VERSION ""

NS_ :

BS_:

BU_: PowertrainControlModule AtmosphericSensor SafetyRestraintSystem2 Aftertreatment_2_GasOutlet Aftertreatment_2_GasIntake DieselParticulateFilterControl Turbocharger SafetyRestraintSystem1 CabDisplay2 Aftertreatment_1_GasOutlet Aftertreatment_1_GasIntake OnBoardDataLogger OffBoardDiagnosticTool2 OffBoardDiagnosticTool1 FileServer ParkingBrakeController SeatController2 FanDriveController SteeringColumnUnit CommunicationUnitRadio CommunicationUnitSatellite CommunicationUnitCellular PropulsionBatteryCharger ChassisController2 ChassisController1 EngineValveControl AuxiliaryHeater2 AuxiliaryHeater1 ClutchUnit RampControl InformationSystem1 SuspensionSystemController2 OilSensor VehicleDynamicStability ExhaustEmissionController TransmissionDisplay2 TransmissionDisplay1 ClimateControl2 WaterPumpController RearAxleSteeringController LightingOperatorControl SeatController1 IgnitionController2 IgnitionController1 TirePressureController CabController2 CabController1 PneumaticSystemController SuspensionSystemController1 HydraulicPumpController EnduranceBrakingSystem RetarderExhaustEngine2 OnBoardDiagnosticUnit HeadwayController RetarderExhaustEngine1 CabDisplay1 ManagementComputer VirtualTerminal OffVehicleGateway PowerTakeOffFront HitchControl AuxiliaryValveControl BodyController TractorTrailerBridge1 StarterSystem ElectricalSystem VehicleSecurity VehicleNavigation AerodynamicControl ElectricalChargingSystem ClimateControl1 TripRecorder InstrumentCluster SuspensionDriveAxle2 SuspensionDriveAxle1 SuspensionSteerAxle SteeringController FuelSystem CruiseControl RetarderDriveline RetarderEngine BrakesDriveAxle2 BrakesDriveAxle1 BrakesSystemController BrakesSteerAxle AxleDrive2 AxleDrive1 AxleSteering PowerTakeOff ShiftConsoleSecondary ShiftConsolePrimary Transmission2 Transmission1 Engine2 Engine1

BO_ 2364677630 HVESP7MS1: 8 Vector__XXX
 SG_ Module32OperationalStatus : 62|2@1+ (1,0) [0|3] "" Vector__XXX
 SG_ Module31OperationalStatus : 60|2@1+ (1,0) [0|3] "" Vector__XXX
 SG_ Module30OperationalStatus : 58|2@1+ (1,0) [0|3] "" Vector__XXX
 SG_ Module29OperationalStatus : 56|2@1+ (1,0) [0|3] "" Vector__XXX
 SG_ Module28OperationalStatus : 54|2@1+ (1,0) [0|3] "" Vector__XXX
 SG_ Module27OperationalStatus : 52|2@1+ (1,0) [0|3] "" Vector__XXX
 SG_ Module26OperationalStatus : 50|2@1+ (1,0) [0|3] "" Vector__XXX
 SG_ Module25OperationalStatus : 48|2@1+ (1,0) [0|3] "" Vector__XXX
 SG_ Module24OperationalStatus : 46|2@1+ (1,0) [0|3] "" Vector__XXX
 SG_ Module23OperationalStatus : 44|2@1+ (1,0) [0|3] "" Vector__XXX
 SG_ Module22OperationalStatus : 42|2@1+ (1,0) [0|3] "" Vector__XXX
 SG_ Module21OperationalStatus : 40|2@1+ (1,0) [0|3] "" Vector__XXX
 SG_ Module20OperationalStatus : 38|2@1+ (1,0) [0|3] "" Vector__XXX
 SG_ Module19OperationalStatus : 36|2@1+ (1,0) [0|3] "" Vector__XXX
 SG_ Module18OperationalStatus : 34|2@1+ (1,0) [0|3] "" Vector__XXX
 SG_ Module17OperationalStatus : 32|2@1+ (1,0) [0|3] "" Vector__XXX
 SG_ Module16OperationalStatus : 30|2@1+ (1,0) [0|3] "" Vector__XXX
 SG_ Module15OperationalStatus : 28|2@1+ (1,0) [0|3] "" Vector__XXX
 SG_ Module14OperationalStatus : 26|2@1+ (1,0) [0|3] "" Vector__XXX
 SG_ Module13OperationalStatus : 24|2@1+ (1,0) [0|3] "" Vector__XXX
 SG_ Module12OperationalStatus : 22|2@1+ (1,0) [0|3] "" Vector__XXX
 SG_ Module11OperationalStatus : 20|2@1+ (1,0) [0|3] "" Vector__XXX
 SG_ Module10OperationalStatus : 18|2@1+ (1,0) [0|3] "" Vector__XXX
 SG_ Module9OperationalStatus : 16|2@1+ (1,0) [0|3] "" Vector__XXX
 SG_ Module8OperationalStatus : 14|2@1+ (1,0) [0|3] "" Vector__XXX
 SG_ Module7OperationalStatus : 12|2@1+ (1,0) [0|3] "" Vector__XXX
 SG_ Module6OperationalStatus : 10|2@1+ (1,0) [0|3] "" Vector__XXX
 SG_ Module5OperationalStatus : 8|2@1+ (1,0) [0|3] "" Vector__XXX
 SG_ Module4OperationalStatus : 6|2@1+ (1,0) [0|3] "" Vector__XXX
 SG_ Module3OperationalStatus : 4|2@1+ (1,0) [0|3] "" Vector__XXX
 SG_ Module2OperationalStatus : 2|2@1+ (1,0) [0|3] "" Vector__XXX
 SG_ Module1OperationalStatus : 0|2@1+ (1,0) [0|3] "" Vector__XXX

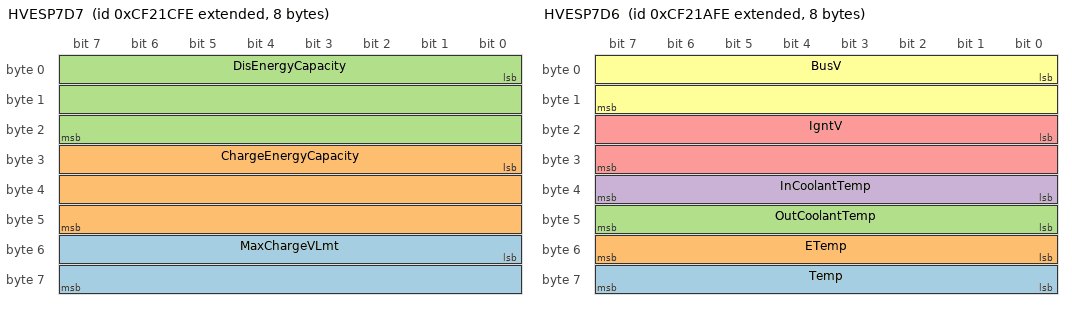
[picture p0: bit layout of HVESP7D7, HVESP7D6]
BO_ 2364677374 HVESP7D7: 8 Vector__XXX
 SG_ MaxChargeVLmt : 48|16@1+ (0.05,0) [0|3212.75] "V" Vector__XXX
 SG_ ChargeEnergyCapacity : 24|24@1+ (0.001,0) [0|16449.535] "kWh" Vector__XXX
 SG_ DisEnergyCapacity : 0|24@1+ (0.001,0) [0|16449.535] "kWh" Vector__XXX

BO_ 2364677118 HVESP7S1: 8 Vector__XXX
 SG_ Status1CRC : 56|8@1+ (1,0) [0|255] "" Vector__XXX
 SG_ Status1Counter : 52|4@1+ (1,0) [0|15] "" Vector__XXX
 SG_ OperationalStatus : 44|4@1+ (1,0) [0|15] "" Vector__XXX
 SG_ HVBusConnectionStatus : 40|4@1+ (1,0) [0|15] "" Vector__XXX
 SG_ InternalChargerStatus : 32|2@1+ (1,0) [0|3] "" Vector__XXX
 SG_ CellBalancingActive : 30|2@1+ (1,0) [0|3] "" Vector__XXX
 SG_ CellBalanceStatus : 28|2@1+ (1,0) [0|3] "" Vector__XXX
 SG_ StOfChargeStatus : 24|4@1+ (1,0) [0|15] "" Vector__XXX
 SG_ InertiaSwStatus : 22|2@1+ (1,0) [0|3] "" Vector__XXX
 SG_ HVILStatus : 20|2@1+ (1,0) [0|3] "" Vector__XXX
 SG_ HVBusPassiveIsolTestStatus : 16|4@1+ (1,0) [0|15] "" Vector__XXX
 SG_ HVBusActiveIsolTestStatus : 12|4@1+ (1,0) [0|15] "" Vector__XXX
 SG_ CenterOfPackContactorSt : 10|2@1+ (1,0) [0|3] "" Vector__XXX
 SG_ HVBusPreChargeRelaySt : 8|2@1+ (1,0) [0|3] "" Vector__XXX
 SG_ HVBusDisconnectForewarning : 4|4@1+ (1,0) [0|15] "" Vector__XXX
 SG_ HVBusContactorSt14086 : 2|2@1+ (1,0) [0|3] "" Vector__XXX
 SG_ HVBusContactorSt : 0|2@1+ (1,0) [0|3] "" Vector__XXX

BO_ 2364676862 HVESP7D6: 8 Vector__XXX
 SG_ Temp : 56|8@1+ (1,-40) [-40|210] "°C" Vector__XXX
 SG_ ETemp : 48|8@1+ (1,-40) [-40|210] "°C" Vector__XXX
 SG_ OutCoolantTemp : 40|8@1+ (1,-40) [-40|210] "°C" Vector__XXX
 SG_ InCoolantTemp : 32|8@1+ (1,-40) [-40|210] "°C" Vector__XXX
 SG_ IgntV : 16|16@1+ (0.01,0) [0|642.55] "V" Vector__XXX
 SG_ BusV : 0|16@1+ (0.05,0) [0|3212.75] "V" Vector__XXX

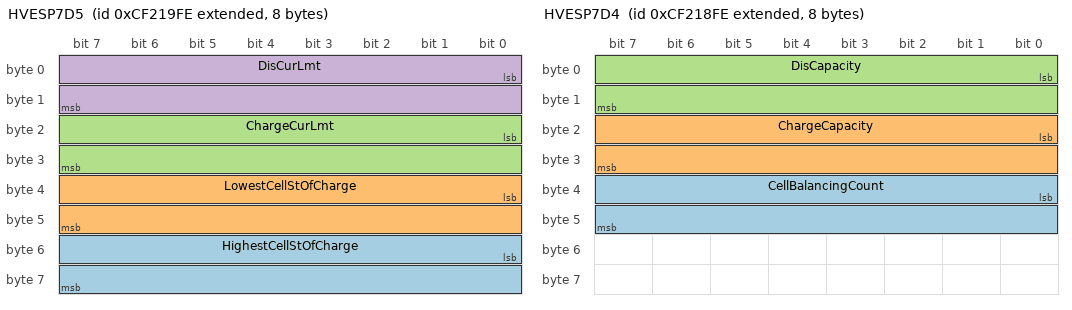
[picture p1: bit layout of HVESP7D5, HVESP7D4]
BO_ 2364676606 HVESP7D5: 8 Vector__XXX
 SG_ HighestCellStOfCharge : 48|16@1+ (0.0015625,0) [0|100.3984375] "%" Vector__XXX
 SG_ LowestCellStOfCharge : 32|16@1+ (0.0015625,0) [0|100.3984375] "%" Vector__XXX
 SG_ ChargeCurLmt : 16|16@1+ (0.05,-1600) [0|1612.75] "A" Vector__XXX
 SG_ DisCurLmt : 0|16@1+ (0.05,-1600) [-1600|0] "A" Vector__XXX

BO_ 2364676350 HVESP7D4: 8 Vector__XXX
 SG_ CellBalancingCount : 32|16@1+ (1,0) [0|64255] "" Vector__XXX
 SG_ ChargeCapacity : 16|16@1+ (0.01,0) [0|642.55] "Ah" Vector__XXX
 SG_ DisCapacity : 0|16@1+ (0.01,0) [0|642.55] "Ah" Vector__XXX

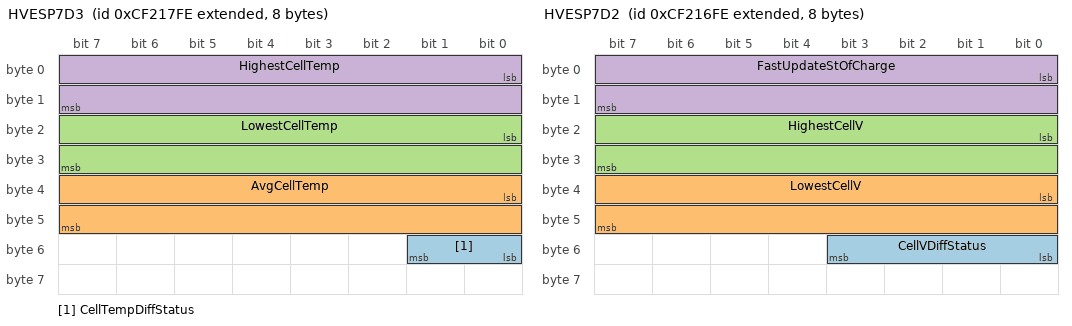
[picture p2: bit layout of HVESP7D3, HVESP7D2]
BO_ 2364676094 HVESP7D3: 8 Vector__XXX
 SG_ CellTempDiffStatus : 48|2@1+ (1,0) [0|3] "" Vector__XXX
 SG_ AvgCellTemp : 32|16@1+ (0.03125,-273) [-273|1734.96875] "°C" Vector__XXX
 SG_ LowestCellTemp : 16|16@1+ (0.03125,-273) [-273|1734.96875] "°C" Vector__XXX
 SG_ HighestCellTemp : 0|16@1+ (0.03125,-273) [-273|1734.96875] "°C" Vector__XXX

BO_ 2364675838 HVESP7D2: 8 Vector__XXX
 SG_ CellVDiffStatus : 48|4@1+ (1,0) [0|15] "" Vector__XXX
 SG_ LowestCellV : 32|16@1+ (0.001,0) [0|64.255] "V" Vector__XXX
 SG_ HighestCellV : 16|16@1+ (0.001,0) [0|64.255] "V" Vector__XXX
 SG_ FastUpdateStOfCharge : 0|16@1+ (0.0015625,0) [0|100.3984375] "%" Vector__XXX

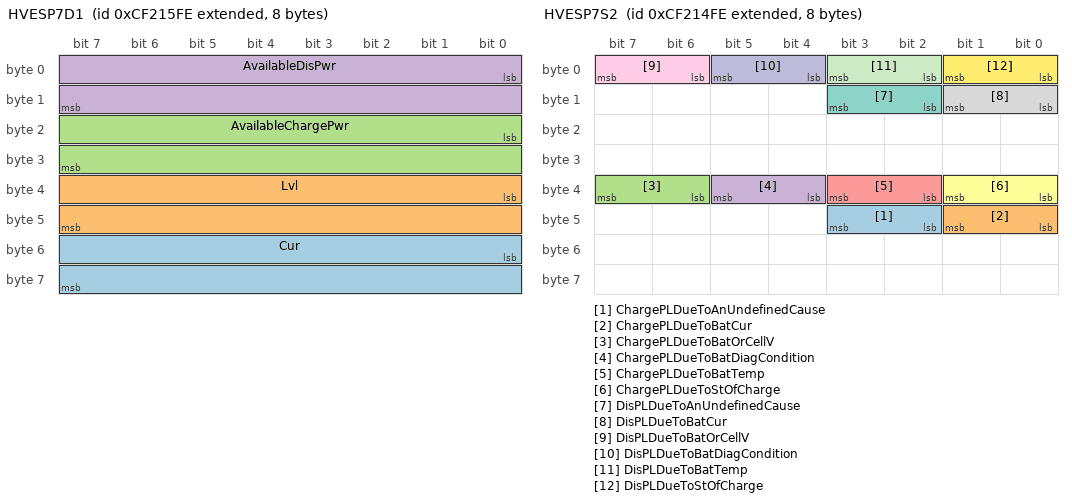
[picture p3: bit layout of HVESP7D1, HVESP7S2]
BO_ 2364675582 HVESP7D1: 8 Vector__XXX
 SG_ Cur : 48|16@1+ (0.05,-1600) [-1600|1612.75] "A" Vector__XXX
 SG_ Lvl : 32|16@1+ (0.05,0) [0|3212.75] "V" Vector__XXX
 SG_ AvailableChargePwr : 16|16@1+ (0.05,0) [0|3212.75] "kW" Vector__XXX
 SG_ AvailableDisPwr : 0|16@1+ (0.05,0) [0|3212.75] "kW" Vector__XXX

BO_ 2364675326 HVESP7S2: 8 Vector__XXX
 SG_ ChargePLDueToAnUndefinedCause : 42|2@1+ (1,0) [0|3] "" Vector__XXX
 SG_ ChargePLDueToBatCur : 40|2@1+ (1,0) [0|3] "" Vector__XXX
 SG_ ChargePLDueToBatOrCellV : 38|2@1+ (1,0) [0|3] "" Vector__XXX
 SG_ ChargePLDueToBatDiagCondition : 36|2@1+ (1,0) [0|3] "" Vector__XXX
 SG_ ChargePLDueToBatTemp : 34|2@1+ (1,0) [0|3] "" Vector__XXX
 SG_ ChargePLDueToStOfCharge : 32|2@1+ (1,0) [0|3] "" Vector__XXX
 SG_ DisPLDueToAnUndefinedCause : 10|2@1+ (1,0) [0|3] "" Vector__XXX
 SG_ DisPLDueToBatCur : 8|2@1+ (1,0) [0|3] "" Vector__XXX
 SG_ DisPLDueToBatOrCellV : 6|2@1+ (1,0) [0|3] "" Vector__XXX
 SG_ DisPLDueToBatDiagCondition : 4|2@1+ (1,0) [0|3] "" Vector__XXX
 SG_ DisPLDueToBatTemp : 2|2@1+ (1,0) [0|3] "" Vector__XXX
 SG_ DisPLDueToStOfCharge : 0|2@1+ (1,0) [0|3] "" Vector__XXX

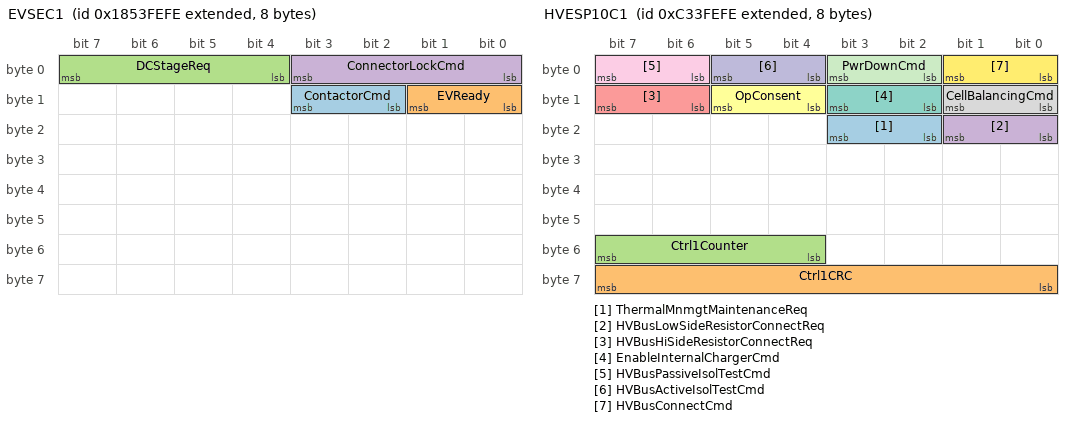
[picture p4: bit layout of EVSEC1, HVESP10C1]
BO_ 2555641598 EVSEC1: 8 Vector__XXX
 SG_ ContactorCmd : 10|2@1+ (1,0) [0|3] "" Vector__XXX
 SG_ EVReady : 8|2@1+ (1,0) [0|3] "" Vector__XXX
 SG_ DCStageReq : 4|4@1+ (1,0) [0|15] "" Vector__XXX
 SG_ ConnectorLockCmd : 0|4@1+ (1,0) [0|15] "" Vector__XXX

BO_ 2555576062 DDT: 1785 Vector__XXX
 SG_ DailyData : 64|1777@1+ (1,0) [0|255] "" Vector__XXX
 SG_ SetID : 48|16@1+ (1,0) [0|255] "" Vector__XXX
 SG_ ManufacturerID : 32|11@1+ (1,0) [0|2047] "" Vector__XXX
 SG_ MessageInstancesRemaining : 16|16@1+ (1,0) [0|65535] "" Vector__XXX
 SG_ MessageInstance : 0|16@1+ (1,0) [0|65535] "" Vector__XXX

BO_ 2555510526 WDT: 1785 Vector__XXX
 SG_ WeeklyData : 64|1777@1+ (1,0) [0|255] "" Vector__XXX
 SG_ SetID : 48|16@1+ (1,0) [0|255] "" Vector__XXX
 SG_ ManufacturerID : 32|11@1+ (1,0) [0|2047] "" Vector__XXX
 SG_ MessageInstancesRemaining : 16|16@1+ (1,0) [0|65535] "" Vector__XXX
 SG_ MessageInstance : 0|16@1+ (1,0) [0|65535] "" Vector__XXX

BO_ 2555444990 MDT: 1785 Vector__XXX
 SG_ MonthlyData : 64|1777@1+ (1,0) [0|255] "" Vector__XXX
 SG_ SetID : 48|16@1+ (1,0) [0|255] "" Vector__XXX
 SG_ ManufacturerID : 32|11@1+ (1,0) [0|2047] "" Vector__XXX
 SG_ MessageInstancesRemaining : 16|16@1+ (1,0) [0|65535] "" Vector__XXX
 SG_ MessageInstance : 0|16@1+ (1,0) [0|65535] "" Vector__XXX

BO_ 2555379454 DTS: 29 Vector__XXX
 SG_ TotalMonthlyMessageBytes : 200|32@1+ (1,0) [0|4294967295] "" Vector__XXX
 SG_ TotalDailyMessageBytes : 56|32@1+ (1,0) [0|4294967295] "" Vector__XXX
 SG_ LongestDailyMessageInstance : 32|24@1+ (1,0) [0|16777215] "" Vector__XXX
 SG_ TotalDailyMessageInstances : 16|16@1+ (1,0) [0|65535] "" Vector__XXX
 SG_ LongestMonthlyMessageInstance : 176|24@1+ (1,0) [0|16777215] "" Vector__XXX
 SG_ TotalMonthlyMessageInstances : 160|16@1+ (1,0) [0|65535] "" Vector__XXX
 SG_ TotalWeeklyMessageBytes : 128|32@1+ (1,0) [0|4294967295] "" Vector__XXX
 SG_ LongestWeeklyMessageInstance : 104|24@1+ (1,0) [0|16777215] "" Vector__XXX
 SG_ TotalWeeklyMessageInstances : 88|16@1+ (1,0) [0|65535] "" Vector__XXX
 SG_ ManufacturerID : 0|11@1+ (1,0) [0|2047] "" Vector__XXX

BO_ 2352217854 HVESP10C1: 8 Vector__XXX
 SG_ ThermalMnmgtMaintenanceReq : 18|2@1+ (1,0) [0|3] "" Vector__XXX
 SG_ Ctrl1CRC : 56|8@1+ (1,0) [0|255] "" Vector__XXX
 SG_ Ctrl1Counter : 52|4@1+ (1,0) [0|15] "" Vector__XXX
 SG_ HVBusLowSideResistorConnectReq : 16|2@1+ (1,0) [0|3] "" Vector__XXX
 SG_ HVBusHiSideResistorConnectReq : 14|2@1+ (1,0) [0|3] "" Vector__XXX
 SG_ OpConsent : 12|2@1+ (1,0) [0|3] "" Vector__XXX
 SG_ EnableInternalChargerCmd : 10|2@1+ (1,0) [0|3] "" Vector__XXX
 SG_ CellBalancingCmd : 8|2@1+ (1,0) [0|3] "" Vector__XXX
 SG_ HVBusPassiveIsolTestCmd : 6|2@1+ (1,0) [0|3] "" Vector__XXX
 SG_ HVBusActiveIsolTestCmd : 4|2@1+ (1,0) [0|3] "" Vector__XXX
 SG_ PwrDownCmd : 2|2@1+ (1,0) [0|3] "" Vector__XXX
 SG_ HVBusConnectCmd : 0|2@1+ (1,0) [0|3] "" Vector__XXX

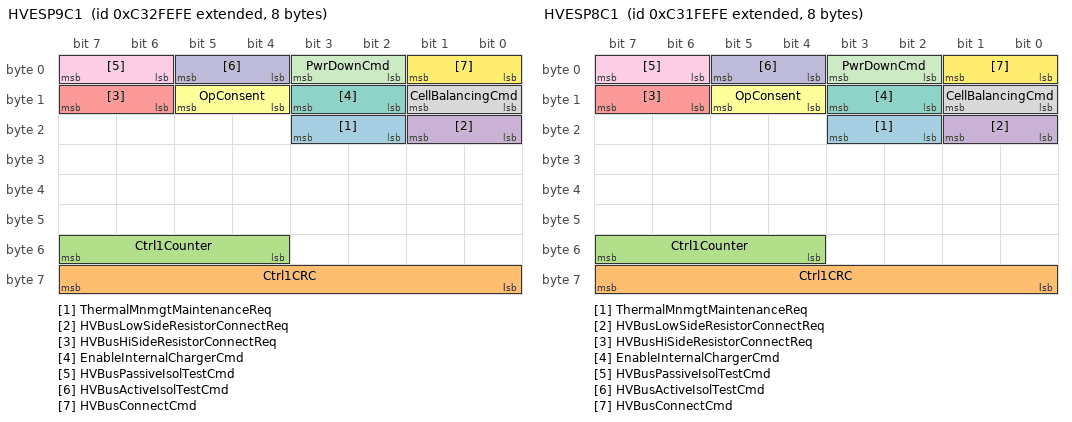
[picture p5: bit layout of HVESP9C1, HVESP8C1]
BO_ 2352152318 HVESP9C1: 8 Vector__XXX
 SG_ ThermalMnmgtMaintenanceReq : 18|2@1+ (1,0) [0|3] "" Vector__XXX
 SG_ Ctrl1CRC : 56|8@1+ (1,0) [0|255] "" Vector__XXX
 SG_ Ctrl1Counter : 52|4@1+ (1,0) [0|15] "" Vector__XXX
 SG_ HVBusLowSideResistorConnectReq : 16|2@1+ (1,0) [0|3] "" Vector__XXX
 SG_ HVBusHiSideResistorConnectReq : 14|2@1+ (1,0) [0|3] "" Vector__XXX
 SG_ OpConsent : 12|2@1+ (1,0) [0|3] "" Vector__XXX
 SG_ EnableInternalChargerCmd : 10|2@1+ (1,0) [0|3] "" Vector__XXX
 SG_ CellBalancingCmd : 8|2@1+ (1,0) [0|3] "" Vector__XXX
 SG_ HVBusPassiveIsolTestCmd : 6|2@1+ (1,0) [0|3] "" Vector__XXX
 SG_ HVBusActiveIsolTestCmd : 4|2@1+ (1,0) [0|3] "" Vector__XXX
 SG_ PwrDownCmd : 2|2@1+ (1,0) [0|3] "" Vector__XXX
 SG_ HVBusConnectCmd : 0|2@1+ (1,0) [0|3] "" Vector__XXX

BO_ 2352086782 HVESP8C1: 8 Vector__XXX
 SG_ ThermalMnmgtMaintenanceReq : 18|2@1+ (1,0) [0|3] "" Vector__XXX
 SG_ Ctrl1CRC : 56|8@1+ (1,0) [0|255] "" Vector__XXX
 SG_ Ctrl1Counter : 52|4@1+ (1,0) [0|15] "" Vector__XXX
 SG_ HVBusLowSideResistorConnectReq : 16|2@1+ (1,0) [0|3] "" Vector__XXX
 SG_ HVBusHiSideResistorConnectReq : 14|2@1+ (1,0) [0|3] "" Vector__XXX
 SG_ OpConsent : 12|2@1+ (1,0) [0|3] "" Vector__XXX
 SG_ EnableInternalChargerCmd : 10|2@1+ (1,0) [0|3] "" Vector__XXX
 SG_ CellBalancingCmd : 8|2@1+ (1,0) [0|3] "" Vector__XXX
 SG_ HVBusPassiveIsolTestCmd : 6|2@1+ (1,0) [0|3] "" Vector__XXX
 SG_ HVBusActiveIsolTestCmd : 4|2@1+ (1,0) [0|3] "" Vector__XXX
 SG_ PwrDownCmd : 2|2@1+ (1,0) [0|3] "" Vector__XXX
 SG_ HVBusConnectCmd : 0|2@1+ (1,0) [0|3] "" Vector__XXX

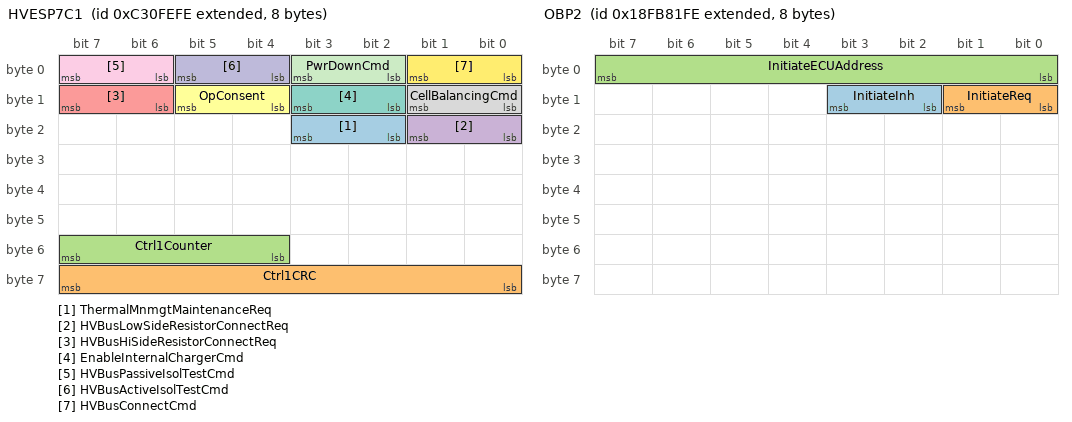
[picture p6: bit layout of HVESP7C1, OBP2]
BO_ 2352021246 HVESP7C1: 8 Vector__XXX
 SG_ ThermalMnmgtMaintenanceReq : 18|2@1+ (1,0) [0|3] "" Vector__XXX
 SG_ Ctrl1CRC : 56|8@1+ (1,0) [0|255] "" Vector__XXX
 SG_ Ctrl1Counter : 52|4@1+ (1,0) [0|15] "" Vector__XXX
 SG_ HVBusLowSideResistorConnectReq : 16|2@1+ (1,0) [0|3] "" Vector__XXX
 SG_ HVBusHiSideResistorConnectReq : 14|2@1+ (1,0) [0|3] "" Vector__XXX
 SG_ OpConsent : 12|2@1+ (1,0) [0|3] "" Vector__XXX
 SG_ EnableInternalChargerCmd : 10|2@1+ (1,0) [0|3] "" Vector__XXX
 SG_ CellBalancingCmd : 8|2@1+ (1,0) [0|3] "" Vector__XXX
 SG_ HVBusPassiveIsolTestCmd : 6|2@1+ (1,0) [0|3] "" Vector__XXX
 SG_ HVBusActiveIsolTestCmd : 4|2@1+ (1,0) [0|3] "" Vector__XXX
 SG_ PwrDownCmd : 2|2@1+ (1,0) [0|3] "" Vector__XXX
 SG_ HVBusConnectCmd : 0|2@1+ (1,0) [0|3] "" Vector__XXX

BO_ 2566619646 OBP2: 8 Vector__XXX
 SG_ InitiateInh : 10|2@1+ (1,0) [0|3] "" Vector__XXX
 SG_ InitiateReq : 8|2@1+ (1,0) [0|3] "" Vector__XXX
 SG_ InitiateECUAddress : 0|8@1+ (1,0) [0|255] "" Vector__XXX

BO_ 2566619390 PTOGC: 22 Vector__XXX
 SG_ AccelOvrdMaxSpd : 160|16@1+ (0.125,0) [0|8031.875] "rpm" Vector__XXX
 SG_ MaxPTOGovSetSpd : 144|16@1+ (0.125,0) [0|8031.875] "rpm" Vector__XXX
 SG_ MinPTOGovSetSpd : 128|16@1+ (0.125,0) [0|8031.875] "rpm" Vector__XXX
 SG_ PreprogrammedPTOGovSetSpd8 : 112|16@1+ (0.125,0) [0|8031.875] "rpm" Vector__XXX
 SG_ PreprogrammedPTOGovSetSpd7 : 96|16@1+ (0.125,0) [0|8031.875] "rpm" Vector__XXX
 SG_ PreprogrammedPTOGovSetSpd6 : 80|16@1+ (0.125,0) [0|8031.875] "rpm" Vector__XXX
 SG_ PreprogrammedPTOGovSetSpd5 : 64|16@1+ (0.125,0) [0|8031.875] "rpm" Vector__XXX
 SG_ PreprogrammedPTOGovSetSpd4 : 48|16@1+ (0.125,0) [0|8031.875] "rpm" Vector__XXX
 SG_ PreprogrammedPTOGovSetSpd3 : 32|16@1+ (0.125,0) [0|8031.875] "rpm" Vector__XXX
 SG_ PreprogrammedPTOGovSetSpd2 : 16|16@1+ (0.125,0) [0|8031.875] "rpm" Vector__XXX
 SG_ PreprogrammedPTOGovSetSpd1 : 0|16@1+ (0.125,0) [0|8031.875] "rpm" Vector__XXX

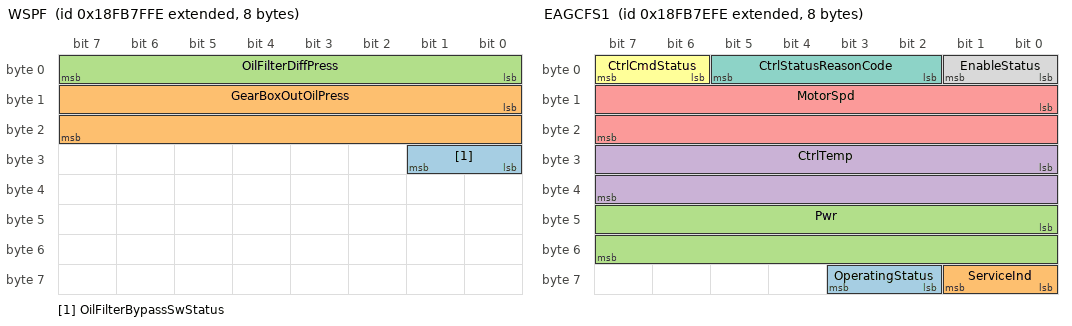
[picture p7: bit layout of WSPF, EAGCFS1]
BO_ 2566619134 WSPF: 8 Vector__XXX
 SG_ OilFilterBypassSwStatus : 24|2@1+ (1,0) [0|3] "" Vector__XXX
 SG_ GearBoxOutOilPress : 8|16@1+ (0.1,0) [0|6425.5] "kPa" Vector__XXX
 SG_ OilFilterDiffPress : 0|8@1+ (4,0) [0|1000] "kPa" Vector__XXX

BO_ 2566618878 EAGCFS1: 8 Vector__XXX
 SG_ OperatingStatus : 58|2@1+ (1,0) [0|3] "" Vector__XXX
 SG_ ServiceInd : 56|2@1+ (1,0) [0|3] "" Vector__XXX
 SG_ Pwr : 40|16@1+ (0.5,0) [0|32127.5] "W" Vector__XXX
 SG_ CtrlTemp : 24|16@1+ (0.03125,-273) [-273|1734.96875] "°C" Vector__XXX
 SG_ MotorSpd : 8|16@1+ (0.5,0) [0|32127.5] "rpm" Vector__XXX
 SG_ CtrlCmdStatus : 6|2@1+ (1,0) [0|3] "" Vector__XXX
 SG_ CtrlStatusReasonCode : 2|4@1+ (1,0) [0|15] "" Vector__XXX
 SG_ EnableStatus : 0|2@1+ (1,0) [0|3] "" Vector__XXX

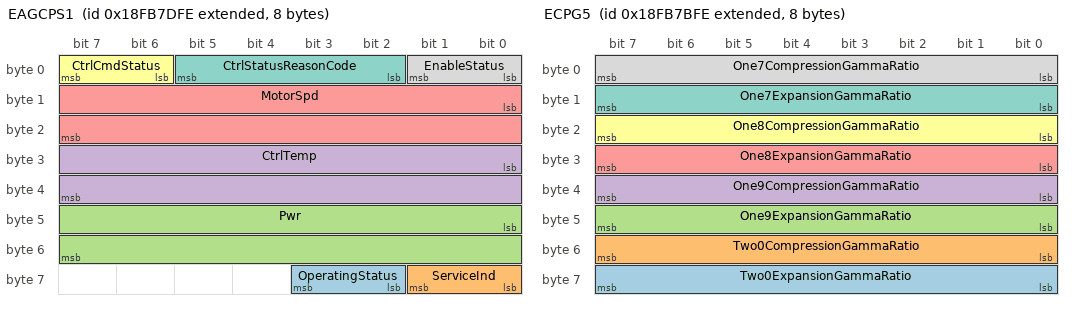
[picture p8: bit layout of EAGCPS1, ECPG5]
BO_ 2566618622 EAGCPS1: 8 Vector__XXX
 SG_ OperatingStatus : 58|2@1+ (1,0) [0|3] "" Vector__XXX
 SG_ ServiceInd : 56|2@1+ (1,0) [0|3] "" Vector__XXX
 SG_ Pwr : 40|16@1+ (0.5,0) [0|32127.5] "W" Vector__XXX
 SG_ CtrlTemp : 24|16@1+ (0.03125,-273) [-273|1734.96875] "°C" Vector__XXX
 SG_ MotorSpd : 8|16@1+ (0.5,0) [0|32127.5] "rpm" Vector__XXX
 SG_ CtrlCmdStatus : 6|2@1+ (1,0) [0|3] "" Vector__XXX
 SG_ CtrlStatusReasonCode : 2|4@1+ (1,0) [0|15] "" Vector__XXX
 SG_ EnableStatus : 0|2@1+ (1,0) [0|3] "" Vector__XXX

BO_ 2566618110 ECPG5: 8 Vector__XXX
 SG_ Two0ExpansionGammaRatio : 56|8@1+ (0.004,1) [1|2] "" Vector__XXX
 SG_ Two0CompressionGammaRatio : 48|8@1+ (0.004,1) [1|2] "" Vector__XXX
 SG_ One9ExpansionGammaRatio : 40|8@1+ (0.004,1) [1|2] "" Vector__XXX
 SG_ One9CompressionGammaRatio : 32|8@1+ (0.004,1) [1|2] "" Vector__XXX
 SG_ One8ExpansionGammaRatio : 24|8@1+ (0.004,1) [1|2] "" Vector__XXX
 SG_ One8CompressionGammaRatio : 16|8@1+ (0.004,1) [1|2] "" Vector__XXX
 SG_ One7ExpansionGammaRatio : 8|8@1+ (0.004,1) [1|2] "" Vector__XXX
 SG_ One7CompressionGammaRatio : 0|8@1+ (0.004,1) [1|2] "" Vector__XXX

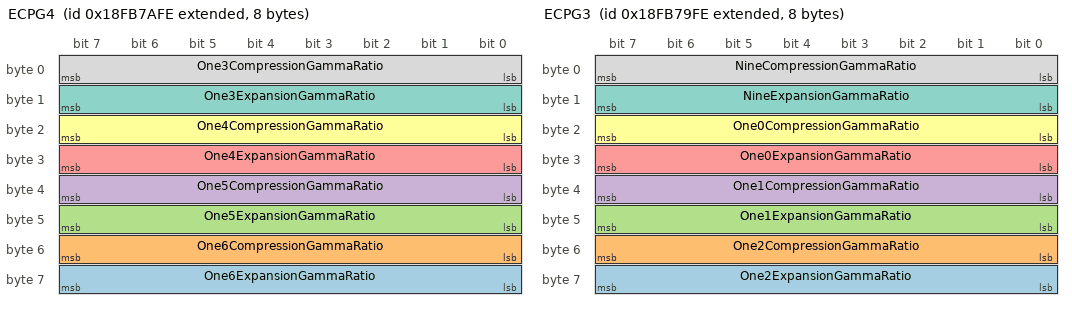
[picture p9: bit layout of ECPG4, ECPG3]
BO_ 2566617854 ECPG4: 8 Vector__XXX
 SG_ One6ExpansionGammaRatio : 56|8@1+ (0.004,1) [1|2] "" Vector__XXX
 SG_ One6CompressionGammaRatio : 48|8@1+ (0.004,1) [1|2] "" Vector__XXX
 SG_ One5ExpansionGammaRatio : 40|8@1+ (0.004,1) [1|2] "" Vector__XXX
 SG_ One5CompressionGammaRatio : 32|8@1+ (0.004,1) [1|2] "" Vector__XXX
 SG_ One4ExpansionGammaRatio : 24|8@1+ (0.004,1) [1|2] "" Vector__XXX
 SG_ One4CompressionGammaRatio : 16|8@1+ (0.004,1) [1|2] "" Vector__XXX
 SG_ One3ExpansionGammaRatio : 8|8@1+ (0.004,1) [1|2] "" Vector__XXX
 SG_ One3CompressionGammaRatio : 0|8@1+ (0.004,1) [1|2] "" Vector__XXX

BO_ 2566617598 ECPG3: 8 Vector__XXX
 SG_ One2ExpansionGammaRatio : 56|8@1+ (0.004,1) [1|2] "" Vector__XXX
 SG_ One2CompressionGammaRatio : 48|8@1+ (0.004,1) [1|2] "" Vector__XXX
 SG_ One1ExpansionGammaRatio : 40|8@1+ (0.004,1) [1|2] "" Vector__XXX
 SG_ One1CompressionGammaRatio : 32|8@1+ (0.004,1) [1|2] "" Vector__XXX
 SG_ One0ExpansionGammaRatio : 24|8@1+ (0.004,1) [1|2] "" Vector__XXX
 SG_ One0CompressionGammaRatio : 16|8@1+ (0.004,1) [1|2] "" Vector__XXX
 SG_ NineExpansionGammaRatio : 8|8@1+ (0.004,1) [1|2] "" Vector__XXX
 SG_ NineCompressionGammaRatio : 0|8@1+ (0.004,1) [1|2] "" Vector__XXX

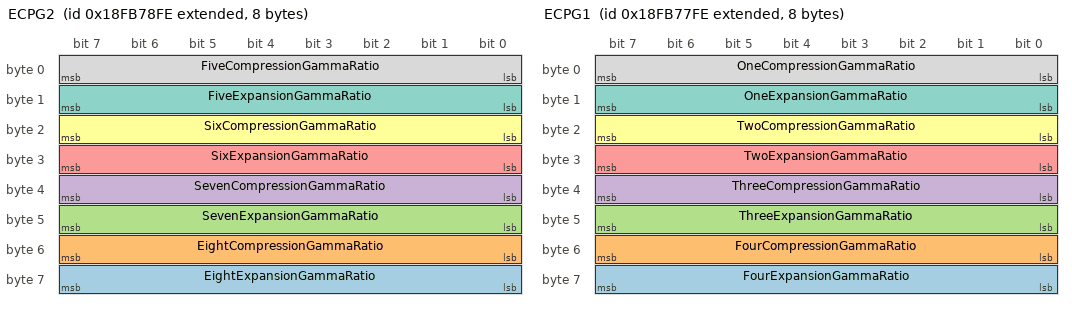
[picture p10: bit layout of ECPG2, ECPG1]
BO_ 2566617342 ECPG2: 8 Vector__XXX
 SG_ EightExpansionGammaRatio : 56|8@1+ (0.004,1) [1|2] "" Vector__XXX
 SG_ EightCompressionGammaRatio : 48|8@1+ (0.004,1) [1|2] "" Vector__XXX
 SG_ SevenExpansionGammaRatio : 40|8@1+ (0.004,1) [1|2] "" Vector__XXX
 SG_ SevenCompressionGammaRatio : 32|8@1+ (0.004,1) [1|2] "" Vector__XXX
 SG_ SixExpansionGammaRatio : 24|8@1+ (0.004,1) [1|2] "" Vector__XXX
 SG_ SixCompressionGammaRatio : 16|8@1+ (0.004,1) [1|2] "" Vector__XXX
 SG_ FiveExpansionGammaRatio : 8|8@1+ (0.004,1) [1|2] "" Vector__XXX
 SG_ FiveCompressionGammaRatio : 0|8@1+ (0.004,1) [1|2] "" Vector__XXX

BO_ 2566617086 ECPG1: 8 Vector__XXX
 SG_ FourExpansionGammaRatio : 56|8@1+ (0.004,1) [1|2] "" Vector__XXX
 SG_ FourCompressionGammaRatio : 48|8@1+ (0.004,1) [1|2] "" Vector__XXX
 SG_ ThreeExpansionGammaRatio : 40|8@1+ (0.004,1) [1|2] "" Vector__XXX
 SG_ ThreeCompressionGammaRatio : 32|8@1+ (0.004,1) [1|2] "" Vector__XXX
 SG_ TwoExpansionGammaRatio : 24|8@1+ (0.004,1) [1|2] "" Vector__XXX
 SG_ TwoCompressionGammaRatio : 16|8@1+ (0.004,1) [1|2] "" Vector__XXX
 SG_ OneExpansionGammaRatio : 8|8@1+ (0.004,1) [1|2] "" Vector__XXX
 SG_ OneCompressionGammaRatio : 0|8@1+ (0.004,1) [1|2] "" Vector__XXX

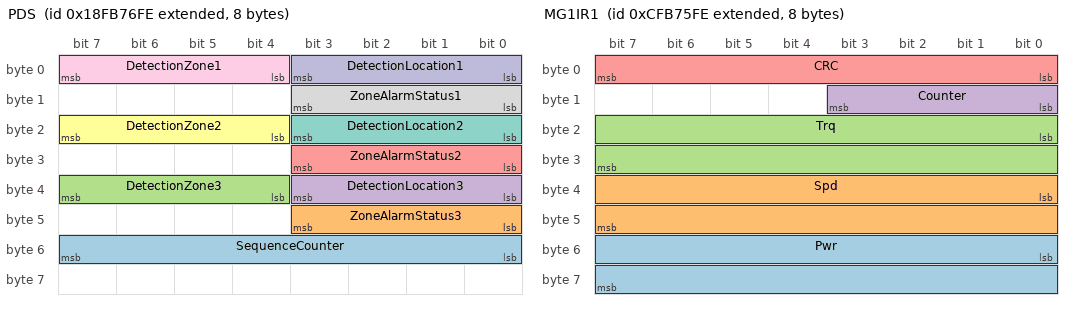
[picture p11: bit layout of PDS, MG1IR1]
BO_ 2566616830 PDS: 8 Vector__XXX
 SG_ SequenceCounter : 48|8@1+ (1,0) [0|255] "" Vector__XXX
 SG_ ZoneAlarmStatus3 : 40|4@1+ (1,0) [0|15] "" Vector__XXX
 SG_ DetectionZone3 : 36|4@1+ (1,0) [0|13] "" Vector__XXX
 SG_ DetectionLocation3 : 32|4@1+ (1,0) [0|13] "" Vector__XXX
 SG_ ZoneAlarmStatus2 : 24|4@1+ (1,0) [0|15] "" Vector__XXX
 SG_ DetectionZone2 : 20|4@1+ (1,0) [0|13] "" Vector__XXX
 SG_ DetectionLocation2 : 16|4@1+ (1,0) [0|13] "" Vector__XXX
 SG_ ZoneAlarmStatus1 : 8|4@1+ (1,0) [0|15] "" Vector__XXX
 SG_ DetectionZone1 : 4|4@1+ (1,0) [0|13] "" Vector__XXX
 SG_ DetectionLocation1 : 0|4@1+ (1,0) [0|13] "" Vector__XXX

BO_ 2365289982 MG1IR1: 8 Vector__XXX
 SG_ Pwr : 48|16@1+ (0.0625,0) [0|4015.9375] "kW" Vector__XXX
 SG_ Spd : 32|16@1+ (4,0) [0|257020] "rpm" Vector__XXX
 SG_ Trq : 16|16@1+ (0.5,0) [0|32127.5] "Nm" Vector__XXX
 SG_ Counter : 8|4@1+ (1,0) [0|15] "" Vector__XXX
 SG_ CRC : 0|8@1+ (1,0) [0|255] "" Vector__XXX

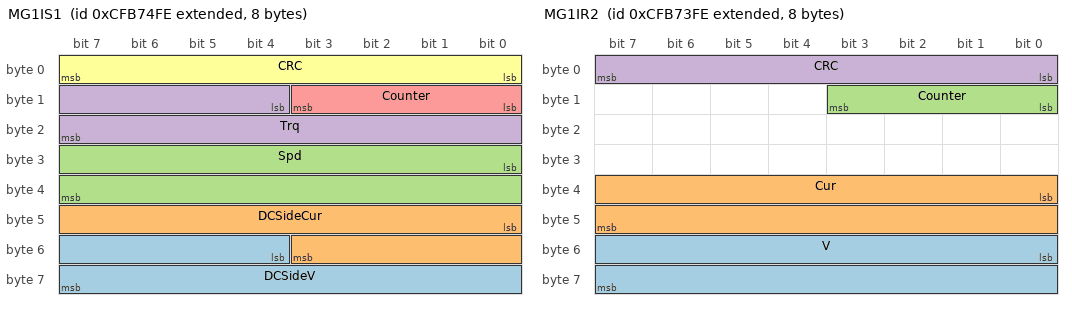
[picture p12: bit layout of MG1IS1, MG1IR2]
BO_ 2365289726 MG1IS1: 8 Vector__XXX
 SG_ DCSideV : 52|12@1+ (0.0625,-125) [-125|125.9375] "%" Vector__XXX
 SG_ DCSideCur : 40|12@1+ (0.0625,-125) [-125|125.9375] "%" Vector__XXX
 SG_ Spd : 24|16@1+ (0.00390625,-125) [-125|125.99609375] "%" Vector__XXX
 SG_ Trq : 12|12@1+ (0.0625,-125) [-125|125.9375] "%" Vector__XXX
 SG_ Counter : 8|4@1+ (1,0) [0|15] "" Vector__XXX
 SG_ CRC : 0|8@1+ (1,0) [0|255] "" Vector__XXX

BO_ 2365289470 MG1IR2: 8 Vector__XXX
 SG_ V : 48|16@1+ (0.125,0) [0|8031.875] "V" Vector__XXX
 SG_ Cur : 32|16@1+ (0.125,0) [0|8031.875] "A" Vector__XXX
 SG_ Counter : 8|4@1+ (1,0) [0|15] "" Vector__XXX
 SG_ CRC : 0|8@1+ (1,0) [0|255] "" Vector__XXX

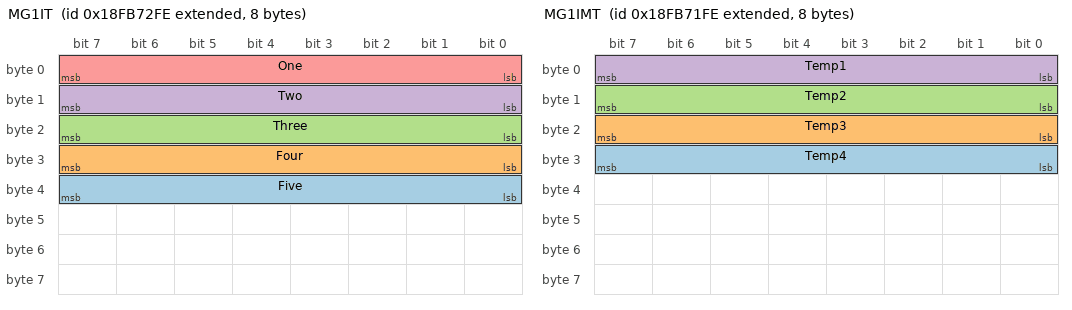
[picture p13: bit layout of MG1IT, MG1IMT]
BO_ 2566615806 MG1IT: 8 Vector__XXX
 SG_ Five : 32|8@1+ (1,-40) [-40|210] "°C" Vector__XXX
 SG_ Four : 24|8@1+ (1,-40) [-40|210] "°C" Vector__XXX
 SG_ Three : 16|8@1+ (1,-40) [-40|210] "°C" Vector__XXX
 SG_ Two : 8|8@1+ (1,-40) [-40|210] "°C" Vector__XXX
 SG_ One : 0|8@1+ (1,-40) [-40|210] "°C" Vector__XXX

BO_ 2566615550 MG1IMT: 8 Vector__XXX
 SG_ Temp4 : 24|8@1+ (1,-40) [-40|210] "°C" Vector__XXX
 SG_ Temp3 : 16|8@1+ (1,-40) [-40|210] "°C" Vector__XXX
 SG_ Temp2 : 8|8@1+ (1,-40) [-40|210] "°C" Vector__XXX
 SG_ Temp1 : 0|8@1+ (1,-40) [-40|210] "°C" Vector__XXX

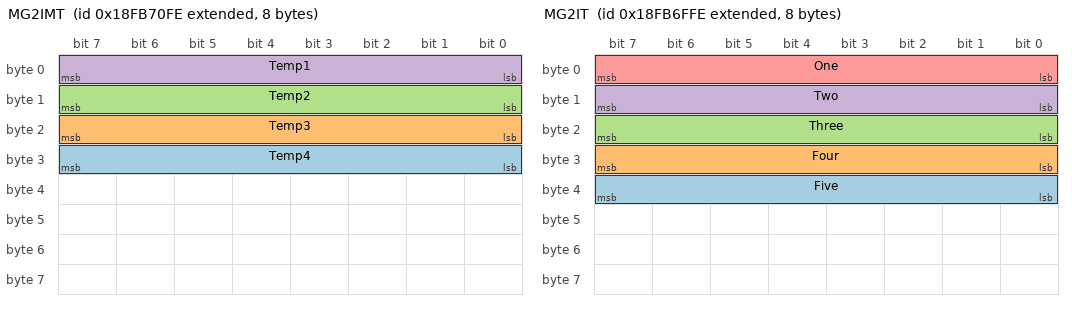
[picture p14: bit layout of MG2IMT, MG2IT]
BO_ 2566615294 MG2IMT: 8 Vector__XXX
 SG_ Temp4 : 24|8@1+ (1,-40) [-40|210] "°C" Vector__XXX
 SG_ Temp3 : 16|8@1+ (1,-40) [-40|210] "°C" Vector__XXX
 SG_ Temp2 : 8|8@1+ (1,-40) [-40|210] "°C" Vector__XXX
 SG_ Temp1 : 0|8@1+ (1,-40) [-40|210] "°C" Vector__XXX

BO_ 2566615038 MG2IT: 8 Vector__XXX
 SG_ Five : 32|8@1+ (1,-40) [-40|210] "°C" Vector__XXX
 SG_ Four : 24|8@1+ (1,-40) [-40|210] "°C" Vector__XXX
 SG_ Three : 16|8@1+ (1,-40) [-40|210] "°C" Vector__XXX
 SG_ Two : 8|8@1+ (1,-40) [-40|210] "°C" Vector__XXX
 SG_ One : 0|8@1+ (1,-40) [-40|210] "°C" Vector__XXX

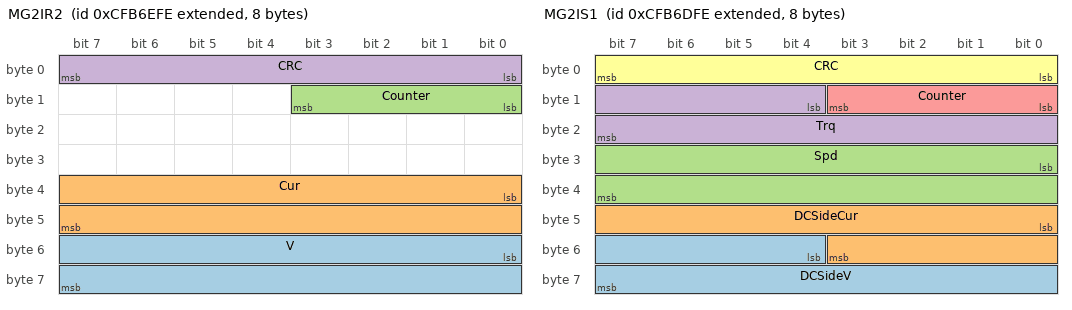
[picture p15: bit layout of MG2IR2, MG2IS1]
BO_ 2365288190 MG2IR2: 8 Vector__XXX
 SG_ V : 48|16@1+ (0.125,0) [0|8031.875] "V" Vector__XXX
 SG_ Cur : 32|16@1+ (0.125,0) [0|8031.875] "A" Vector__XXX
 SG_ Counter : 8|4@1+ (1,0) [0|15] "" Vector__XXX
 SG_ CRC : 0|8@1+ (1,0) [0|255] "" Vector__XXX

BO_ 2365287934 MG2IS1: 8 Vector__XXX
 SG_ DCSideV : 52|12@1+ (0.0625,-125) [-125|125.9375] "%" Vector__XXX
 SG_ DCSideCur : 40|12@1+ (0.0625,-125) [-125|125.9375] "%" Vector__XXX
 SG_ Spd : 24|16@1+ (0.00390625,-125) [-125|125.99609375] "%" Vector__XXX
 SG_ Trq : 12|12@1+ (0.0625,-125) [-125|125.9375] "%" Vector__XXX
 SG_ Counter : 8|4@1+ (1,0) [0|15] "" Vector__XXX
 SG_ CRC : 0|8@1+ (1,0) [0|255] "" Vector__XXX

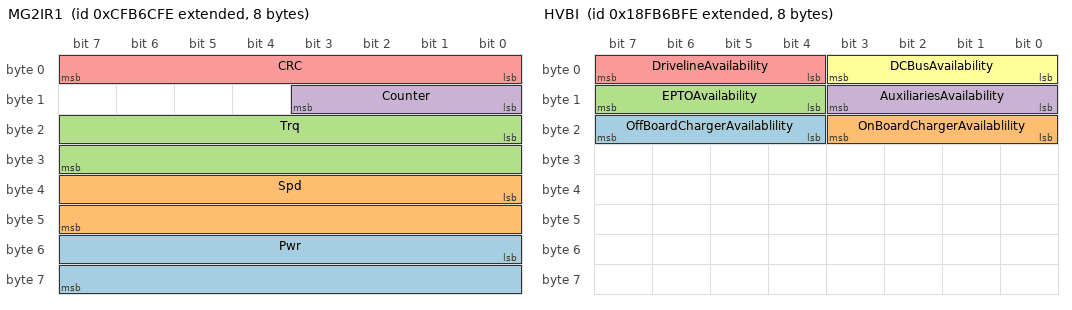
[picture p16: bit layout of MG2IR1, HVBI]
BO_ 2365287678 MG2IR1: 8 Vector__XXX
 SG_ Pwr : 48|16@1+ (0.0625,0) [0|4015.9375] "kW" Vector__XXX
 SG_ Spd : 32|16@1+ (4,0) [0|257020] "rpm" Vector__XXX
 SG_ Trq : 16|16@1+ (0.5,0) [0|32127.5] "Nm" Vector__XXX
 SG_ Counter : 8|4@1+ (1,0) [0|15] "" Vector__XXX
 SG_ CRC : 0|8@1+ (1,0) [0|255] "" Vector__XXX

BO_ 2566614014 HVBI: 8 Vector__XXX
 SG_ OffBoardChargerAvailablility : 20|4@1+ (1,0) [0|15] "" Vector__XXX
 SG_ OnBoardChargerAvailablility : 16|4@1+ (1,0) [0|15] "" Vector__XXX
 SG_ EPTOAvailability : 12|4@1+ (1,0) [0|15] "" Vector__XXX
 SG_ AuxiliariesAvailability : 8|4@1+ (1,0) [0|15] "" Vector__XXX
 SG_ DrivelineAvailability : 4|4@1+ (1,0) [0|15] "" Vector__XXX
 SG_ DCBusAvailability : 0|4@1+ (1,0) [0|15] "" Vector__XXX

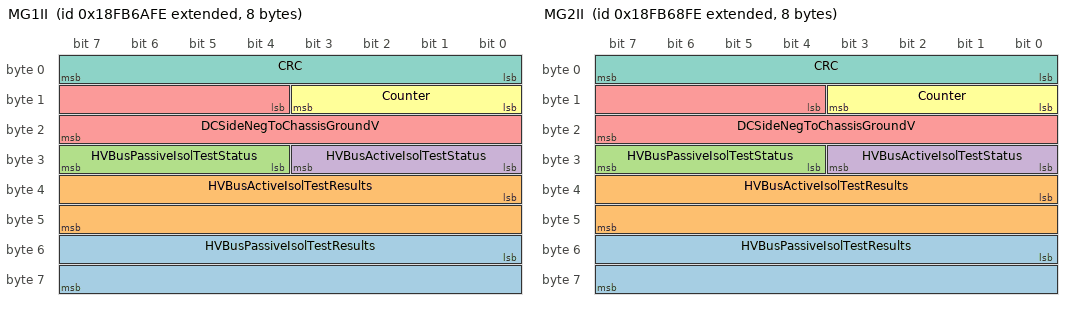
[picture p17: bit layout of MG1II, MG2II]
BO_ 2566613758 MG1II: 8 Vector__XXX
 SG_ HVBusPassiveIsolTestResults : 48|16@1+ (0.1,0) [0|6425.5] "Ohm/V" Vector__XXX
 SG_ HVBusActiveIsolTestResults : 32|16@1+ (0.1,0) [0|6425.5] "Ohm/V" Vector__XXX
 SG_ HVBusPassiveIsolTestStatus : 28|4@1+ (1,0) [0|15] "" Vector__XXX
 SG_ HVBusActiveIsolTestStatus : 24|4@1+ (1,0) [0|15] "" Vector__XXX
 SG_ DCSideNegToChassisGroundV : 12|12@1+ (0.0625,-125) [-125|125.9375] "%" Vector__XXX
 SG_ Counter : 8|4@1+ (1,0) [0|15] "" Vector__XXX
 SG_ CRC : 0|8@1+ (1,0) [0|255] "" Vector__XXX

BO_ 2566613502 MG1IAPL: 8 Vector__XXX
 SG_ TrqLimDueToMachineCharacteristic : 38|2@1+ (1,0) [0|3] "" Vector__XXX
 SG_ PLedDueToActiveSpdRateLmt : 36|2@1+ (1,0) [0|3] "" Vector__XXX
 SG_ PLedDueToActiveTrqRateLmt : 34|2@1+ (1,0) [0|3] "" Vector__XXX
 SG_ PLedDueToFaultCondition : 32|2@1+ (1,0) [0|3] "" Vector__XXX
 SG_ PLedDueToMotorTemp : 30|2@1+ (1,0) [0|3] "" Vector__XXX
 SG_ PLedDueToInvTemp : 28|2@1+ (1,0) [0|3] "" Vector__XXX
 SG_ PLedDueToSpdMin : 24|2@1+ (1,0) [0|3] "" Vector__XXX
 SG_ PLedDueToSpdMax : 22|2@1+ (1,0) [0|3] "" Vector__XXX
 SG_ PLedDueToTrqMin : 20|2@1+ (1,0) [0|3] "" Vector__XXX
 SG_ PLedDueToTrqMax : 18|2@1+ (1,0) [0|3] "" Vector__XXX
 SG_ PLedDueToDCSidePwrMin : 16|2@1+ (1,0) [0|3] "" Vector__XXX
 SG_ PLedDueToDCSidePwrMax : 14|2@1+ (1,0) [0|3] "" Vector__XXX
 SG_ PLedDueToMechPwrMin : 12|2@1+ (1,0) [0|3] "" Vector__XXX
 SG_ PLedDueToMechPwrMax : 10|2@1+ (1,0) [0|3] "" Vector__XXX
 SG_ PLedDueToDCSideVMin : 8|2@1+ (1,0) [0|3] "" Vector__XXX
 SG_ PLedDueToDCSideVMax : 6|2@1+ (1,0) [0|3] "" Vector__XXX
 SG_ PLedDueToDCSideCurMin : 4|2@1+ (1,0) [0|3] "" Vector__XXX
 SG_ PLedDueToDCSideCurMax : 2|2@1+ (1,0) [0|3] "" Vector__XXX
 SG_ PLedDueToUndefinedReason : 0|2@1+ (1,0) [0|3] "" Vector__XXX

BO_ 2566613246 MG2II: 8 Vector__XXX
 SG_ HVBusPassiveIsolTestResults : 48|16@1+ (0.1,0) [0|6425.5] "Ohm/V" Vector__XXX
 SG_ HVBusActiveIsolTestResults : 32|16@1+ (0.1,0) [0|6425.5] "Ohm/V" Vector__XXX
 SG_ HVBusPassiveIsolTestStatus : 28|4@1+ (1,0) [0|15] "" Vector__XXX
 SG_ HVBusActiveIsolTestStatus : 24|4@1+ (1,0) [0|15] "" Vector__XXX
 SG_ DCSideNegToChassisGroundV : 12|12@1+ (0.0625,-125) [-125|125.9375] "%" Vector__XXX
 SG_ Counter : 8|4@1+ (1,0) [0|15] "" Vector__XXX
 SG_ CRC : 0|8@1+ (1,0) [0|255] "" Vector__XXX

CM_ BO_ 2364677630 "High Voltage Energy Storage Pack 7 Module Status 1
Module Status message 1 for High Voltage Energy Storage Pack 7.";
CM_ SG_ 2364677630 Module32OperationalStatus "Operational Status of Module 32 in this High Voltage Energy Storage Pack Instance.  Not Operational is used when the module is initializing or not able to function (e.g. internal module level monitors have failed).  Operational indicates that the ...";
CM_ SG_ 2364677630 Module31OperationalStatus "Operational Status of Module 31 in this High Voltage Energy Storage Pack Instance.  Not Operational is used when the module is initializing or not able to function (e.g. internal module level monitors have failed).  Operational indicates that the ...";
CM_ SG_ 2364677630 Module30OperationalStatus "Operational Status of Module 30 in this High Voltage Energy Storage Pack Instance.  Not Operational is used when the module is initializing or not able to function (e.g. internal module level monitors have failed).  Operational indicates that the ...";
CM_ SG_ 2364677630 Module29OperationalStatus "Operational Status of Module 29 in this High Voltage Energy Storage Pack Instance.  Not Operational is used when the module is initializing or not able to function (e.g. internal module level monitors have failed).  Operational indicates that the ...";
CM_ SG_ 2364677630 Module28OperationalStatus "Operational Status of Module 28 in this High Voltage Energy Storage Pack Instance.  Not Operational is used when the module is initializing or not able to function (e.g. internal module level monitors have failed).  Operational indicates that the ...";
CM_ SG_ 2364677630 Module27OperationalStatus "Operational Status of Module 27 in this High Voltage Energy Storage Pack Instance.  Not Operational is used when the module is initializing or not able to function (e.g. internal module level monitors have failed).  Operational indicates that the ...";
CM_ SG_ 2364677630 Module26OperationalStatus "Operational Status of Module 26 in this High Voltage Energy Storage Pack Instance.  Not Operational is used when the module is initializing or not able to function (e.g. internal module level monitors have failed).  Operational indicates that the ...";
CM_ SG_ 2364677630 Module25OperationalStatus "Operational Status of Module 25 in this High Voltage Energy Storage Pack Instance.  Not Operational is used when the module is initializing or not able to function (e.g. internal module level monitors have failed).  Operational indicates that the ...";
CM_ SG_ 2364677630 Module24OperationalStatus "Operational Status of Module 24 in this High Voltage Energy Storage Pack Instance.  Not Operational is used when the module is initializing or not able to function (e.g. internal module level monitors have failed).  Operational indicates that the ...";
CM_ SG_ 2364677630 Module23OperationalStatus "Operational Status of Module 23 in this High Voltage Energy Storage Pack Instance.  Not Operational is used when the module is initializing or not able to function (e.g. internal module level monitors have failed).  Operational indicates that the ...";
CM_ SG_ 2364677630 Module22OperationalStatus "Operational Status of Module 22 in this High Voltage Energy Storage Pack Instance.  Not Operational is used when the module is initializing or not able to function (e.g. internal module level monitors have failed).  Operational indicates that the ...";
CM_ SG_ 2364677630 Module21OperationalStatus "Operational Status of Module 21 in this High Voltage Energy Storage Pack Instance.  Not Operational is used when the module is initializing or not able to function (e.g. internal module level monitors have failed).  Operational indicates that the ...";
CM_ SG_ 2364677630 Module20OperationalStatus "Operational Status of Module 20 in this High Voltage Energy Storage Pack Instance.  Not Operational is used when the module is initializing or not able to function (e.g. internal module level monitors have failed).  Operational indicates that the ...";
CM_ SG_ 2364677630 Module19OperationalStatus "Operational Status of Module 19 in this High Voltage Energy Storage Pack Instance.  Not Operational is used when the module is initializing or not able to function (e.g. internal module level monitors have failed).  Operational indicates that the ...";
CM_ SG_ 2364677630 Module18OperationalStatus "Operational Status of Module 18 in this High Voltage Energy Storage Pack Instance.  Not Operational is used when the module is initializing or not able to function (e.g. internal module level monitors have failed).  Operational indicates that the ...";
CM_ SG_ 2364677630 Module17OperationalStatus "Operational Status of Module 17 in this High Voltage Energy Storage Pack Instance.  Not Operational is used when the module is initializing or not able to function (e.g. internal module level monitors have failed).  Operational indicates that the ...";
CM_ SG_ 2364677630 Module16OperationalStatus "Operational Status of Module 16 in this High Voltage Energy Storage Pack Instance.  Not Operational is used when the module is initializing or not able to function (e.g. internal module level monitors have failed).  Operational indicates that the ...";
CM_ SG_ 2364677630 Module15OperationalStatus "Operational Status of Module 15 in this High Voltage Energy Storage Pack Instance.  Not Operational is used when the module is initializing or not able to function (e.g. internal module level monitors have failed).  Operational indicates that the ...";
CM_ SG_ 2364677630 Module14OperationalStatus "Operational Status of Module 14 in this High Voltage Energy Storage Pack Instance.  Not Operational is used when the module is initializing or not able to function (e.g. internal module level monitors have failed).  Operational indicates that the ...";
CM_ SG_ 2364677630 Module13OperationalStatus "Operational Status of Module 13 in this High Voltage Energy Storage Pack Instance.  Not Operational is used when the module is initializing or not able to function (e.g. internal module level monitors have failed).  Operational indicates that the ...";
CM_ SG_ 2364677630 Module12OperationalStatus "Operational Status of Module 12 in this High Voltage Energy Storage Pack Instance.  Not Operational is used when the module is initializing or not able to function (e.g. internal module level monitors have failed).  Operational indicates that the ...";
CM_ SG_ 2364677630 Module11OperationalStatus "Operational Status of Module 11 in this High Voltage Energy Storage Pack Instance.  Not Operational is used when the module is initializing or not able to function (e.g. internal module level monitors have failed).  Operational indicates that the ...";
CM_ SG_ 2364677630 Module10OperationalStatus "Operational Status of Module 10 in this High Voltage Energy Storage Pack Instance.  Not Operational is used when the module is initializing or not able to function (e.g. internal module level monitors have failed).  Operational indicates that the ...";
CM_ SG_ 2364677630 Module9OperationalStatus "Operational Status of Module 9 in this High Voltage Energy Storage Pack Instance.  Not Operational is used when the module is initializing or not able to function (e.g. internal module level monitors have failed).  Operational indicates that the ...";
CM_ SG_ 2364677630 Module8OperationalStatus "Operational Status of Module 8 in this High Voltage Energy Storage Pack Instance.  Not Operational is used when the module is initializing or not able to function (e.g. internal module level monitors have failed).  Operational indicates that the ...";
CM_ SG_ 2364677630 Module7OperationalStatus "Operational Status of Module 7 in this High Voltage Energy Storage Pack Instance.  Not Operational is used when the module is initializing or not able to function (e.g. internal module level monitors have failed).  Operational indicates that the ...";
CM_ SG_ 2364677630 Module6OperationalStatus "Operational Status of Module 6 in this High Voltage Energy Storage Pack Instance.  Not Operational is used when the module is initializing or not able to function (e.g. internal module level monitors have failed).  Operational indicates that the ...";
CM_ SG_ 2364677630 Module5OperationalStatus "Operational Status of Module 5 in this High Voltage Energy Storage Pack Instance.  Not Operational is used when the module is initializing or not able to function (e.g. internal module level monitors have failed).  Operational indicates that the ...";
CM_ SG_ 2364677630 Module4OperationalStatus "Operational Status of Module 4 in this High Voltage Energy Storage Pack Instance.  Not Operational is used when the module is initializing or not able to function (e.g. internal module level monitors have failed).  Operational indicates that the ...";
CM_ SG_ 2364677630 Module3OperationalStatus "Operational Status of Module 3 in this High Voltage Energy Storage Pack Instance.  Not Operational is used when the module is initializing or not able to function (e.g. internal module level monitors have failed).  Operational indicates that the ...";
CM_ SG_ 2364677630 Module2OperationalStatus "Operational Status of Module 2 in this High Voltage Energy Storage Pack Instance.  Not Operational is used when the module is initializing or not able to function (e.g. internal module level monitors have failed).  Operational indicates that the ...";
CM_ SG_ 2364677630 Module1OperationalStatus "Operational Status of Module 1 in this High Voltage Energy Storage Pack Instance.  Not Operational is used when the module is initializing or not able to function (e.g. internal module level monitors have failed).  Operational indicates that the ...";
CM_ BO_ 2364677374 "High Voltage Energy Storage Pack 7 Data 7
Data set 7 (electrical) for High Voltage Energy Storage Pack 7.";
CM_ SG_ 2364677374 MaxChargeVLmt "The maximum voltage level not to be exceeded while charging this High Voltage Energy Storage Pack instance. If this parameter is not supported, the maximum charge voltage should be limited to SPN 14173 (HVESP7 Recommended Maximum Operating Voltage).
 ...";
CM_ SG_ 2364677374 ChargeEnergyCapacity "The amount of unused electrical energy storage available to be filled by charging this High Voltage Energy Storage Pack instance, i.e. “how much empty space is remaining in the tank”. See SPN 14073 (HVESP7 Charge Capacity) for Ampere-hours (Ah).
 ...";
CM_ SG_ 2364677374 DisEnergyCapacity "The amount of stored electrical energy in this High Voltage Energy Storage Pack instance that is available for use by the hybrid system, i.e. “how full is the tank”. See SPN 14072 (HVESP7 Discharge Capacity) for Ampere-hours (Ah).
This parameter is ...";
CM_ BO_ 2364677118 "High Voltage Energy Storage Pack 7 Status 1
Status data set 1 for High Voltage Energy Storage Pack 7.";
CM_ SG_ 2364677118 Status1CRC "The CRC is defined as follows:
• Length: 8 bits
• Polynomial: x^8+x^5+x^3+x^2+x+1
• Initial Value: FFh
• Input Data Reflection: Not reflected
• Result Data Reflection: Not reflected
• XOR value: FFh
SAE makes no claim of the functional safety ...";
CM_ SG_ 2364677118 Status1Counter "The message counter is used to detect situations where the transmitting ECU malfunction repeats the same frame all the time. The receiver of the information may use the counter parameter to detect this situation. The transmitting device will ...";
CM_ SG_ 2364677118 OperationalStatus "Provides feedback on where this High Voltage Energy Storage Pack instance is in its operating spectrum, and includes feedback in response to the Operation Consent [i.e. SPN 14043 (HVESP7 Operation Consent)] and Power Down Command [i.e. SPN 14038 ...";
CM_ SG_ 2364677118 HVBusConnectionStatus "This parameter provides high level feedback on this High Voltage Energy Storage Pack instance high voltage bus connection. For specific contactor information, see SPN 14085 (HVESP7 High-Voltage Bus (Positive) Contactor State), SPN 14086 (HVESP7 ...";
CM_ SG_ 2364677118 InternalChargerStatus "Indicates that the charger in this HVES instance is on.  External chargers may use the External Energy Source Connection Status (SPN 7898) and related SPs.
This parameter is for one of multiple packs in an HVESS. If there is only one pack in the ...";
CM_ SG_ 2364677118 CellBalancingActive "Indicates whether or not the cells in this High Voltage Energy Storage Pack instance are currently being balanced.
This parameter is for one of multiple packs in an HVESS.  If there is only one pack in the system, the HVESS parameters should be ...";
CM_ SG_ 2364677118 CellBalanceStatus "Indicates whether or not the cells in this High Voltage Energy Storage Pack instance are balanced.
This parameter is for one of multiple packs in an HVESS.  If there is only one pack in the system, the HVESS parameters should be used. If there are ...";
CM_ SG_ 2364677118 StOfChargeStatus "Status of this High Voltage Energy Storage Pack instance State of Charge (SOC).  Note:  A given HVES controller may not support all of the states.
This parameter is for one of multiple packs in an HVESS.  If there is only one pack in the system, ...";
CM_ SG_ 2364677118 InertiaSwStatus "Switch indicating that an impact has been sensed by this High Voltage Energy Storage Pack instance. The impact indication may require action by another controller, or by this HVES instance itself.  For example, a controller may elect to take this ...";
CM_ SG_ 2364677118 HVILStatus "Status of the High Voltage Interlock Loop from the viewpoint of this High Voltage Energy Storage Pack instance.
This parameter is for one of multiple packs in an HVESS. If there is only one pack in the system, the HVESS parameters should be used ...";
CM_ SG_ 2364677118 HVBusPassiveIsolTestStatus "Status of the high-voltage bus electrical passive isolation test as performed by this High Voltage Energy Storage Pack instance.
This parameter is for one of multiple packs in an HVESS. If there is only one pack in the system, the HVESS parameters ...";
CM_ SG_ 2364677118 HVBusActiveIsolTestStatus "Status of the high-voltage bus electrical active isolation test as performed by this High Voltage Energy Storage Pack instance.
This parameter is for one of multiple packs in an HVESS. If there is only one pack in the system, the HVESS parameters ...";
CM_ SG_ 2364677118 CenterOfPackContactorSt "Position of the center high-voltage contactor. When this contactor is closed, the positive half of this High Voltage Energy Storage Pack instance is connected to the negative half. If a system controls the positive, negative, and center contactors ...";
CM_ SG_ 2364677118 HVBusPreChargeRelaySt "Position of the high-voltage bus contactor pre-charge relay.  When this relay is closed, this High Voltage Energy Storage Pack instance is bringing the high-voltage bus up to its operating level.
This parameter is for one of multiple packs in an ...";
CM_ SG_ 2364677118 HVBusDisconnectForewarning "Indicates that this High Voltage Energy Storage Pack instance is about to disconnect from the high voltage bus due to unacceptable conditions.
This parameter is for one of multiple packs in an HVESS. If there is only one pack in the system, the ...";
CM_ SG_ 2364677118 HVBusContactorSt14086 "Position of this High Voltage Energy Storage Pack instance negative side bus contactor. When this contactor is closed, the negative side of this HVES instance is connected to the negative side of the high-voltage bus. If a system controls the ...";
CM_ SG_ 2364677118 HVBusContactorSt "Position of this High Voltage Energy Storage Pack instance positive side bus contactor.  When this contactor is closed, the positive side of this HVES instance is connected to the positive side of the high-voltage bus.  In systems where all ...";
CM_ BO_ 2364676862 "High Voltage Energy Storage Pack 7 Data 6
Data set 6 (external or interface data) for High Voltage Energy Storage Pack 7.";
CM_ SG_ 2364676862 Temp "The temperature of this High Voltage Energy Storage Pack instance. The value may be determined from a unique sensor specifically for this purpose, or by aggregating various temperature sensor readings within the pack.
This parameter is for one of ...";
CM_ SG_ 2364676862 ETemp "The temperature of the electronics or control modules in this High Voltage Energy Storage Pack instance.  If there are multiple temperature sensors then this parameter would be set to the maximum sensor reading.
This parameter is for one of ...";
CM_ SG_ 2364676862 OutCoolantTemp "The temperature of liquid coolant as it exits this High Voltage Energy Storage Pack instance.
This parameter is for one of multiple packs in an HVESS.  If there is only one pack in the system, the HVESS parameters should be used. If there are ...";
CM_ SG_ 2364676862 InCoolantTemp "The temperature of liquid coolant as it enters this High Voltage Energy Storage Pack instance.
This parameter is for one of multiple packs in an HVESS.  If there is only one pack in the system, the HVESS parameters should be used. If there are ...";
CM_ SG_ 2364676862 IgntV "The voltage level at the ignition input of this High Voltage Energy Storage Pack controller.
This parameter is for one of multiple packs in an HVESS.  If there is only one pack in the system, the HVESS parameters should be used.  If there are ...";
CM_ SG_ 2364676862 BusV "The voltage level of the high voltage bus, as measured by this High Voltage Energy Storage Pack instance on the bus side (not the battery side) of its contactors.
This parameter is for one of multiple packs in an HVESS.  If there is only one pack ...";
CM_ BO_ 2364676606 "High Voltage Energy Storage Pack 7 Data 5
Data set 5 (electrical data) for High Voltage Energy Storage Pack 7.";
CM_ SG_ 2364676606 HighestCellStOfCharge "Indicates the state of charge of the highest-charged cell in this High Voltage Energy Storage Pack instance. 0% means no charge remaining, 100% means the cell is fully charged. If a single state of charge value covers more than one cell, the value ...";
CM_ SG_ 2364676606 LowestCellStOfCharge "Indicates the state of charge of the lowest-charged cell in this High Voltage Energy Storage Pack instance. 0% means no charge remaining, 100% means the cell is fully charged. If a single state of charge value covers more than one cell, the value in ...";
CM_ SG_ 2364676606 ChargeCurLmt "The maximum instantaneous current flow limit into this High Voltage Energy Storage Pack instance. This parameter is defined from the high voltage energy storage pack's point of view and should reflect the instantaneous capability of the pack.  The ...";
CM_ SG_ 2364676606 DisCurLmt "The maximum instantaneous current flow limit out of this High Voltage Energy Storage Pack instance. This parameter is defined from the high voltage energy storage pack's point of view and should reflect the instantaneous capability of the pack.  The ...";
CM_ BO_ 2364676350 "High Voltage Energy Storage Pack 7 Data 4
Data set 4 (electrical data) for High Voltage Energy Storage Pack 7.";
CM_ SG_ 2364676350 CellBalancingCount "The number of cells that are currently being balanced in this High Voltage Energy Storage Pack instance.
This parameter is for one of multiple packs in an HVESS.  If there is only one pack in the system, the HVESS parameters should be used.  If ...";
CM_ SG_ 2364676350 ChargeCapacity "The amount of unused electrical charge storage in this High Voltage Energy Storage Pack instance that is available to be filled by charging, i.e. “how much empty space is remaining in the tank”. See SPN 14103 (HVESP7 Charge Energy Capacity) for ...";
CM_ SG_ 2364676350 DisCapacity "The amount of stored electrical charge in this High Voltage Energy Storage Pack instance that is available for use by the hybrid system, i.e. “how full is the tank”. See SPN 14102 (HVESP7 Discharge Energy Capacity) for kilowatt-hours (kWh).
This ...";
CM_ BO_ 2364676094 "High Voltage Energy Storage Pack 7 Data 3
Data set 3 (thermal data) for High Voltage Energy Storage Pack 7.";
CM_ SG_ 2364676094 CellTempDiffStatus "Indicates whether or not the differential between the highest and lowest cell temperatures are within acceptable limits per this High Voltage Energy Storage Pack instance. The actual temperature differential can be calculated by subtracting SPN ...";
CM_ SG_ 2364676094 AvgCellTemp "The average temperature level of all cells in this High Voltage Energy Storage Pack instance.
This parameter is for one of multiple packs in an HVESS.  If there is only one pack in the system, the HVESS parameters should be used.  If there are ...";
CM_ SG_ 2364676094 LowestCellTemp "The lowest temperature level reported by any cell in this High Voltage Energy Storage Pack instance. If a single temperature sensor covers more than one cell, the value in this parameter is for the smallest group of cells measured. See SPN 14152 ...";
CM_ SG_ 2364676094 HighestCellTemp "The highest temperature level reported by any cell in this High Voltage Energy Storage Pack instance. If a single temperature sensor covers more than one cell, the value in this parameter is for the smallest group of cells measured. See SPN 14150 ...";
CM_ BO_ 2364675838 "High Voltage Energy Storage Pack 7 Data 2
Data set 2 (electrical data) for High Voltage Energy Storage Pack 7.";
CM_ SG_ 2364675838 CellVDiffStatus "Indicates whether or not the differential between the highest and lowest cell voltages are within acceptable limits, according to this High Voltage Energy Storage Pack instance. The actual voltage differential can be calculated by subtracting SPN ...";
CM_ SG_ 2364675838 LowestCellV "The lowest voltage level reported by any cell in this High Voltage Energy Storage Pack instance. If a single voltage sensor covers more than one cell, the value in this parameter is for the smallest group of cells measured. See SPN 14147 (HVESP7 ...";
CM_ SG_ 2364675838 HighestCellV "The highest voltage level reported by any cell in this High Voltage Energy Storage Pack instance. If a single voltage sensor covers more than one cell, the value in this parameter is for the smallest group of cells measured. See SPN 14145 (HVESP7 ...";
CM_ SG_ 2364675838 FastUpdateStOfCharge "Indicates this High Voltage Energy Storage Pack instance state of charge. 0% means no charge remaining, 100% means the system is fully charged in terms of physical limits of this energy storage pack instance. Acceptable state of charge upper and ...";
CM_ BO_ 2364675582 "High Voltage Energy Storage Pack 7 Data 1
Data set 1 (electrical data) for High Voltage Energy Storage Pack 7.";
CM_ SG_ 2364675582 Cur "The current in or out of this High Voltage Energy Storage Pack instance. This parameter should be synchronized with SPN 14062 (HVESP7 Voltage Level) such that a realized power value can be calculated. This parameter is defined from the high voltage ...";
CM_ SG_ 2364675582 Lvl "The voltage level of this High Voltage Energy Storage Pack instance. This parameter should be synchronized with SPN 14063 (HVESP7 Current) such that a realized power value can be calculated. If the HVES component physically contains the contactors ...";
CM_ SG_ 2364675582 AvailableChargePwr "The rate at which this High Voltage Energy Storage Pack instance can currently receive energy from a regenerative or recharging system.
This parameter is for one of multiple packs in an HVESS.  If there is only one pack in the system, the HVESS ...";
CM_ SG_ 2364675582 AvailableDisPwr "The rate at which this High Voltage Energy Storage Pack instance can currently provide energy for propulsion or other uses.
This parameter is for one of multiple packs in an HVESS.  If there is only one pack in the system, the HVESS parameters ...";
CM_ BO_ 2364675326 "High Voltage Energy Storage Pack 7 Status 2
Status data set 2 for High Voltage Energy Storage Pack 7.";
CM_ SG_ 2364675326 ChargePLDueToAnUndefinedCause "Indicates whether or not charge power of this HVES instance is being limited due to an undefined cause.
This parameter is for one of multiple packs in an HVESS.  If there is only one pack in the system, the HVESS parameters should be used. If there ...";
CM_ SG_ 2364675326 ChargePLDueToBatCur "Indicates whether or not charge power of this HVES instance is being limited due to battery current.
This parameter is for one of multiple packs in an HVESS.  If there is only one pack in the system, the HVESS parameters should be used. If there ...";
CM_ SG_ 2364675326 ChargePLDueToBatOrCellV "Indicates whether or not charge power of this HVES instance is being limited due to a battery or cell voltage level.
This parameter is for one of multiple packs in an HVESS.  If there is only one pack in the system, the HVESS parameters should be ...";
CM_ SG_ 2364675326 ChargePLDueToBatDiagCondition "Indicates whether or not charge power of this HVES instance is being limited due to a battery diagnostic condition.
This parameter is for one of multiple packs in an HVESS.  If there is only one pack in the system, the HVESS parameters should be ...";
CM_ SG_ 2364675326 ChargePLDueToBatTemp "Indicates whether or not charge power of this HVES instance is being limited due to battery temperature.
This parameter is for one of multiple packs in an HVESS.  If there is only one pack in the system, the HVESS parameters should be used. If ...";
CM_ SG_ 2364675326 ChargePLDueToStOfCharge "Indicates whether or not charge power of this HVES instance is being limited due to state of charge.
This parameter is for one of multiple packs in an HVESS.  If there is only one pack in the system, the HVESS parameters should be used. If there ...";
CM_ SG_ 2364675326 DisPLDueToAnUndefinedCause "Indicates whether or not discharge power of this HVES instance is being limited due to an undefined cause.
This parameter is for one of multiple packs in an HVESS.  If there is only one pack in the system, the HVESS parameters should be used. If ...";
CM_ SG_ 2364675326 DisPLDueToBatCur "Indicates whether or not discharge power of this HVES instance is being limited due to battery current.
This parameter is for one of multiple packs in an HVESS.  If there is only one pack in the system, the HVESS parameters should be used. If there ...";
CM_ SG_ 2364675326 DisPLDueToBatOrCellV "Indicates whether or not discharge power of this HVES instance is being limited due to a battery or cell voltage level.
This parameter is for one of multiple packs in an HVESS.  If there is only one pack in the system, the HVESS parameters should ...";
CM_ SG_ 2364675326 DisPLDueToBatDiagCondition "Indicates whether or not discharge power of this HVES instance is being limited due to a battery diagnostic condition.
This parameter is for one of multiple packs in an HVESS.  If there is only one pack in the system, the HVESS parameters should be ...";
CM_ SG_ 2364675326 DisPLDueToBatTemp "Indicates whether or not discharge power of this HVES instance is being limited due to battery temperature.
This parameter is for one of multiple packs in an HVESS.  If there is only one pack in the system, the HVESS parameters should be used. If ...";
CM_ SG_ 2364675326 DisPLDueToStOfCharge "Indicates whether or not discharge power of this HVES instance is being limited due to state of charge.
This parameter is for one of multiple packs in an HVESS.  If there is only one pack in the system, the HVESS parameters should be used. If there ...";
CM_ BO_ 2555641598 "EVSE Control 1
This PG carries SPs associated with the control of the connection to the external power source.";
CM_ SG_ 2555641598 ContactorCmd "Contactor command to control any contactors between the vehicle inlet and the internal AC or DC bus.

00b = Open Contactor
01b = Close Contactor
10b = Reserved
11b = Don't Care / Take no action";
CM_ SG_ 2555641598 EVReady "Informs the EVSE that the EV is ready to charge.
Intended for use by systems that support multiple active power sources. If the connection to the EVSE has a control pilot signal, this parameter can be used to to switch the Control Pilot between ...";
CM_ SG_ 2555641598 DCStageReq "DC EVSE Charging stage request that may be used to cycle the connection to the EVSE through various phases of the charging cycle.
Some EVCC implementations will handle this sequencing internally, in which case this SP should be set to 1111b, Don't ...";
CM_ SG_ 2555641598 ConnectorLockCmd "Request to engage or disengage the locking mechanism fitted to this EVSE connector to the vehicle.
The actual Lock state will be reported via SPN 12863 (EVSE1 Connector Lock State).
This parameter shall be from only one source. However, it may be ...";
CM_ BO_ 2555576062 "Daily Data Transfer
This PG is for use by an intermediary (e.g. telematics device) to regularly retrieve one or more proprietary data sets from a control module for the stated reporting interval (e.g. Daily, Weekly or Monthly). These data sets can ...";
CM_ SG_ 2555576062 DailyData "Proprietary data bytes as defined by the transmitter manufacturer Daily Data Set ID.";
CM_ SG_ 2555576062 SetID "This proprietary number is defined by the transmitter manufacturer, and identifies the format of the associated data set to their data cloud or repository.";
CM_ SG_ 2555576062 ManufacturerID "This 11-bit Manufacturer ID (defined in the J1939DA) identifies the transmitter manufacturer whose cloud or data repository is the final destination for the associated data.";
CM_ SG_ 2555576062 MessageInstancesRemaining "This number indicates the message instances yet to be broadcast in a transmitter’s Daily Data Transfer broadcast series. When used together with SPN 12973 [Daily Message Instance], an intermediary device can determine if all of the message instances ...";
CM_ SG_ 2555576062 MessageInstance "A transmitter sets this number to indicate the Daily Data Transfer message instance currently being sent in a broadcast series. It allows an intermediary device to determine what message instance is being sent or was last received. When used ...";
CM_ BO_ 2555510526 "Weekly Data Transfer
This PG is for use by an intermediary (e.g. telematics device) to regularly retrieve one or more proprietary data sets from a control module for the stated reporting interval (e.g. Daily, Weekly or Monthly). These data sets can ...";
CM_ SG_ 2555510526 WeeklyData "Proprietary data bytes as defined by the transmitter manufacturer Weekly Data Set ID.";
CM_ SG_ 2555510526 SetID "This proprietary number is defined by the transmitter manufacturer, and identifies the format of the associated data set to their data cloud or repository.";
CM_ SG_ 2555510526 ManufacturerID "This 11-bit Manufacturer ID (defined in the J1939DA) identifies the transmitter manufacturer whose cloud or data repository is the final destination for the associated data.";
CM_ SG_ 2555510526 MessageInstancesRemaining "This number indicates the message instances yet to be broadcast in a transmitter’s Weekly Transfer broadcast series. When used together with SPN 12978 [Weekly Message Instance], an intermediary device can determine if all of the message instances ...";
CM_ SG_ 2555510526 MessageInstance "A transmitter sets this number to indicate the Weekly Data Transfer message instance currently being sent in a broadcast series. It allows an intermediary device to determine what message instance is being sent or was last received. When used ...";
CM_ BO_ 2555444990 "Monthly Data Transfer
This PG is for use by an intermediary (e.g. telematics device) to regularly retrieve one or more proprietary data sets from a control module for the stated reporting interval (e.g. Daily, Weekly or Monthly). These data sets ...";
CM_ SG_ 2555444990 MonthlyData "Proprietary data bytes as defined by the transmitter manufacturer Monthly Data Set ID.";
CM_ SG_ 2555444990 SetID "This proprietary number is defined by the transmitter manufacturer, and identifies the format of the associated data set to their data cloud or repository.";
CM_ SG_ 2555444990 ManufacturerID "This 11-bit Manufacturer ID (defined in the J1939DA) identifies the transmitter manufacturer whose cloud or data repository is the final destination for the associated data.";
CM_ SG_ 2555444990 MessageInstancesRemaining "This number indicates the message instances yet to be broadcast in a transmitter’s Monthly Data Transfer broadcast series. When used together with SPN 12983 [Monthly Message Instance], an intermediary device can determine if all of the message ...";
CM_ SG_ 2555444990 MessageInstance "A transmitter sets this number to indicate the Monthly Data Transfer message instance currently being sent in a broadcast series. It allows an intermediary device to determine what message instance is being sent or was last received. When used ...";
CM_ BO_ 2555379454 "Data Transfer Support
This information allows potential receivers of Data Transport PGNs DDT, WDT and MDT to understand the largest single message instance they will need to buffer, and the overall amount of storage memory needed to handle all ...";
CM_ SG_ 2555379454 TotalMonthlyMessageBytes "The total number of bytes in all Monthly Data Transfer message instances that will be broadcast by the transmitter. An intermediary (e.g. telematics device) can use this to estimate the amount of memory necessary to handle data acquired through PGN ...";
CM_ SG_ 2555379454 TotalDailyMessageBytes "The total number of bytes in all Daily Data Transfer message instances that will be broadcast by the transmitter.  An intermediary (e.g. telematics device) can use this to estimate the amount of memory necessary to handle data acquired through PGN ...";
CM_ SG_ 2555379454 LongestDailyMessageInstance "The number of bytes in the longest Daily Data Transfer message instance broadcast by the transmitter. An intermediary (e.g. telematics device) can use this to estimate the buffer sizes necessary to handle data acquired through PGN 20992. If PGN ...";
CM_ SG_ 2555379454 TotalDailyMessageInstances "The total count of daily message instances that will be broadcast by the transmitter. An intermediary (e.g. telematics device) can use this parameter to determine how many message instances it will receive after a Data Transfer PGN request is ...";
CM_ SG_ 2555379454 LongestMonthlyMessageInstance "The number of bytes in the longest Monthly Data Transfer message instance broadcast by the transmitter. An intermediary (e.g. telematics device) can use this to estimate the buffer sizes necessary to handle data acquired through PGN 20480. If PGN ...";
CM_ SG_ 2555379454 TotalMonthlyMessageInstances "The total count of monthly message instances that will be broadcast by the transmitter. An intermediary (e.g. telematics device) can use this parameter to determine how many message instances it will receive after a Data Transfer PGN request is ...";
CM_ SG_ 2555379454 TotalWeeklyMessageBytes "The total number of bytes in all Weekly Data Transfer message instances that will be broadcast by the transmitter. An intermediary (e.g. telematics device) can use this to estimate the amount of memory necessary to handle data acquired through PGN ...";
CM_ SG_ 2555379454 LongestWeeklyMessageInstance "The number of bytes in the longest Weekly Data Transfer message instance broadcast by the transmitter. An intermediary (e.g. telematics device) can use this to estimate the buffer sizes necessary to handle data acquired through PGN 20736.  If PGN ...";
CM_ SG_ 2555379454 TotalWeeklyMessageInstances "The total count of weekly message instances that will be broadcast by the transmitter. An intermediary (e.g. telematics device) can use this parameter to determine how many message instances it will receive after a Data Transfer PGN request is ...";
CM_ SG_ 2555379454 ManufacturerID "The 11-bit Manufacturer ID as defined in the J1939DA. An intermediary (e.g. telematics device) can use this to associate the Data Transfer Support requirements with the Data Transfer messages from the same manufacturer.";
CM_ BO_ 2352217854 "High Voltage Energy Storage Pack 10 Control 1
Control commands to be sent to High Voltage Energy Storage Pack 10.";
CM_ SG_ 2352217854 ThermalMnmgtMaintenanceReq "Request to engage Thermal Management Maintenance Mode for this High Voltage Energy Storage System Pack instance.
00b = HVESS Thermal Management Maintenance Mode is not requested
01b = HVESS Thermal Management Maintenance Mode is requested
10b = ...";
CM_ SG_ 2352217854 Ctrl1CRC "The CRC is defined as follows:
• Length: 8 bits
• Polynomial: x^8+x^5+x^3+x^2+x+1
• Initial Value: FFh
• Input Data Reflection: Not reflected
• Result Data Reflection: Not reflected
• XOR value: FFh
SAE makes no claim of the functional safety ...";
CM_ SG_ 2352217854 Ctrl1Counter "The message counter is used to detect situations where the transmitting ECU malfunction repeats the same frame all the time. The receiver of the information may use the counter parameter to detect this situation. The transmitting device will ...";
CM_ SG_ 2352217854 HVBusLowSideResistorConnectReq "This parameter is used to request connection of this HVES instance High-Voltage bus low side resistor in order to perform an isolation test. See also SPN 14473 (HVESP10 High-Voltage Bus High Side Resistor Connect Request).
This parameter is for one ...";
CM_ SG_ 2352217854 HVBusHiSideResistorConnectReq "This parameter is used to request connection of this HVES instance High-Voltage bus high side resistor in order to perform an isolation test. See also SPN 14474 (HVESP10 High-Voltage Bus Low Side Resistor Connect Request).
This parameter is for one ...";
CM_ SG_ 2352217854 OpConsent "This parameter provides an indication to this High Voltage Energy Storage Pack instance that an external device is ready for this HVES instance to proceed with normal operation.  In applications which support this parameter, the HVES instance may ...";
CM_ SG_ 2352217854 EnableInternalChargerCmd "When the HVES has an internal charger this parameter will enable it.   External chargers may use the External Energy Source Connection Demand (SPN 7890) and related SPs.
This parameter is for one of multiple packs in an HVESS.  If there is only one ...";
CM_ SG_ 2352217854 CellBalancingCmd "Command for this High Voltage Energy Storage Pack instance to perform cell balancing.
This parameter is for one of multiple packs in an HVESS.  If there is only one pack in the system, the HVESS parameters should be used. If there are multiple ...";
CM_ SG_ 2352217854 HVBusPassiveIsolTestCmd "Command for this High Voltage Energy Storage Pack instance to perform a passive electrical isolation test on the high voltage bus.
A passive isolation test uses additional circuitry (e.g. a high impedance network) to monitor the delta between the ...";
CM_ SG_ 2352217854 HVBusActiveIsolTestCmd "Command for this High Voltage Energy Storage Pack instance to perform an active electrical isolation test on the high voltage bus.
An active isolation test might use a generated signal (e.g. an injected AC signal) and then monitor changes in the ...";
CM_ SG_ 2352217854 PwrDownCmd "Command to shut down this High Voltage Energy Storage Pack instance.  A normal power-down may involve steps that take some period of time (tests, writing of data, etc.).  However, an emergency power-down should shut down the storage system as ...";
CM_ SG_ 2352217854 HVBusConnectCmd "Command to connect this High Voltage Energy Storage Pack instance to the high-voltage bus.  The emergency contactor closure request may be used in situations where one or more faults in the hybrid powertrain prevent normal operation, but the vehicle ...";
CM_ BO_ 2352152318 "High Voltage Energy Storage Pack 9 Control 1
Control commands to be sent to High Voltage Energy Storage Pack 9.";
CM_ SG_ 2352152318 ThermalMnmgtMaintenanceReq "Request to engage Thermal Management Maintenance Mode for this High Voltage Energy Storage System Pack instance.
00b = HVESS Thermal Management Maintenance Mode is not requested
01b = HVESS Thermal Management Maintenance Mode is requested
10b = ...";
CM_ SG_ 2352152318 Ctrl1CRC "The CRC is defined as follows:
• Length: 8 bits
• Polynomial: x^8+x^5+x^3+x^2+x+1
• Initial Value: FFh
• Input Data Reflection: Not reflected
• Result Data Reflection: Not reflected
• XOR value: FFh
SAE makes no claim of the functional safety ...";
CM_ SG_ 2352152318 Ctrl1Counter "The message counter is used to detect situations where the transmitting ECU malfunction repeats the same frame all the time. The receiver of the information may use the counter parameter to detect this situation. The transmitting device will ...";
CM_ SG_ 2352152318 HVBusLowSideResistorConnectReq "This parameter is used to request connection of this HVES instance High-Voltage bus low side resistor in order to perform an isolation test. See also SPN 14330 (HVESP9 High-Voltage Bus High Side Resistor Connect Request).
This parameter is for one ...";
CM_ SG_ 2352152318 HVBusHiSideResistorConnectReq "This parameter is used to request connection of this HVES instance High-Voltage bus high side resistor in order to perform an isolation test. See also SPN 14331 (HVESP9 High-Voltage Bus Low Side Resistor Connect Request).
This parameter is for one ...";
CM_ SG_ 2352152318 OpConsent "This parameter provides an indication to this High Voltage Energy Storage Pack instance that an external device is ready for this HVES instance to proceed with normal operation.  In applications which support this parameter, the HVES instance may ...";
CM_ SG_ 2352152318 EnableInternalChargerCmd "When the HVES has an internal charger this parameter will enable it.   External chargers may use the External Energy Source Connection Demand (SPN 7890) and related SPs.
This parameter is for one of multiple packs in an HVESS.  If there is only one ...";
CM_ SG_ 2352152318 CellBalancingCmd "Command for this High Voltage Energy Storage Pack instance to perform cell balancing.
This parameter is for one of multiple packs in an HVESS.  If there is only one pack in the system, the HVESS parameters should be used. If there are multiple ...";
CM_ SG_ 2352152318 HVBusPassiveIsolTestCmd "Command for this High Voltage Energy Storage Pack instance to perform a passive electrical isolation test on the high voltage bus.
A passive isolation test uses additional circuitry (e.g. a high impedance network) to monitor the delta between the ...";
CM_ SG_ 2352152318 HVBusActiveIsolTestCmd "Command for this High Voltage Energy Storage Pack instance to perform an active electrical isolation test on the high voltage bus.
An active isolation test might use a generated signal (e.g. an injected AC signal) and then monitor changes in the ...";
CM_ SG_ 2352152318 PwrDownCmd "Command to shut down this High Voltage Energy Storage Pack instance.  A normal power-down may involve steps that take some period of time (tests, writing of data, etc.).  However, an emergency power-down should shut down the storage system as ...";
CM_ SG_ 2352152318 HVBusConnectCmd "Command to connect this High Voltage Energy Storage Pack instance to the high-voltage bus.  The emergency contactor closure request may be used in situations where one or more faults in the hybrid powertrain prevent normal operation, but the vehicle ...";
CM_ BO_ 2352086782 "High Voltage Energy Storage Pack 8 Control 1
Control commands to be sent to High Voltage Energy Storage Pack 8.";
CM_ SG_ 2352086782 ThermalMnmgtMaintenanceReq "Request to engage Thermal Management Maintenance Mode for this High Voltage Energy Storage System Pack instance.
00b = HVESS Thermal Management Maintenance Mode is not requested
01b = HVESS Thermal Management Maintenance Mode is requested
10b = ...";
CM_ SG_ 2352086782 Ctrl1CRC "The CRC is defined as follows:
• Length: 8 bits
• Polynomial: x^8+x^5+x^3+x^2+x+1
• Initial Value: FFh
• Input Data Reflection: Not reflected
• Result Data Reflection: Not reflected
• XOR value: FFh
SAE makes no claim of the functional safety ...";
CM_ SG_ 2352086782 Ctrl1Counter "The message counter is used to detect situations where the transmitting ECU malfunction repeats the same frame all the time. The receiver of the information may use the counter parameter to detect this situation. The transmitting device will ...";
CM_ SG_ 2352086782 HVBusLowSideResistorConnectReq "This parameter is used to request connection of this HVES instance High-Voltage bus low side resistor in order to perform an isolation test. See also SPN 14187 (HVESP8 High-Voltage Bus High Side Resistor Connect Request).
This parameter is for one ...";
CM_ SG_ 2352086782 HVBusHiSideResistorConnectReq "This parameter is used to request connection of this HVES instance High-Voltage bus high side resistor in order to perform an isolation test. See also SPN 14188 (HVESP8 High-Voltage Bus Low Side Resistor Connect Request).
This parameter is for one ...";
CM_ SG_ 2352086782 OpConsent "This parameter provides an indication to this High Voltage Energy Storage Pack instance that an external device is ready for this HVES instance to proceed with normal operation.  In applications which support this parameter, the HVES instance may ...";
CM_ SG_ 2352086782 EnableInternalChargerCmd "When the HVES has an internal charger this parameter will enable it.   External chargers may use the External Energy Source Connection Demand (SPN 7890) and related SPs.
This parameter is for one of multiple packs in an HVESS.  If there is only one ...";
CM_ SG_ 2352086782 CellBalancingCmd "Command for this High Voltage Energy Storage Pack instance to perform cell balancing.
This parameter is for one of multiple packs in an HVESS.  If there is only one pack in the system, the HVESS parameters should be used. If there are multiple ...";
CM_ SG_ 2352086782 HVBusPassiveIsolTestCmd "Command for this High Voltage Energy Storage Pack instance to perform a passive electrical isolation test on the high voltage bus.
A passive isolation test uses additional circuitry (e.g. a high impedance network) to monitor the delta between the ...";
CM_ SG_ 2352086782 HVBusActiveIsolTestCmd "Command for this High Voltage Energy Storage Pack instance to perform an active electrical isolation test on the high voltage bus.
An active isolation test might use a generated signal (e.g. an injected AC signal) and then monitor changes in the ...";
CM_ SG_ 2352086782 PwrDownCmd "Command to shut down this High Voltage Energy Storage Pack instance.  A normal power-down may involve steps that take some period of time (tests, writing of data, etc.).  However, an emergency power-down should shut down the storage system as ...";
CM_ SG_ 2352086782 HVBusConnectCmd "Command to connect this High Voltage Energy Storage Pack instance to the high-voltage bus.  The emergency contactor closure request may be used in situations where one or more faults in the hybrid powertrain prevent normal operation, but the vehicle ...";
CM_ BO_ 2352021246 "High Voltage Energy Storage Pack 7 Control 1
Control commands to be sent to High Voltage Energy Storage Pack 7.";
CM_ SG_ 2352021246 ThermalMnmgtMaintenanceReq "Request to engage Thermal Management Maintenance Mode for this High Voltage Energy Storage System Pack instance.
00b = HVESS Thermal Management Maintenance Mode is not requested
01b = HVESS Thermal Management Maintenance Mode is requested
10b = ...";
CM_ SG_ 2352021246 Ctrl1CRC "The CRC is defined as follows:
• Length: 8 bits
• Polynomial: x^8+x^5+x^3+x^2+x+1
• Initial Value: FFh
• Input Data Reflection: Not reflected
• Result Data Reflection: Not reflected
• XOR value: FFh
SAE makes no claim of the functional safety ...";
CM_ SG_ 2352021246 Ctrl1Counter "The message counter is used to detect situations where the transmitting ECU malfunction repeats the same frame all the time. The receiver of the information may use the counter parameter to detect this situation. The transmitting device will ...";
CM_ SG_ 2352021246 HVBusLowSideResistorConnectReq "This parameter is used to request connection of this HVES instance High-Voltage bus low side resistor in order to perform an isolation test. See also SPN 14044 (HVESP7 High-Voltage Bus High Side Resistor Connect Request).
This parameter is for one ...";
CM_ SG_ 2352021246 HVBusHiSideResistorConnectReq "This parameter is used to request connection of this HVES instance High-Voltage bus high side resistor in order to perform an isolation test. See also SPN 14045 (HVESP7 High-Voltage Bus Low Side Resistor Connect Request).
This parameter is for one ...";
CM_ SG_ 2352021246 OpConsent "This parameter provides an indication to this High Voltage Energy Storage Pack instance that an external device is ready for this HVES instance to proceed with normal operation.  In applications which support this parameter, the HVES instance may ...";
CM_ SG_ 2352021246 EnableInternalChargerCmd "When the HVES has an internal charger this parameter will enable it.   External chargers may use the External Energy Source Connection Demand (SPN 7890) and related SPs.
This parameter is for one of multiple packs in an HVESS.  If there is only one ...";
CM_ SG_ 2352021246 CellBalancingCmd "Command for this High Voltage Energy Storage Pack instance to perform cell balancing.
This parameter is for one of multiple packs in an HVESS.  If there is only one pack in the system, the HVESS parameters should be used. If there are multiple ...";
CM_ SG_ 2352021246 HVBusPassiveIsolTestCmd "Command for this High Voltage Energy Storage Pack instance to perform a passive electrical isolation test on the high voltage bus.
A passive isolation test uses additional circuitry (e.g. a high impedance network) to monitor the delta between the ...";
CM_ SG_ 2352021246 HVBusActiveIsolTestCmd "Command for this High Voltage Energy Storage Pack instance to perform an active electrical isolation test on the high voltage bus.
An active isolation test might use a generated signal (e.g. an injected AC signal) and then monitor changes in the ...";
CM_ SG_ 2352021246 PwrDownCmd "Command to shut down this High Voltage Energy Storage Pack instance.  A normal power-down may involve steps that take some period of time (tests, writing of data, etc.).  However, an emergency power-down should shut down the storage system as ...";
CM_ SG_ 2352021246 HVBusConnectCmd "Command to connect this High Voltage Energy Storage Pack instance to the high-voltage bus.  The emergency contactor closure request may be used in situations where one or more faults in the hybrid powertrain prevent normal operation, but the vehicle ...";
CM_ BO_ 2566619646 "On Board Programming 2
Message sent from the operator controls or device to be programmed.";
CM_ SG_ 2566619646 InitiateInh "Indicates that programming is inhibited. Signal should be used by the target to prevent being programmed, or by the operator to decline/cancel programming.
00b = Programming is not inhibited
01b = Programming is inhibited
10b = Reserved
11b = ...";
CM_ SG_ 2566619646 InitiateReq "Signal indicating that programming should be initiated. Could come from operator controls or target device. Actual initiation may be subject to, or delayed by, operating conditions or interlocks.
00b = On board programming not requested
01b = ...";
CM_ SG_ 2566619646 InitiateECUAddress "Source address of target device for which on board programming is to be initiated. Source addresses 254 and 255 are not valid.";
CM_ BO_ 2566619390 "PTO Governor Configuration
Preprogrammed governor set speed settings for PTO.";
CM_ SG_ 2566619390 AccelOvrdMaxSpd "The maximum engine speed allowed while accelerator pedal is overriding the PTO governor.";
CM_ SG_ 2566619390 MaxPTOGovSetSpd "The maximum allowed engine speed (user programmable) in which preprogrammed PTO governor set speeds 1-8 can be set.";
CM_ SG_ 2566619390 MinPTOGovSetSpd "The minimum allowed engine speed (user programmable) in which preprogrammed PTO governor set speeds 1-8 can be set.";
CM_ SG_ 2566619390 PreprogrammedPTOGovSetSpd8 "This speed corresponds to the PTO governed speed when PTO Governor State (SPN 976) is equal to Preprogrammed PTO Governor Set Speed 8 (10001b).";
CM_ SG_ 2566619390 PreprogrammedPTOGovSetSpd7 "This speed corresponds to the PTO governed speed when PTO Governor State (SPN 976) is equal to Preprogrammed PTO Governor Set Speed 7 (10000b).";
CM_ SG_ 2566619390 PreprogrammedPTOGovSetSpd6 "This speed corresponds to the PTO governed speed when PTO Governor State (SPN 976) is equal to Preprogrammed PTO Governor Set Speed 6 (01111b).";
CM_ SG_ 2566619390 PreprogrammedPTOGovSetSpd5 "This speed corresponds to the PTO governed speed when PTO Governor State (SPN 976) is equal to Preprogrammed PTO Governor Set Speed 5 (01110b).";
CM_ SG_ 2566619390 PreprogrammedPTOGovSetSpd4 "This speed corresponds to the PTO governed speed when PTO Governor State (SPN 976) is equal to Preprogrammed PTO Governor Set Speed 4 (01101b).";
CM_ SG_ 2566619390 PreprogrammedPTOGovSetSpd3 "This speed corresponds to the PTO governed speed when PTO Governor State (SPN 976) is equal to Preprogrammed PTO Governor Set Speed 3 (01100b).";
CM_ SG_ 2566619390 PreprogrammedPTOGovSetSpd2 "This speed corresponds to the PTO governed speed when PTO Governor State (SPN 976) is equal to Preprogrammed PTO Governor Set Speed 2 (01011b).";
CM_ SG_ 2566619390 PreprogrammedPTOGovSetSpd1 "This speed corresponds to the PTO governed speed when PTO Governor State (SPN 976) is equal to Preprogrammed PTO Governor Set Speed 1 (01010b).";
CM_ BO_ 2566619134 "Well Stimulation Pump System Filter Information
Filter parameters information of a well stimulation pump used in oil and gas drilling applications.";
CM_ SG_ 2566619134 OilFilterBypassSwStatus "Displays Pump Oil Filter Switch Status

00b = Not bypassing
01b = Bypassing
10b = Error
11b = Not available";
CM_ SG_ 2566619134 GearBoxOutOilPress "Pump Oil pressure (gage) measured just downstream of oil filter.";
CM_ SG_ 2566619134 OilFilterDiffPress "Change in pump gear box oil pressure, measured across the filter, due to the filter and any accumulation of solid or semisolid material on or in the filter. The differential pressure is measured as the difference between inlet and outlet of the ...";
CM_ BO_ 2566618878 "Electrified Accessory Generator Coolant Fan Status 1
Status data set 1 of electrified accessory: Generator Coolant Fan.  See PGN 26368 for the corresponding command message.";
CM_ SG_ 2566618878 OperatingStatus "Indicates the operating status of the Generator Coolant Fan system or component.  This parameter is used to inform other devices that this system or component is no longer performing to its operational capacity and that reduced, or no flow of the ...";
CM_ SG_ 2566618878 ServiceInd "Indicates that service is required for the Generator Coolant Fan system or component.  An active indication may convey a need for component replacement or periodic service.  The Generator Coolant Fan Motor Controller Status Reason Code (SPN 9821) ...";
CM_ SG_ 2566618878 Pwr "Calculated electrical power consumed by the Generator Coolant Fan.";
CM_ SG_ 2566618878 CtrlTemp "A temperature measured and reported by the device.  It may be used for direct or remote (e.g. by another controller) control of the pump.  For example, this may be the temperature of the fluid flowing through the pump, or some other temperature ...";
CM_ SG_ 2566618878 MotorSpd "Motor Speed of the Generator Coolant Fan.";
CM_ SG_ 2566618878 CtrlCmdStatus "Indicates the source of the speed command to this Generator Coolant Fan system or component.
00b is communicated when the controller is self-controlled (e.g. based on a temperature sensor).
01b is communicated when responding to the Generator ...";
CM_ SG_ 2566618878 CtrlStatusReasonCode "Provides the reason code describing the unique failure of this Generator Coolant Fan Motor system or component.
If a detailed reason code is not used by the supporting application, or this reason code is Not Available, the Generator Coolant Fan ...";
CM_ SG_ 2566618878 EnableStatus "Enable and direction status of this Generator Coolant Fan Motor system or component.

00b = Accessory Motor Off
01b = Accessory Motor On - Normal, Forward, or Default Direction
10b = Accessory Motor On - Reverse Direction
11b = Not available";
CM_ BO_ 2566618622 "Electrified Accessory Generator Coolant Pump Status 1
Status data set 1 of electrified accessory: Generator Coolant Pump.  See PGN 26112 for the corresponding command message.";
CM_ SG_ 2566618622 OperatingStatus "Indicates the operating status of the Generator Coolant Pump system or component.  This parameter is used to inform other devices that this system or component is no longer performing to its operational capacity and that reduced, or no flow of the ...";
CM_ SG_ 2566618622 ServiceInd "Indicates that service is required for the Generator Coolant Pump system or component.  An active indication may convey a need for component replacement or periodic service.  The Generator Coolant Pump Controller Status Reason Code (SPN 9834) may ...";
CM_ SG_ 2566618622 Pwr "Calculated electrical power consumed by the Generator Coolant Pump.";
CM_ SG_ 2566618622 CtrlTemp "A temperature measured and reported by the device.  It may be used for direct or remote (e.g. by another controller) control of the pump.  For example, this may be the temperature of the fluid flowing through the pump, or some other temperature ...";
CM_ SG_ 2566618622 MotorSpd "Motor Speed of the Generator Coolant Pump.";
CM_ SG_ 2566618622 CtrlCmdStatus "Indicates the source of the speed command to the Generator Coolant Pump system or component.
00b is communicated when the controller is self-controlled (e.g. based on a temperature sensor).
01b is communicated when responding to the Generator ...";
CM_ SG_ 2566618622 CtrlStatusReasonCode "Provides the reason code describing the unique failure of the Generator Coolant Pump system or component.
If a detailed reason code is not used by the supporting application, or this reason code is Not Available, the Generator Coolant Pump Service ...";
CM_ SG_ 2566618622 EnableStatus "Enable and direction status of the Generator Coolant Pump system or component.

00b = Accessory Motor Off
01b = Accessory Motor On - Normal, Forward, or Default Direction
10b = Accessory Motor On - Reverse Direction
11b = Not available";
CM_ BO_ 2566618110 "Engine Cylinder Pressure Gamma 5
This PG reports the instantaneous compression and expansion gamma ratios of 4 engine cylinders";
CM_ SG_ 2566618110 Two0ExpansionGammaRatio "The expansion gamma ratio is defined as Log(pressure)/Log(volume) of the cylinder pressure curve during the expansion stroke of the current engine cycle for engine Cylinder 20.  The SP will report FB00h (64256) when the engine is not running.";
CM_ SG_ 2566618110 Two0CompressionGammaRatio "The compression gamma ratio is defined as Log(pressure)/Log(volume) of the cylinder pressure curve during the compression stroke of the current engine cycle for engine Cylinder 20.  The SP will report FB00h (64256) when the engine is not running.";
CM_ SG_ 2566618110 One9ExpansionGammaRatio "The expansion gamma ratio is defined as Log(pressure)/Log(volume) of the cylinder pressure curve during the expansion stroke of the current engine cycle for engine Cylinder 19.  The SP will report FB00h (64256) when the engine is not running.";
CM_ SG_ 2566618110 One9CompressionGammaRatio "The compression gamma ratio is defined as Log(pressure)/Log(volume) of the cylinder pressure curve during the compression stroke of the current engine cycle for engine Cylinder 19.  The SP will report FB00h (64256) when the engine is not running.";
CM_ SG_ 2566618110 One8ExpansionGammaRatio "The expansion gamma ratio is defined as Log(pressure)/Log(volume) of the cylinder pressure curve during the expansion stroke of the current engine cycle for engine Cylinder 18.  The SP will report FB00h (64256) when the engine is not running.";
CM_ SG_ 2566618110 One8CompressionGammaRatio "The compression gamma ratio is defined as Log(pressure)/Log(volume) of the cylinder pressure curve during the compression stroke of the current engine cycle for engine Cylinder 18.  The SP will report FB00h (64256) when the engine is not running.";
CM_ SG_ 2566618110 One7ExpansionGammaRatio "The expansion gamma ratio is defined as Log(pressure)/Log(volume) of the cylinder pressure curve during the expansion stroke of the current engine cycle for engine Cylinder 17.  The SP will report FB00h (64256) when the engine is not running.";
CM_ SG_ 2566618110 One7CompressionGammaRatio "The compression gamma ratio is defined as Log(pressure)/Log(volume) of the cylinder pressure curve during the compression stroke of the current engine cycle for engine Cylinder 17.  The SP will report FB00h (64256) when the engine is not running.";
CM_ BO_ 2566617854 "Engine Cylinder Pressure Gamma 4
This PG reports the instantaneous compression and expansion gamma ratios of 4 engine cylinders";
CM_ SG_ 2566617854 One6ExpansionGammaRatio "The expansion gamma ratio is defined as Log(pressure)/Log(volume) of the cylinder pressure curve during the expansion stroke of the current engine cycle for engine Cylinder 16.  The SP will report FB00h (64256) when the engine is not running.";
CM_ SG_ 2566617854 One6CompressionGammaRatio "The compression gamma ratio is defined as Log(pressure)/Log(volume) of the cylinder pressure curve during the compression stroke of the current engine cycle for engine Cylinder 16.  The SP will report FB00h (64256) when the engine is not running.";
CM_ SG_ 2566617854 One5ExpansionGammaRatio "The expansion gamma ratio is defined as Log(pressure)/Log(volume) of the cylinder pressure curve during the expansion stroke of the current engine cycle for engine Cylinder 15.  The SP will report FB00h (64256) when the engine is not running.";
CM_ SG_ 2566617854 One5CompressionGammaRatio "The compression gamma ratio is defined as Log(pressure)/Log(volume) of the cylinder pressure curve during the compression stroke of the current engine cycle for engine Cylinder 15.  The SP will report FB00h (64256) when the engine is not running.";
CM_ SG_ 2566617854 One4ExpansionGammaRatio "The expansion gamma ratio is defined as Log(pressure)/Log(volume) of the cylinder pressure curve during the expansion stroke of the current engine cycle for engine Cylinder 14.  The SP will report FB00h (64256) when the engine is not running.";
CM_ SG_ 2566617854 One4CompressionGammaRatio "The compression gamma ratio is defined as Log(pressure)/Log(volume) of the cylinder pressure curve during the compression stroke of the current engine cycle for engine Cylinder 14.  The SP will report FB00h (64256) when the engine is not running.";
CM_ SG_ 2566617854 One3ExpansionGammaRatio "The expansion gamma ratio is defined as Log(pressure)/Log(volume) of the cylinder pressure curve during the expansion stroke of the current engine cycle for engine Cylinder 13.  The SP will report FB00h (64256) when the engine is not running.";
CM_ SG_ 2566617854 One3CompressionGammaRatio "The compression gamma ratio is defined as Log(pressure)/Log(volume) of the cylinder pressure curve during the compression stroke of the current engine cycle for engine Cylinder 13.  The SP will report FB00h (64256) when the engine is not running.";
CM_ BO_ 2566617598 "Engine Cylinder Pressure Gamma 3
This PG reports the instantaneous compression and expansion gamma ratios of 4 engine cylinders";
CM_ SG_ 2566617598 One2ExpansionGammaRatio "The expansion gamma ratio is defined as Log(pressure)/Log(volume) of the cylinder pressure curve during the expansion stroke of the current engine cycle for engine Cylinder 12.  The SP will report FB00h (64256) when the engine is not running.";
CM_ SG_ 2566617598 One2CompressionGammaRatio "The compression gamma ratio is defined as Log(pressure)/Log(volume) of the cylinder pressure curve during the compression stroke of the current engine cycle for engine Cylinder 12.  The SP will report FB00h (64256) when the engine is not running.";
CM_ SG_ 2566617598 One1ExpansionGammaRatio "The expansion gamma ratio is defined as Log(pressure)/Log(volume) of the cylinder pressure curve during the expansion stroke of the current engine cycle for engine Cylinder 11.  The SP will report FB00h (64256) when the engine is not running.";
CM_ SG_ 2566617598 One1CompressionGammaRatio "The compression gamma ratio is defined as Log(pressure)/Log(volume) of the cylinder pressure curve during the compression stroke of the current engine cycle for engine Cylinder 11.  The SP will report FB00h (64256) when the engine is not running.";
CM_ SG_ 2566617598 One0ExpansionGammaRatio "The expansion gamma ratio is defined as Log(pressure)/Log(volume) of the cylinder pressure curve during the expansion stroke of the current engine cycle for engine Cylinder 10.  The SP will report FB00h (64256) when the engine is not running.";
CM_ SG_ 2566617598 One0CompressionGammaRatio "The compression gamma ratio is defined as Log(pressure)/Log(volume) of the cylinder pressure curve during the compression stroke of the current engine cycle for engine Cylinder 10.  The SP will report FB00h (64256) when the engine is not running.";
CM_ SG_ 2566617598 NineExpansionGammaRatio "The expansion gamma ratio is defined as Log(pressure)/Log(volume) of the cylinder pressure curve during the expansion stroke of the current engine cycle for engine Cylinder 9.  The SP will report FB00h (64256) when the engine is not running.";
CM_ SG_ 2566617598 NineCompressionGammaRatio "The compression gamma ratio is defined as Log(pressure)/Log(volume) of the cylinder pressure curve during the compression stroke of the current engine cycle for engine Cylinder 9.  The SP will report FB00h (64256) when the engine is not running.";
CM_ BO_ 2566617342 "Engine Cylinder Pressure Gamma 2
This PG reports the instantaneous compression and expansion gamma ratios of 4 engine cylinders";
CM_ SG_ 2566617342 EightExpansionGammaRatio "The expansion gamma ratio is defined as Log(pressure)/Log(volume) of the cylinder pressure curve during the expansion stroke of the current engine cycle for engine Cylinder 8.  The SP will report FB00h (64256) when the engine is not running.";
CM_ SG_ 2566617342 EightCompressionGammaRatio "The compression gamma ratio is defined as Log(pressure)/Log(volume) of the cylinder pressure curve during the compression stroke of the current engine cycle for engine Cylinder 8.  The SP will report FB00h (64256) when the engine is not running.";
CM_ SG_ 2566617342 SevenExpansionGammaRatio "The expansion gamma ratio is defined as Log(pressure)/Log(volume) of the cylinder pressure curve during the expansion stroke of the current engine cycle for engine Cylinder 7.  The SP will report FB00h (64256) when the engine is not running.";
CM_ SG_ 2566617342 SevenCompressionGammaRatio "The compression gamma ratio is defined as Log(pressure)/Log(volume) of the cylinder pressure curve during the compression stroke of the current engine cycle for engine Cylinder 7.  The SP will report FB00h (64256) when the engine is not running.";
CM_ SG_ 2566617342 SixExpansionGammaRatio "The expansion gamma ratio is defined as Log(pressure)/Log(volume) of the cylinder pressure curve during the expansion stroke of the current engine cycle for engine Cylinder 6.  The SP will report FB00h (64256) when the engine is not running.";
CM_ SG_ 2566617342 SixCompressionGammaRatio "The compression gamma ratio is defined as Log(pressure)/Log(volume) of the cylinder pressure curve during the compression stroke of the current engine cycle for engine Cylinder 6.  The SP will report FB00h (64256) when the engine is not running.";
CM_ SG_ 2566617342 FiveExpansionGammaRatio "The expansion gamma ratio is defined as Log(pressure)/Log(volume) of the cylinder pressure curve during the expansion stroke of the current engine cycle for engine Cylinder 5.  The SP will report FB00h (64256) when the engine is not running.";
CM_ SG_ 2566617342 FiveCompressionGammaRatio "The compression gamma ratio is defined as Log(pressure)/Log(volume) of the cylinder pressure curve during the compression stroke of the current engine cycle for engine Cylinder 5.  The SP will report FB00h (64256) when the engine is not running.";
CM_ BO_ 2566617086 "Engine Cylinder Pressure Gamma 1
This PG reports the instantaneous compression and expansion gamma ratios of 4 engine cylinders";
CM_ SG_ 2566617086 FourExpansionGammaRatio "The expansion gamma ratio is defined as Log(pressure)/Log(volume) of the cylinder pressure curve during the expansion stroke of the current engine cycle for engine cylinder 4.  The SP will report FB00h (64256) when the engine is not running.";
CM_ SG_ 2566617086 FourCompressionGammaRatio "The compression gamma ratio is defined as Log(pressure)/Log(volume) of the cylinder pressure curve during the compression stroke of the current engine cycle for engine cylinder 4.  The SP will report FB00h (64256) when the engine is not running.";
CM_ SG_ 2566617086 ThreeExpansionGammaRatio "The expansion gamma ratio is defined as Log(pressure)/Log(volume) of the cylinder pressure curve during the expansion stroke of the current engine cycle for engine cylinder 3.  The SP will report FB00h (64256) when the engine is not running.";
CM_ SG_ 2566617086 ThreeCompressionGammaRatio "The compression gamma ratio is defined as Log(pressure)/Log(volume) of the cylinder pressure curve during the compression stroke of the current engine cycle for engine cylinder 3.  The SP will report FB00h (64256) when the engine is not running.";
CM_ SG_ 2566617086 TwoExpansionGammaRatio "The expansion gamma ratio is defined as Log(pressure)/Log(volume) of the cylinder pressure curve during the expansion stroke of the current engine cycle for engine cylinder 2.  The SP will report FB00h (64256) when the engine is not running.";
CM_ SG_ 2566617086 TwoCompressionGammaRatio "The compression gamma ratio is defined as Log(pressure)/Log(volume) of the cylinder pressure curve during the compression stroke of the current engine cycle for engine cylinder 2.  The SP will report FB00h (64256) when the engine is not running.";
CM_ SG_ 2566617086 OneExpansionGammaRatio "The expansion gamma ratio is defined as Log(pressure)/Log(volume) of the cylinder pressure curve during the expansion stroke of the current engine cycle for engine cylinder 1.  The SP will report FB00h (64256) when the engine is not running.";
CM_ SG_ 2566617086 OneCompressionGammaRatio "The compression gamma ratio is defined as Log(pressure)/Log(volume) of the cylinder pressure curve during the compression stroke of the current engine cycle for engine cylinder 1.  The SP will report FB00h (64256) when the engine is not running.";
CM_ BO_ 2566616830 "Personnel Detect Status
Reports the alarm status for personnel detection for up to 3 detection zones from a detection device. The detection zone and detection location are used to identify an system-specific area of detection.
The zone data in a ...";
CM_ SG_ 2566616830 SequenceCounter "A counter value which increments per each transmission of data. If Personnel Detect Status consists of multiple messages then each message in the group shall share the same Sequence Counter value.
NOTE - The counter for the first message is ...";
CM_ SG_ 2566616830 ZoneAlarmStatus3 "Indicates the alarm status for detection of personnel within the detection zone identified by Detection Zone 3 (SPN 10138) and Detection Location 3 (SPN 10139).
0000b = No Alarm Active
0001b = Alarm Active
0010b = Reserved for SAE assignment
 ...";
CM_ SG_ 2566616830 DetectionZone3 "Identifies the detection zone associated with Zone Alarm Status 3 (SPN 10140) reported in the message. A detection zone identifies spatial area within the detection location specified by Detection Location 3 (SPN 10139). When the PG contains Zone ...";
CM_ SG_ 2566616830 DetectionLocation3 "Identifies the location of the detection area associated with Zone Alarm Status 3 (SPN 10140) reported in the message. The detection location identifies a directional area of detection from the vehicle. When the PG contains Zone Alarm Status data ...";
CM_ SG_ 2566616830 ZoneAlarmStatus2 "Indicates the alarm status for detection of personnel within the detection zone identified by Detection Zone 2 (SPN 10135) and Detection Location 2 (SPN 10136).
0000b = No Alarm Active
0001b = Alarm Active
0010b = Reserved for SAE assignment
 ...";
CM_ SG_ 2566616830 DetectionZone2 "Identifies the detection zone associated with Zone Alarm Status 2 (SPN 10137) reported in the message. A detection zone identifies spatial area within the detection location specified by Detection Location 2 (SPN 10136). When the PG contains Zone ...";
CM_ SG_ 2566616830 DetectionLocation2 "Identifies the location of the detection area associated with Zone Alarm Status 2 (SPN 10137) reported in the message. The detection location identifies a directional area of detection from the vehicle. When the PG contains Zone Alarm Status data ...";
CM_ SG_ 2566616830 ZoneAlarmStatus1 "Indicates the alarm status for detection of personnel within the detection zone identified by Detection Zone 1 (SPN 10132) and Detection Location 1 (SPN 10133).
0000b = No Alarm Active
0001b = Alarm Active
0010b = Reserved for SAE assignment
 ...";
CM_ SG_ 2566616830 DetectionZone1 "Identifies the detection zone associated with Zone Alarm Status 1 (SPN 10134) reported in the message. A detection zone identifies spatial area within the detection location specified by Detection Location 1 (SPN 13133). When the PG contains Zone ...";
CM_ SG_ 2566616830 DetectionLocation1 "Identifies the location of the detection area associated with Zone Alarm Status 1 (SPN 10134) reported in the message. The detection location identifies a directional area of detection from the vehicle. When the PG contains Zone Alarm Status data ...";
CM_ BO_ 2365289982 "Motor/Generator 1 Inverter Reference 1
The torque and speed reference values from this inverter.";
CM_ SG_ 2365289982 Pwr "This value is used for converting power in percent to units of kW.  It is applicable to both mechanical and electrical power.
(Value in kW) = (Percent Value)/(100%) * (Reference Power)
For example, if this parameter has a value of 400 kW and the ...";
CM_ SG_ 2365289982 Spd "This value is used for converting Speed in percent to units of rpm.
Value in rpm = (Percent Value)/(100%) * (Reference Speed)
For example, if this parameter has a value of 8192 rpm and the percent value is equal to 75%, then the value in rpm will ...";
CM_ SG_ 2365289982 Trq "This value is used for converting torque in percent to units of Nm.
Value in Nm = (Percent Value)/(100%) * (Reference Torque)
For example, if this parameter has a value of 400 Nm and the percent value is equal to 75%, then the value in Nm will be ...";
CM_ SG_ 2365289982 Counter "The message counter is used to detect situations where the transmitting ECU malfunction repeats the same frame all the time. The receiver of the information may use the counter parameter to detect this situation. The transmitting device will ...";
CM_ SG_ 2365289982 CRC "The CRC is defined as follows:
• Length: 8 bits
• Polynomial: x^8+x^5+x^3+x^2+x+1
• Initial Value: FFh
• Input Data Reflection: Not reflected
• Result Data Reflection: Not reflected
• XOR value: FFh
SAE makes no claim of the functional safety ...";
CM_ BO_ 2365289726 "Motor/Generator 1 Inverter Status 1
First Status Message from the Inverter.  Some examples of use would be for a hybrid or electric vehicle propulsion motor or generator.";
CM_ SG_ 2365289726 DCSideV "The measured or estimated DC side voltage.  

Refer to SPN 10203 [Reference Voltage] to convert % to Volts.";
CM_ SG_ 2365289726 DCSideCur "This is the DC side current of the inverter.
Refer to SPN 10202 [Reference Current] to convert % to Amps.
While motoring, the current is defined as positive.  For example, in a hybrid propulsion system, positive current flows from the HVES through ...";
CM_ SG_ 2365289726 Spd "The measured or estimated motor speed.  This refers to the motor rotor output and excludes any gearbox that may be attached to the motor.   

Refer to SPN 10171 [Reference Speed] to convert % to rpm.";
CM_ SG_ 2365289726 Trq "The measured or estimated motor torque.  This refers to the motor rotor output and excludes any gearbox that may be attached to the motor.
Refer to SPN 10170 [Reference Torque] to convert % to Nm.
The motor is generating when SPN 9057 [Speed] and ...";
CM_ SG_ 2365289726 Counter "The message counter is used to detect situations where the transmitting ECU malfunction repeats the same frame all the time. The receiver of the information may use the counter parameter to detect this situation. The transmitting device will ...";
CM_ SG_ 2365289726 CRC "The CRC is defined as follows:
• Length: 8 bits
• Polynomial: x^8+x^5+x^3+x^2+x+1
• Initial Value: FFh
• Input Data Reflection: Not reflected
• Result Data Reflection: Not reflected
• XOR value: FFh
SAE makes no claim of the functional safety ...";
CM_ BO_ 2365289470 "Motor/Generator 1 Inverter Reference 2
The electrical reference values from this inverter.";
CM_ SG_ 2365289470 V "This value is used for converting inverter voltage in percent to units of Volts (RMS or DC).
(Value in Volts) = (Percent Value)/(100%) * (Reference Voltage)
For example, if this parameter has a value of 400 V and the percent value is equal to 75%, ...";
CM_ SG_ 2365289470 Cur "This value is used for converting inverter current in percent to units of Amps (RMS or DC).
(Value in Amps) = (Percent Value)/(100%) * (Reference Current)
For example, if this parameter has a value of 200 A and the percent value is equal to 75%, ...";
CM_ SG_ 2365289470 Counter "The message counter is used to detect situations where the transmitting ECU malfunction repeats the same frame all the time. The receiver of the information may use the counter parameter to detect this situation. The transmitting device will ...";
CM_ SG_ 2365289470 CRC "The CRC is defined as follows:
• Length: 8 bits
• Polynomial: x^8+x^5+x^3+x^2+x+1
• Initial Value: FFh
• Input Data Reflection: Not reflected
• Result Data Reflection: Not reflected
• XOR value: FFh
SAE makes no claim of the functional safety ...";
CM_ BO_ 2566615806 "Motor/Generator 1 Inverter Temperature
Inverter Temperature Status Message";
CM_ SG_ 2566615806 Five "The exact location of this temperature can be defined by the manufacturer. It is intended to be located somewhere on the inverter.";
CM_ SG_ 2566615806 Four "The exact location of this temperature can be defined by the manufacturer.  It is intended to be located somewhere on the inverter.";
CM_ SG_ 2566615806 Three "The exact location of this temperature can be defined by the manufacturer.  It is intended to be located somewhere on the inverter.";
CM_ SG_ 2566615806 Two "The exact location of this temperature can be defined by the manufacturer.  It is intended to be located somewhere on the inverter.";
CM_ SG_ 2566615806 One "The exact location of this temperature can be defined by the manufacturer.  It is intended to be located somewhere on the inverter.";
CM_ BO_ 2566615550 "Motor/Generator 1 Inverter Motor Temperature
Motor Temperature Status Message";
CM_ SG_ 2566615550 Temp4 "The exact location of this temperature can be defined by the manufacturer.  It is intended to located somewhere on the motor.";
CM_ SG_ 2566615550 Temp3 "The exact location of this temperature can be defined by the manufacturer.  It is intended to located somewhere on the motor.";
CM_ SG_ 2566615550 Temp2 "The exact location of this temperature can be defined by the manufacturer.  It is intended to located somewhere on the motor.";
CM_ SG_ 2566615550 Temp1 "The exact location of this temperature can be defined by the manufacturer.  It is intended to located somewhere on the motor.";
CM_ BO_ 2566615294 "Motor/Generator 2 Inverter Motor Temperature
Motor Temperature Status Message";
CM_ SG_ 2566615294 Temp4 "The exact location of this temperature can be defined by the manufacturer.  It is intended to located somewhere on the motor.";
CM_ SG_ 2566615294 Temp3 "The exact location of this temperature can be defined by the manufacturer.  It is intended to located somewhere on the motor.";
CM_ SG_ 2566615294 Temp2 "The exact location of this temperature can be defined by the manufacturer.  It is intended to located somewhere on the motor.";
CM_ SG_ 2566615294 Temp1 "The exact location of this temperature can be defined by the manufacturer.  It is intended to located somewhere on the motor.";
CM_ BO_ 2566615038 "Motor/Generator 2 Inverter Temperature
Inverter Temperature Status Message";
CM_ SG_ 2566615038 Five "The exact location of this temperature can be defined by the manufacturer. It is intended to be located somewhere on the inverter.";
CM_ SG_ 2566615038 Four "The exact location of this temperature can be defined by the manufacturer.  It is intended to be located somewhere on the inverter.";
CM_ SG_ 2566615038 Three "The exact location of this temperature can be defined by the manufacturer.  It is intended to be located somewhere on the inverter.";
CM_ SG_ 2566615038 Two "The exact location of this temperature can be defined by the manufacturer.  It is intended to be located somewhere on the inverter.";
CM_ SG_ 2566615038 One "The exact location of this temperature can be defined by the manufacturer.  It is intended to be located somewhere on the inverter.";
CM_ BO_ 2365288190 "Motor/Generator 2 Inverter Reference 2
The electrical reference values from this inverter.";
CM_ SG_ 2365288190 V "This value is used for converting inverter voltage in percent to units of Volts (RMS or DC).
(Value in Volts) = (Percent Value)/(100%) * (Reference Voltage)
For example, if this parameter has a value of 400 V and the percent value is equal to 75%, ...";
CM_ SG_ 2365288190 Cur "This value is used for converting inverter current in percent to units of Amps (RMS or DC).
(Value in Amps) = (Percent Value)/(100%) * (Reference Current)
For example, if this parameter has a value of 200 A and the percent value is equal to 75%, ...";
CM_ SG_ 2365288190 Counter "The message counter is used to detect situations where the transmitting ECU malfunction repeats the same frame all the time. The receiver of the information may use the counter parameter to detect this situation. The transmitting device will ...";
CM_ SG_ 2365288190 CRC "The CRC is defined as follows:
• Length: 8 bits
• Polynomial: x^8+x^5+x^3+x^2+x+1
• Initial Value: FFh
• Input Data Reflection: Not reflected
• Result Data Reflection: Not reflected
• XOR value: FFh
SAE makes no claim of the functional safety ...";
CM_ BO_ 2365287934 "Motor/Generator 2 Inverter Status 1
First Status Message from the Inverter.  Some examples of use would be for a hybrid or electric vehicle propulsion motor or generator.";
CM_ SG_ 2365287934 DCSideV "The measured or estimated DC side voltage.  

Refer to SPN 10269 [Reference Voltage] to convert % to Volts.";
CM_ SG_ 2365287934 DCSideCur "This is the DC side current of the inverter.
Refer to SPN 10268 [Reference Current] to convert % to Amps.
While motoring, the current is defined as positive.  For example, in a hybrid propulsion system, positive current flows from the HVES through ...";
CM_ SG_ 2365287934 Spd "The measured or estimated motor speed.  This refers to the motor rotor output and excludes any gearbox that may be attached to the motor.
Refer to SPN 10237 [Reference Speed] to convert % to rpm.
The motor is generating when SPN 9058 [Speed] and ...";
CM_ SG_ 2365287934 Trq "The measured or estimated motor torque.  This refers to the motor rotor output and excludes any gearbox that may be attached to the motor.
Refer to SPN 10236 [Reference Torque] to convert % to Nm.
The motor is generating when SPN 9058 [Speed] and ...";
CM_ SG_ 2365287934 Counter "The message counter is used to detect situations where the transmitting ECU malfunction repeats the same frame all the time. The receiver of the information may use the counter parameter to detect this situation. The transmitting device will ...";
CM_ SG_ 2365287934 CRC "The CRC is defined as follows:
• Length: 8 bits
• Polynomial: x^8+x^5+x^3+x^2+x+1
• Initial Value: FFh
• Input Data Reflection: Not reflected
• Result Data Reflection: Not reflected
• XOR value: FFh
SAE makes no claim of the functional safety ...";
CM_ BO_ 2365287678 "Motor/Generator 2 Inverter Reference 1
The torque and speed reference values from this inverter.";
CM_ SG_ 2365287678 Pwr "This value is used for converting power in percent to units of kW.  It is applicable to both mechanical and electrical power.
(Value in kW) = (Percent Value)/(100%) * (Reference Power)
For example, if this parameter has a value of 400 kW and the ...";
CM_ SG_ 2365287678 Spd "This value is used for converting Speed in percent to units of rpm.
Value in rpm = (Percent Value)/(100%) * (Reference Speed)
For example, if this parameter has a value of 8192 rpm and the percent value is equal to 75%, then the value in rpm will ...";
CM_ SG_ 2365287678 Trq "This value is used for converting torque in percent to units of Nm.
Value in Nm = (Percent Value)/(100%) * (Reference Torque)
For example, if this parameter has a value of 400 Nm and the percent value is equal to 75%, then the value in Nm will be ...";
CM_ SG_ 2365287678 Counter "The message counter is used to detect situations where the transmitting ECU malfunction repeats the same frame all the time. The receiver of the information may use the counter parameter to detect this situation. The transmitting device will ...";
CM_ SG_ 2365287678 CRC "The CRC is defined as follows:
• Length: 8 bits
• Polynomial: x^8+x^5+x^3+x^2+x+1
• Initial Value: FFh
• Input Data Reflection: Not reflected
• Result Data Reflection: Not reflected
• XOR value: FFh
SAE makes no claim of the functional safety ...";
CM_ BO_ 2566614014 "High Voltage Bus Information
High Voltage Bus Information";
CM_ SG_ 2566614014 OffBoardChargerAvailablility "This parameter indicates the availability of the high voltage bus to off-board charging components or supporting on-vehicle contactors.   See SPN 13181 Hybrid DC Inlet Contactor 1 State for contactor example.
0000b = High voltage DC bus is not ...";
CM_ SG_ 2566614014 OnBoardChargerAvailablility "This parameter indicates the availability of the high voltage bus to on-board charging components.
0000b = High voltage DC bus is not connected.
0001b = High voltage DC bus is connected.
0010b = High voltage DC bus connection is in process of ...";
CM_ SG_ 2566614014 EPTOAvailability "This parameter indicates the availability of the high voltage bus to electric power take off components.
0000b = High voltage DC bus is not connected.
0001b = High voltage DC bus is connected.
0010b = High voltage DC bus connection is in process ...";
CM_ SG_ 2566614014 AuxiliariesAvailability "This parameter indicates the availability of the high voltage bus to auxiliary components.
0000b = High voltage DC bus is not connected.
0001b = High voltage DC bus is connected.
0010b = High voltage DC bus connection is in process of being ...";
CM_ SG_ 2566614014 DrivelineAvailability "This parameter indicates the availability of the high voltage bus to driveline components.  Components may include, but are not limited to motor/generator inverters.
0000b = High voltage DC bus is not connected.
0001b = High voltage DC bus is ...";
CM_ SG_ 2566614014 DCBusAvailability "This parameter indicates the availability of the high voltage bus to power components.  Power sources may include, but are not limited to batteries, fuel cells, generators, etc.  Note:  For batteries, SPN 8413 exists to explicitly convey the ...";
CM_ BO_ 2566613758 "Motor/Generator 1 Inverter Isolation Integrity
The electrical isolation Integrity status of the Inverter.  Some examples of use would be for a hybrid or electric vehicle propulsion motor or generator.";
CM_ SG_ 2566613758 HVBusPassiveIsolTestResults "The isolation resistance that resulted from the High-Voltage Bus Passive Isolation Test.
See SPN 10776 [High-Voltage Bus Passive Isolation Test Status] for test status and SPN 10769 [High-Voltage Bus Passive Isolation Test Command] for the command ...";
CM_ SG_ 2566613758 HVBusActiveIsolTestResults "The isolation resistance that resulted from the High-Voltage Bus Active Isolation Test.
See SPN 10775 [High-Voltage Bus Active Isolation Test Status] for test status and SPN 10768 [High-Voltage Bus Active Isolation Test Command] for the command to ...";
CM_ SG_ 2566613758 HVBusPassiveIsolTestStatus "Status of the high-voltage bus electrical passive isolation test as performed by this instance of the Motor/Generator.
0000b = No test requested / No test in process
0001b = Test requested but not yet in process
0010b = Test in process
0011b = ...";
CM_ SG_ 2566613758 HVBusActiveIsolTestStatus "Status of the high-voltage bus electrical active isolation test as performed by this instance of the Motor/Generator.
0000b = No test requested / No test in process
0001b = Test requested but not yet in process
0010b = Test in process
0011b = ...";
CM_ SG_ 2566613758 DCSideNegToChassisGroundV "The voltage level of the high voltage DC side, as measured by the inverter between the negative side of the High Voltage DC Side input and the chassis of the inverter enclosure.  This voltage can be used for system level monitoring of DC Side High ...";
CM_ SG_ 2566613758 Counter "The message counter is used to detect situations where the transmitting ECU malfunction repeats the same frame all the time. The receiver of the information may use the counter parameter to detect this situation. The transmitting device will ...";
CM_ SG_ 2566613758 CRC "The CRC is defined as follows:
• Length: 8 bits
• Polynomial: x^8+x^5+x^3+x^2+x+1
• Initial Value: FFh
• Input Data Reflection: Not reflected
• Result Data Reflection: Not reflected
• XOR value: FFh
SAE makes no claim of the functional safety ...";
CM_ BO_ 2566613502 "Motor/Generator 1 Inverter Active Power Limits
Sent by this Motor/Generator Inverter instance and contains the current operating conditions of the inverter.  This message would be received by a controller application that is responsible for ...";
CM_ SG_ 2566613502 TrqLimDueToMachineCharacteristic "Output torque is being limited due to SPN 9061 [Torque] approaching or exceeding a motor design characteristic.  For example, for permanent magnet machines, this would be in the field weakening area.
00b = No torque limit for this reason
01b = ...";
CM_ SG_ 2566613502 PLedDueToActiveSpdRateLmt "Output power is being limited due to exceeding internally defined speed rate limit(s) or SPN 10796 [Inverter Rate Limits Request Absolute Speed Rate Limit].
00b = No power limit for this reason
01b = Power limited for this reason
10b = Error
11b ...";
CM_ SG_ 2566613502 PLedDueToActiveTrqRateLmt "Output power is being limited due to exceeding internally defined torque rate limit(s) or SPN 10797 [Inverter Rate Limits Request Absolute Torque Rate Limit].
00b = No power limit for this reason
01b = Power limited for this reason
10b = Error
 ...";
CM_ SG_ 2566613502 PLedDueToFaultCondition "Output power is being limited due to an fault condition that requires a torque limitation to prevent further damage (e.g. “limp home mode”).  For example, this could be in case of temperature sensor defects.  Typically, this parameter would be ...";
CM_ SG_ 2566613502 PLedDueToMotorTemp "Output power is being limited due to one or more motor temperature(s), see SPNs 9059 and 10220 through 10222 [Motor Temperature 1-4] approaching or exceeding internally defined limit(s).
00b = No power limit for this reason
01b = Power limited for ...";
CM_ SG_ 2566613502 PLedDueToInvTemp "Output power is being limited due to one or more inverter temperature(s), see SPNs 10216 through 10219 [Inverter Temperature 1-4] approaching or exceeding internally defined limit(s).
00b = No power limit for this reason
01b = Power limited for ...";
CM_ SG_ 2566613502 PLedDueToSpdMin "Output power is being limited due to SPN 9057 [Speed] approaching or falling below the SPN 10199 [Inverter Limits Active Speed Minimum].

00b = No power limit for this reason
01b = Power limited for this reason
10b = Error
11b = Not Available";
CM_ SG_ 2566613502 PLedDueToSpdMax "Output power is being limited due to SPN 9057 [Speed] approaching or exceeding the SPN 10198 [Inverter Limits Active Speed Maximum].

00b = No power limit for this reason
01b = Power limited for this reason
10b = Error
11b = Not Available";
CM_ SG_ 2566613502 PLedDueToTrqMin "Output power is being limited due to SPN 9061 [Torque] approaching or falling below the SPN 10197 [Inverter Limits Active Torque Minimum].

00b = No power limit for this reason
01b = Power limited for this reason
10b = Error
11b = Not Available";
CM_ SG_ 2566613502 PLedDueToTrqMax "Output power is being limited due to SPN 9061 [Torque] approaching or exceeding the SPN 10196 [Inverter Limits Active Torque Maximum].

00b = No power limit for this reason
01b = Power limited for this reason
10b = Error
11b = Not Available";
CM_ SG_ 2566613502 PLedDueToDCSidePwrMin "Output power is being limited due to DC Side Power (product of SPN 10175 [Inverter DC Side Current] and SPN 9101 [Inverter DC Side Voltage]) approaching or falling below the SPN 10187 [Inverter Limits Active DC Side Power Minimum].
00b = No power ...";
CM_ SG_ 2566613502 PLedDueToDCSidePwrMax "Output power is being limited due to DC Side Power (product of SPN 10175 [Inverter DC Side Current] and SPN 9101 [Inverter DC Side Voltage]) approaching or exceeding the SPN 10186 [Inverter Limits Active DC Side Power Maximum].
00b = No power limit ...";
CM_ SG_ 2566613502 PLedDueToMechPwrMin "Output power is being limited due to Mechanical Power (product of SPN 9061 [Torque] and SPN 9057 [Speed]) approaching or falling below the SPN 10185 [Inverter Limits Active Mechanical Power Minimum].
00b = No power limit for this reason
01b = ...";
CM_ SG_ 2566613502 PLedDueToMechPwrMax "Output power is being limited due to Mechanical Power (product of SPN 9061 [Torque] and SPN 9057 [Speed]) approaching or exceeding the SPN 10184 [Inverter Limits Active Mechanical Power Maximum].
00b = No power limit for this reason
01b = Power ...";
CM_ SG_ 2566613502 PLedDueToDCSideVMin "Output power is being limited due to SPN 9101 [Inverter DC Side Voltage] approaching or falling below the SPN 10213 [Inverter Limits Active DC Side Voltage Minimum].
00b = No power limit for this reason
01b = Power limited for this reason
10b = ...";
CM_ SG_ 2566613502 PLedDueToDCSideVMax "Output power is being limited due to SPN 9101 [Inverter DC Side Voltage] approaching or exceeding the SPN 10212 [Inverter Limits Active DC Side Voltage Maximum].
00b = No power limit for this reason
01b = Power limited for this reason
10b = Error
 ...";
CM_ SG_ 2566613502 PLedDueToDCSideCurMin "Output power is being limited due to SPN 10175 [Inverter DC Side Current] approaching or falling below the SPN 10215 [Inverter Limits Active DC Side Current Minimum].
00b = No power limit for this reason
01b = Power limited for this reason
10b = ...";
CM_ SG_ 2566613502 PLedDueToDCSideCurMax "Output power is being limited due to SPN 10175 [Inverter DC Side Current] approaching or exceeding the SPN 10214 [Inverter Limits Active DC Side Current Maximum].
00b = No power limit for this reason
01b = Power limited for this reason
10b = ...";
CM_ SG_ 2566613502 PLedDueToUndefinedReason "Output power is being limited due to an undefined reason.

00b = No power limit for this reason
01b = Power limited for this reason
10b = Error
11b = Not Available";
CM_ BO_ 2566613246 "Motor/Generator 2 Inverter Isolation Integrity
The electrical isolation Integrity status of the Inverter.  Some examples of use would be for a hybrid or electric vehicle propulsion motor or generator.";
CM_ SG_ 2566613246 HVBusPassiveIsolTestResults "The isolation resistance that resulted from the High-Voltage Bus Passive Isolation Test.
See SPN 10814 [High-Voltage Bus Passive Isolation Test Status] for test status and SPN 10807 [High-Voltage Bus Passive Isolation Test Command] for the command ...";
CM_ SG_ 2566613246 HVBusActiveIsolTestResults "The isolation resistance that resulted from the High-Voltage Bus Active Isolation Test.
See SPN 10813 [High-Voltage Bus Active Isolation Test Status] for test status and SPN 10806 [High-Voltage Bus Active Isolation Test Command] for the command to ...";
CM_ SG_ 2566613246 HVBusPassiveIsolTestStatus "Status of the high-voltage bus electrical passive isolation test as performed by this instance of the Motor/Generator.
0000b = No test requested / No test in process
0001b = Test requested but not yet in process
0010b = Test in process
0011b = ...";
CM_ SG_ 2566613246 HVBusActiveIsolTestStatus "Status of the high-voltage bus electrical active isolation test as performed by this instance of the motor/generator.
0000b = No test requested / No test in process
0001b = Test requested but not yet in process
0010b = Test in process
0011b = ...";
CM_ SG_ 2566613246 DCSideNegToChassisGroundV "The voltage level of the high voltage DC side, as measured by the inverter between the negative side of the High Voltage DC Side input and the chassis of the inverter enclosure.  This voltage can be used for system level monitoring of DC Side High ...";
CM_ SG_ 2566613246 Counter "The message counter is used to detect situations where the transmitting ECU malfunction repeats the same frame all the time. The receiver of the information may use the counter parameter to detect this situation. The transmitting device will ...";
CM_ SG_ 2566613246 CRC "The CRC is defined as follows:
• Length: 8 bits
• Polynomial: x^8+x^5+x^3+x^2+x+1
• Initial Value: FFh
• Input Data Reflection: Not reflected
• Result Data Reflection: Not reflected
• XOR value: FFh
SAE makes no claim of the functional safety ...";
BA_DEF_ SG_  "GenSigInactiveValue" INT 0 0;
BA_DEF_ SG_  "SigType" ENUM  "Default","Range","RangeSigned","ASCII","Discrete","Control","ReferencePGN","DTC","StringDelimiter","StringLength","StringLengthControl","MessageCounter","MessageChecksum";
BA_DEF_ SG_  "GenSigStartValue" INT 0 2147483647;
BA_DEF_ SG_  "GenSigSendType" ENUM  "Cyclic","OnWrite","OnWriteWithRepetition","OnChange","OnChangeWithRepetition","IfActive","IfActiveWithRepetition","NoSigSendType";
BA_DEF_ SG_  "GenSigILSupport" ENUM  "No","Yes";
BA_DEF_ SG_  "SPN" INT 0 524287;
BA_DEF_ BO_  "J1939CPgSendTimeout" INT -1 3600000;
BA_DEF_ BO_  "J1939CPgTOS" INT 0 7;
BA_DEF_ BO_  "J1939PgAppearanceOnBus" ENUM  "Default","CAN_Extended","CANFD_Extended";
BA_DEF_ BO_  "FsJ1939UseCrcAndCounter" STRING ;
BA_DEF_ BO_  "TpJ1939VarDlc" ENUM  "No","Yes";
BA_DEF_ BO_  "GenMsgNrOfRepetition" INT 0 1000000;
BA_DEF_ BO_  "GenMsgCycleTimeFast" INT 0 3600000;
BA_DEF_ BO_  "GenMsgFastOnStart" INT 0 100000;
BA_DEF_ BO_  "GenMsgStartDelayTime" INT 0 100000;
BA_DEF_ BO_  "GenMsgILSupport" ENUM  "No","Yes";
BA_DEF_ BO_  "GenMsgDelayTime" INT 0 1000;
BA_DEF_ BO_  "GenMsgRequestable" INT 0 1;
BA_DEF_ BO_  "GenMsgSendType" ENUM  "cyclic","NotUsed","NotUsed","NotUsed","NotUsed","NotUsed","NotUsed","IfActive","noMsgSendType";
BA_DEF_ BO_  "VFrameFormat" ENUM  "StandardCAN","ExtendedCAN","reserved","J1939PG","reserved","reserved","reserved","reserved","reserved","reserved","reserved","reserved","reserved","reserved","StandardCAN_FD","ExtendedCAN_FD";
BA_DEF_ BO_  "SingleFrame" INT 0 1;
BA_DEF_ BO_  "GenMsgCycleTime" INT 0 3600000;
BA_DEF_ SG_  "SystemSignalLongSymbol" STRING ;
BA_DEF_DEF_  "GenSigInactiveValue" 0;
BA_DEF_DEF_  "SigType" "Default";
BA_DEF_DEF_  "GenSigStartValue" 0;
BA_DEF_DEF_  "GenSigSendType" "NoSigSendType";
BA_DEF_DEF_  "GenSigILSupport" "Yes";
BA_DEF_DEF_  "SPN" 0;
BA_DEF_DEF_  "J1939CPgSendTimeout" -1;
BA_DEF_DEF_  "J1939CPgTOS" 2;
BA_DEF_DEF_  "J1939PgAppearanceOnBus" "Default";
BA_DEF_DEF_  "FsJ1939UseCrcAndCounter" "";
BA_DEF_DEF_  "TpJ1939VarDlc" "No";
BA_DEF_DEF_  "GenMsgNrOfRepetition" 0;
BA_DEF_DEF_  "GenMsgCycleTimeFast" 0;
BA_DEF_DEF_  "GenMsgFastOnStart" 0;
BA_DEF_DEF_  "GenMsgStartDelayTime" 0;
BA_DEF_DEF_  "GenMsgILSupport" "Yes";
BA_DEF_DEF_  "GenMsgDelayTime" 0;
BA_DEF_DEF_  "GenMsgRequestable" 1;
BA_DEF_DEF_  "GenMsgSendType" "noMsgSendType";
BA_DEF_DEF_  "VFrameFormat" "J1939PG";
BA_DEF_DEF_  "SingleFrame" 1;
BA_DEF_DEF_  "GenMsgCycleTime" 0;
BA_DEF_DEF_  "SystemSignalLongSymbol" "";
BA_ "GenMsgSendType" BO_ 2364677630 0;
BA_ "GenMsgCycleTime" BO_ 2364677630 100;
BA_ "GenMsgSendType" BO_ 2364677374 0;
BA_ "GenMsgCycleTime" BO_ 2364677374 100;
BA_ "FsJ1939UseCrcAndCounter" BO_ 2364677118 "Aa";
BA_ "GenMsgDelayTime" BO_ 2364677118 20;
BA_ "GenMsgSendType" BO_ 2364677118 0;
BA_ "GenMsgCycleTime" BO_ 2364677118 100;
BA_ "GenMsgSendType" BO_ 2364676862 0;
BA_ "GenMsgCycleTime" BO_ 2364676862 100;
BA_ "GenMsgSendType" BO_ 2364676606 0;
BA_ "GenMsgCycleTime" BO_ 2364676606 20;
BA_ "GenMsgSendType" BO_ 2364676350 0;
BA_ "GenMsgCycleTime" BO_ 2364676350 100;
BA_ "GenMsgSendType" BO_ 2364676094 0;
BA_ "GenMsgCycleTime" BO_ 2364676094 20;
BA_ "GenMsgSendType" BO_ 2364675838 0;
BA_ "GenMsgCycleTime" BO_ 2364675838 20;
BA_ "GenMsgSendType" BO_ 2364675582 0;
BA_ "GenMsgCycleTime" BO_ 2364675582 20;
BA_ "GenMsgSendType" BO_ 2364675326 0;
BA_ "GenMsgCycleTime" BO_ 2364675326 100;
BA_ "GenMsgSendType" BO_ 2555641598 0;
BA_ "GenMsgCycleTime" BO_ 2555641598 100;
BA_ "TpJ1939VarDlc" BO_ 2555576062 1;
BA_ "TpJ1939VarDlc" BO_ 2555510526 1;
BA_ "TpJ1939VarDlc" BO_ 2555444990 1;
BA_ "FsJ1939UseCrcAndCounter" BO_ 2352217854 "Aa";
BA_ "GenMsgSendType" BO_ 2352217854 0;
BA_ "GenMsgCycleTime" BO_ 2352217854 20;
BA_ "FsJ1939UseCrcAndCounter" BO_ 2352152318 "Aa";
BA_ "GenMsgSendType" BO_ 2352152318 0;
BA_ "GenMsgCycleTime" BO_ 2352152318 20;
BA_ "FsJ1939UseCrcAndCounter" BO_ 2352086782 "Aa";
BA_ "GenMsgSendType" BO_ 2352086782 0;
BA_ "GenMsgCycleTime" BO_ 2352086782 20;
BA_ "FsJ1939UseCrcAndCounter" BO_ 2352021246 "Aa";
BA_ "GenMsgSendType" BO_ 2352021246 0;
BA_ "GenMsgCycleTime" BO_ 2352021246 20;
BA_ "GenMsgSendType" BO_ 2566618878 0;
BA_ "GenMsgCycleTime" BO_ 2566618878 1000;
BA_ "GenMsgSendType" BO_ 2566618622 0;
BA_ "GenMsgCycleTime" BO_ 2566618622 1000;
BA_ "GenMsgDelayTime" BO_ 2566616830 150;
BA_ "GenMsgSendType" BO_ 2566616830 0;
BA_ "GenMsgCycleTime" BO_ 2566616830 1000;
BA_ "FsJ1939UseCrcAndCounter" BO_ 2365289982 "Bc";
BA_ "GenMsgSendType" BO_ 2365289982 0;
BA_ "GenMsgCycleTime" BO_ 2365289982 1000;
BA_ "FsJ1939UseCrcAndCounter" BO_ 2365289726 "Bc";
BA_ "GenMsgSendType" BO_ 2365289726 0;
BA_ "GenMsgCycleTime" BO_ 2365289726 10;
BA_ "FsJ1939UseCrcAndCounter" BO_ 2365289470 "Bc";
BA_ "GenMsgSendType" BO_ 2365289470 0;
BA_ "GenMsgCycleTime" BO_ 2365289470 1000;
BA_ "GenMsgSendType" BO_ 2566615806 0;
BA_ "GenMsgCycleTime" BO_ 2566615806 1000;
BA_ "GenMsgSendType" BO_ 2566615550 0;
BA_ "GenMsgCycleTime" BO_ 2566615550 1000;
BA_ "GenMsgSendType" BO_ 2566615294 0;
BA_ "GenMsgCycleTime" BO_ 2566615294 1000;
BA_ "GenMsgSendType" BO_ 2566615038 0;
BA_ "GenMsgCycleTime" BO_ 2566615038 1000;
BA_ "FsJ1939UseCrcAndCounter" BO_ 2365288190 "Bc";
BA_ "GenMsgSendType" BO_ 2365288190 0;
BA_ "GenMsgCycleTime" BO_ 2365288190 1000;
BA_ "FsJ1939UseCrcAndCounter" BO_ 2365287934 "Bc";
BA_ "GenMsgSendType" BO_ 2365287934 0;
BA_ "GenMsgCycleTime" BO_ 2365287934 10;
BA_ "FsJ1939UseCrcAndCounter" BO_ 2365287678 "Bc";
BA_ "GenMsgSendType" BO_ 2365287678 0;
BA_ "GenMsgCycleTime" BO_ 2365287678 1000;
BA_ "GenMsgDelayTime" BO_ 2566614014 100;
BA_ "GenMsgSendType" BO_ 2566614014 0;
BA_ "GenMsgCycleTime" BO_ 2566614014 1000;
BA_ "FsJ1939UseCrcAndCounter" BO_ 2566613758 "Bc";
BA_ "GenMsgSendType" BO_ 2566613758 0;
BA_ "GenMsgCycleTime" BO_ 2566613758 250;
BA_ "GenMsgDelayTime" BO_ 2566613502 100;
BA_ "GenMsgSendType" BO_ 2566613502 0;
BA_ "GenMsgCycleTime" BO_ 2566613502 1000;
BA_ "FsJ1939UseCrcAndCounter" BO_ 2566613246 "Bc";
BA_ "GenMsgSendType" BO_ 2566613246 0;
BA_ "GenMsgCycleTime" BO_ 2566613246 250;
BA_ "SigType" SG_ 2364677630 Module32OperationalStatus 5;
BA_ "SPN" SG_ 2364677630 Module32OperationalStatus 14136;
BA_ "SigType" SG_ 2364677630 Module31OperationalStatus 5;
BA_ "SPN" SG_ 2364677630 Module31OperationalStatus 14135;
BA_ "SigType" SG_ 2364677630 Module30OperationalStatus 5;
BA_ "SPN" SG_ 2364677630 Module30OperationalStatus 14134;
BA_ "SigType" SG_ 2364677630 Module29OperationalStatus 5;
BA_ "SPN" SG_ 2364677630 Module29OperationalStatus 14133;
BA_ "SigType" SG_ 2364677630 Module28OperationalStatus 5;
BA_ "SPN" SG_ 2364677630 Module28OperationalStatus 14132;
BA_ "SigType" SG_ 2364677630 Module27OperationalStatus 5;
BA_ "SPN" SG_ 2364677630 Module27OperationalStatus 14131;
BA_ "SigType" SG_ 2364677630 Module26OperationalStatus 5;
BA_ "SPN" SG_ 2364677630 Module26OperationalStatus 14130;
BA_ "SigType" SG_ 2364677630 Module25OperationalStatus 5;
BA_ "SPN" SG_ 2364677630 Module25OperationalStatus 14129;
BA_ "SigType" SG_ 2364677630 Module24OperationalStatus 5;
BA_ "SPN" SG_ 2364677630 Module24OperationalStatus 14128;
BA_ "SigType" SG_ 2364677630 Module23OperationalStatus 5;
BA_ "SPN" SG_ 2364677630 Module23OperationalStatus 14127;
BA_ "SigType" SG_ 2364677630 Module22OperationalStatus 5;
BA_ "SPN" SG_ 2364677630 Module22OperationalStatus 14126;
BA_ "SigType" SG_ 2364677630 Module21OperationalStatus 5;
BA_ "SPN" SG_ 2364677630 Module21OperationalStatus 14125;
BA_ "SigType" SG_ 2364677630 Module20OperationalStatus 5;
BA_ "SPN" SG_ 2364677630 Module20OperationalStatus 14124;
BA_ "SigType" SG_ 2364677630 Module19OperationalStatus 5;
BA_ "SPN" SG_ 2364677630 Module19OperationalStatus 14123;
BA_ "SigType" SG_ 2364677630 Module18OperationalStatus 5;
BA_ "SPN" SG_ 2364677630 Module18OperationalStatus 14122;
BA_ "SigType" SG_ 2364677630 Module17OperationalStatus 5;
BA_ "SPN" SG_ 2364677630 Module17OperationalStatus 14121;
BA_ "SigType" SG_ 2364677630 Module16OperationalStatus 5;
BA_ "SPN" SG_ 2364677630 Module16OperationalStatus 14120;
BA_ "SigType" SG_ 2364677630 Module15OperationalStatus 5;
BA_ "SPN" SG_ 2364677630 Module15OperationalStatus 14119;
BA_ "SigType" SG_ 2364677630 Module14OperationalStatus 5;
BA_ "SPN" SG_ 2364677630 Module14OperationalStatus 14118;
BA_ "SigType" SG_ 2364677630 Module13OperationalStatus 5;
BA_ "SPN" SG_ 2364677630 Module13OperationalStatus 14117;
BA_ "SigType" SG_ 2364677630 Module12OperationalStatus 5;
BA_ "SPN" SG_ 2364677630 Module12OperationalStatus 14116;
BA_ "SigType" SG_ 2364677630 Module11OperationalStatus 5;
BA_ "SPN" SG_ 2364677630 Module11OperationalStatus 14115;
BA_ "SigType" SG_ 2364677630 Module10OperationalStatus 5;
BA_ "SPN" SG_ 2364677630 Module10OperationalStatus 14114;
BA_ "SigType" SG_ 2364677630 Module9OperationalStatus 5;
BA_ "SPN" SG_ 2364677630 Module9OperationalStatus 14113;
BA_ "SigType" SG_ 2364677630 Module8OperationalStatus 5;
BA_ "SPN" SG_ 2364677630 Module8OperationalStatus 14112;
BA_ "SigType" SG_ 2364677630 Module7OperationalStatus 5;
BA_ "SPN" SG_ 2364677630 Module7OperationalStatus 14111;
BA_ "SigType" SG_ 2364677630 Module6OperationalStatus 5;
BA_ "SPN" SG_ 2364677630 Module6OperationalStatus 14110;
BA_ "SigType" SG_ 2364677630 Module5OperationalStatus 5;
BA_ "SPN" SG_ 2364677630 Module5OperationalStatus 14109;
BA_ "SigType" SG_ 2364677630 Module4OperationalStatus 5;
BA_ "SPN" SG_ 2364677630 Module4OperationalStatus 14108;
BA_ "SigType" SG_ 2364677630 Module3OperationalStatus 5;
BA_ "SPN" SG_ 2364677630 Module3OperationalStatus 14107;
BA_ "SigType" SG_ 2364677630 Module2OperationalStatus 5;
BA_ "SPN" SG_ 2364677630 Module2OperationalStatus 14106;
BA_ "SigType" SG_ 2364677630 Module1OperationalStatus 5;
BA_ "SPN" SG_ 2364677630 Module1OperationalStatus 14105;
BA_ "SigType" SG_ 2364677374 MaxChargeVLmt 1;
BA_ "SPN" SG_ 2364677374 MaxChargeVLmt 14104;
BA_ "SPN" SG_ 2364677374 ChargeEnergyCapacity 14103;
BA_ "SPN" SG_ 2364677374 DisEnergyCapacity 14102;
BA_ "SigType" SG_ 2364677118 Status1CRC 12;
BA_ "SPN" SG_ 2364677118 Status1CRC 14101;
BA_ "SigType" SG_ 2364677118 Status1Counter 11;
BA_ "SPN" SG_ 2364677118 Status1Counter 14100;
BA_ "SPN" SG_ 2364677118 OperationalStatus 14099;
BA_ "SPN" SG_ 2364677118 HVBusConnectionStatus 14098;
BA_ "SigType" SG_ 2364677118 InternalChargerStatus 5;
BA_ "SPN" SG_ 2364677118 InternalChargerStatus 14097;
BA_ "SigType" SG_ 2364677118 CellBalancingActive 4;
BA_ "SPN" SG_ 2364677118 CellBalancingActive 14096;
BA_ "SigType" SG_ 2364677118 CellBalanceStatus 4;
BA_ "SPN" SG_ 2364677118 CellBalanceStatus 14095;
BA_ "SPN" SG_ 2364677118 StOfChargeStatus 14094;
BA_ "SigType" SG_ 2364677118 InertiaSwStatus 4;
BA_ "SPN" SG_ 2364677118 InertiaSwStatus 14093;
BA_ "SigType" SG_ 2364677118 HVILStatus 4;
BA_ "SPN" SG_ 2364677118 HVILStatus 14092;
BA_ "SPN" SG_ 2364677118 HVBusPassiveIsolTestStatus 14091;
BA_ "SPN" SG_ 2364677118 HVBusActiveIsolTestStatus 14090;
BA_ "SigType" SG_ 2364677118 CenterOfPackContactorSt 4;
BA_ "SPN" SG_ 2364677118 CenterOfPackContactorSt 14089;
BA_ "SigType" SG_ 2364677118 HVBusPreChargeRelaySt 4;
BA_ "SPN" SG_ 2364677118 HVBusPreChargeRelaySt 14088;
BA_ "SPN" SG_ 2364677118 HVBusDisconnectForewarning 14087;
BA_ "SigType" SG_ 2364677118 HVBusContactorSt14086 4;
BA_ "SPN" SG_ 2364677118 HVBusContactorSt14086 14086;
BA_ "SigType" SG_ 2364677118 HVBusContactorSt 4;
BA_ "SPN" SG_ 2364677118 HVBusContactorSt 14085;
BA_ "SigType" SG_ 2364676862 Temp 1;
BA_ "SPN" SG_ 2364676862 Temp 14084;
BA_ "SigType" SG_ 2364676862 ETemp 1;
BA_ "SPN" SG_ 2364676862 ETemp 14083;
BA_ "SigType" SG_ 2364676862 OutCoolantTemp 1;
BA_ "SPN" SG_ 2364676862 OutCoolantTemp 14082;
BA_ "SigType" SG_ 2364676862 InCoolantTemp 1;
BA_ "SPN" SG_ 2364676862 InCoolantTemp 14081;
BA_ "SigType" SG_ 2364676862 IgntV 1;
BA_ "SPN" SG_ 2364676862 IgntV 14080;
BA_ "SigType" SG_ 2364676862 BusV 1;
BA_ "SPN" SG_ 2364676862 BusV 14079;
BA_ "SigType" SG_ 2364676606 HighestCellStOfCharge 1;
BA_ "SPN" SG_ 2364676606 HighestCellStOfCharge 14078;
BA_ "SigType" SG_ 2364676606 LowestCellStOfCharge 1;
BA_ "SPN" SG_ 2364676606 LowestCellStOfCharge 14077;
BA_ "SigType" SG_ 2364676606 ChargeCurLmt 1;
BA_ "GenSigStartValue" SG_ 2364676606 ChargeCurLmt 32000;
BA_ "SPN" SG_ 2364676606 ChargeCurLmt 14076;
BA_ "SigType" SG_ 2364676606 DisCurLmt 1;
BA_ "SPN" SG_ 2364676606 DisCurLmt 14075;
BA_ "SigType" SG_ 2364676350 CellBalancingCount 1;
BA_ "SPN" SG_ 2364676350 CellBalancingCount 14074;
BA_ "SigType" SG_ 2364676350 ChargeCapacity 1;
BA_ "SPN" SG_ 2364676350 ChargeCapacity 14073;
BA_ "SigType" SG_ 2364676350 DisCapacity 1;
BA_ "SPN" SG_ 2364676350 DisCapacity 14072;
BA_ "SigType" SG_ 2364676094 CellTempDiffStatus 4;
BA_ "SPN" SG_ 2364676094 CellTempDiffStatus 14071;
BA_ "SigType" SG_ 2364676094 AvgCellTemp 1;
BA_ "SPN" SG_ 2364676094 AvgCellTemp 14070;
BA_ "SigType" SG_ 2364676094 LowestCellTemp 1;
BA_ "SPN" SG_ 2364676094 LowestCellTemp 14069;
BA_ "SigType" SG_ 2364676094 HighestCellTemp 1;
BA_ "SPN" SG_ 2364676094 HighestCellTemp 14068;
BA_ "SPN" SG_ 2364675838 CellVDiffStatus 14067;
BA_ "SigType" SG_ 2364675838 LowestCellV 1;
BA_ "SPN" SG_ 2364675838 LowestCellV 14066;
BA_ "SigType" SG_ 2364675838 HighestCellV 1;
BA_ "SPN" SG_ 2364675838 HighestCellV 14065;
BA_ "SigType" SG_ 2364675838 FastUpdateStOfCharge 1;
BA_ "SPN" SG_ 2364675838 FastUpdateStOfCharge 14064;
BA_ "SigType" SG_ 2364675582 Cur 1;
BA_ "SPN" SG_ 2364675582 Cur 14063;
BA_ "SigType" SG_ 2364675582 Lvl 1;
BA_ "SPN" SG_ 2364675582 Lvl 14062;
BA_ "SigType" SG_ 2364675582 AvailableChargePwr 1;
BA_ "SPN" SG_ 2364675582 AvailableChargePwr 14061;
BA_ "SigType" SG_ 2364675582 AvailableDisPwr 1;
BA_ "SPN" SG_ 2364675582 AvailableDisPwr 14060;
BA_ "SigType" SG_ 2364675326 ChargePLDueToAnUndefinedCause 4;
BA_ "SPN" SG_ 2364675326 ChargePLDueToAnUndefinedCause 14059;
BA_ "SigType" SG_ 2364675326 ChargePLDueToBatCur 4;
BA_ "SPN" SG_ 2364675326 ChargePLDueToBatCur 14058;
BA_ "SigType" SG_ 2364675326 ChargePLDueToBatOrCellV 4;
BA_ "SPN" SG_ 2364675326 ChargePLDueToBatOrCellV 14057;
BA_ "SigType" SG_ 2364675326 ChargePLDueToBatDiagCondition 4;
BA_ "SPN" SG_ 2364675326 ChargePLDueToBatDiagCondition 14056;
BA_ "SigType" SG_ 2364675326 ChargePLDueToBatTemp 4;
BA_ "SPN" SG_ 2364675326 ChargePLDueToBatTemp 14055;
BA_ "SigType" SG_ 2364675326 ChargePLDueToStOfCharge 4;
BA_ "SPN" SG_ 2364675326 ChargePLDueToStOfCharge 14054;
BA_ "SigType" SG_ 2364675326 DisPLDueToAnUndefinedCause 4;
BA_ "SPN" SG_ 2364675326 DisPLDueToAnUndefinedCause 14053;
BA_ "SigType" SG_ 2364675326 DisPLDueToBatCur 4;
BA_ "SPN" SG_ 2364675326 DisPLDueToBatCur 14052;
BA_ "SigType" SG_ 2364675326 DisPLDueToBatOrCellV 4;
BA_ "SPN" SG_ 2364675326 DisPLDueToBatOrCellV 14051;
BA_ "SigType" SG_ 2364675326 DisPLDueToBatDiagCondition 4;
BA_ "SPN" SG_ 2364675326 DisPLDueToBatDiagCondition 14050;
BA_ "SigType" SG_ 2364675326 DisPLDueToBatTemp 4;
BA_ "SPN" SG_ 2364675326 DisPLDueToBatTemp 14049;
BA_ "SigType" SG_ 2364675326 DisPLDueToStOfCharge 4;
BA_ "SPN" SG_ 2364675326 DisPLDueToStOfCharge 14048;
BA_ "SigType" SG_ 2555641598 ContactorCmd 4;
BA_ "SPN" SG_ 2555641598 ContactorCmd 22687;
BA_ "SigType" SG_ 2555641598 EVReady 5;
BA_ "SPN" SG_ 2555641598 EVReady 21085;
BA_ "SPN" SG_ 2555641598 DCStageReq 21084;
BA_ "SPN" SG_ 2555641598 ConnectorLockCmd 12864;
BA_ "SigType" SG_ 2555576062 DailyData 3;
BA_ "SPN" SG_ 2555576062 DailyData 12977;
BA_ "SigType" SG_ 2555576062 SetID 1;
BA_ "SPN" SG_ 2555576062 SetID 12976;
BA_ "SPN" SG_ 2555576062 ManufacturerID 12975;
BA_ "SPN" SG_ 2555576062 MessageInstancesRemaining 12974;
BA_ "SPN" SG_ 2555576062 MessageInstance 12973;
BA_ "SigType" SG_ 2555510526 WeeklyData 3;
BA_ "SPN" SG_ 2555510526 WeeklyData 12982;
BA_ "SigType" SG_ 2555510526 SetID 1;
BA_ "SPN" SG_ 2555510526 SetID 12981;
BA_ "SPN" SG_ 2555510526 ManufacturerID 12980;
BA_ "SPN" SG_ 2555510526 MessageInstancesRemaining 12979;
BA_ "SPN" SG_ 2555510526 MessageInstance 12978;
BA_ "SigType" SG_ 2555444990 MonthlyData 3;
BA_ "SPN" SG_ 2555444990 MonthlyData 12987;
BA_ "SigType" SG_ 2555444990 SetID 1;
BA_ "SPN" SG_ 2555444990 SetID 12986;
BA_ "SPN" SG_ 2555444990 ManufacturerID 12985;
BA_ "SPN" SG_ 2555444990 MessageInstancesRemaining 12984;
BA_ "SPN" SG_ 2555444990 MessageInstance 12983;
BA_ "SPN" SG_ 2555379454 TotalMonthlyMessageBytes 13002;
BA_ "SPN" SG_ 2555379454 TotalDailyMessageBytes 12996;
BA_ "SPN" SG_ 2555379454 LongestDailyMessageInstance 12995;
BA_ "SPN" SG_ 2555379454 TotalDailyMessageInstances 12994;
BA_ "SPN" SG_ 2555379454 LongestMonthlyMessageInstance 13001;
BA_ "SPN" SG_ 2555379454 TotalMonthlyMessageInstances 13000;
BA_ "SPN" SG_ 2555379454 TotalWeeklyMessageBytes 12999;
BA_ "SPN" SG_ 2555379454 LongestWeeklyMessageInstance 12998;
BA_ "SPN" SG_ 2555379454 TotalWeeklyMessageInstances 12997;
BA_ "SPN" SG_ 2555379454 ManufacturerID 12993;
BA_ "SigType" SG_ 2352217854 ThermalMnmgtMaintenanceReq 5;
BA_ "SPN" SG_ 2352217854 ThermalMnmgtMaintenanceReq 20888;
BA_ "SigType" SG_ 2352217854 Ctrl1CRC 12;
BA_ "SPN" SG_ 2352217854 Ctrl1CRC 14476;
BA_ "SigType" SG_ 2352217854 Ctrl1Counter 11;
BA_ "SPN" SG_ 2352217854 Ctrl1Counter 14475;
BA_ "SigType" SG_ 2352217854 HVBusLowSideResistorConnectReq 5;
BA_ "SPN" SG_ 2352217854 HVBusLowSideResistorConnectReq 14474;
BA_ "SigType" SG_ 2352217854 HVBusHiSideResistorConnectReq 5;
BA_ "SPN" SG_ 2352217854 HVBusHiSideResistorConnectReq 14473;
BA_ "SigType" SG_ 2352217854 OpConsent 4;
BA_ "SPN" SG_ 2352217854 OpConsent 14472;
BA_ "SigType" SG_ 2352217854 EnableInternalChargerCmd 5;
BA_ "SPN" SG_ 2352217854 EnableInternalChargerCmd 14471;
BA_ "SigType" SG_ 2352217854 CellBalancingCmd 5;
BA_ "SPN" SG_ 2352217854 CellBalancingCmd 14470;
BA_ "SigType" SG_ 2352217854 HVBusPassiveIsolTestCmd 5;
BA_ "SPN" SG_ 2352217854 HVBusPassiveIsolTestCmd 14469;
BA_ "SigType" SG_ 2352217854 HVBusActiveIsolTestCmd 5;
BA_ "SPN" SG_ 2352217854 HVBusActiveIsolTestCmd 14468;
BA_ "SigType" SG_ 2352217854 PwrDownCmd 5;
BA_ "SPN" SG_ 2352217854 PwrDownCmd 14467;
BA_ "SigType" SG_ 2352217854 HVBusConnectCmd 5;
BA_ "SPN" SG_ 2352217854 HVBusConnectCmd 14466;
BA_ "SigType" SG_ 2352152318 ThermalMnmgtMaintenanceReq 5;
BA_ "SPN" SG_ 2352152318 ThermalMnmgtMaintenanceReq 20887;
BA_ "SigType" SG_ 2352152318 Ctrl1CRC 12;
BA_ "SPN" SG_ 2352152318 Ctrl1CRC 14333;
BA_ "SigType" SG_ 2352152318 Ctrl1Counter 11;
BA_ "SPN" SG_ 2352152318 Ctrl1Counter 14332;
BA_ "SigType" SG_ 2352152318 HVBusLowSideResistorConnectReq 5;
BA_ "SPN" SG_ 2352152318 HVBusLowSideResistorConnectReq 14331;
BA_ "SigType" SG_ 2352152318 HVBusHiSideResistorConnectReq 5;
BA_ "SPN" SG_ 2352152318 HVBusHiSideResistorConnectReq 14330;
BA_ "SigType" SG_ 2352152318 OpConsent 4;
BA_ "SPN" SG_ 2352152318 OpConsent 14329;
BA_ "SigType" SG_ 2352152318 EnableInternalChargerCmd 5;
BA_ "SPN" SG_ 2352152318 EnableInternalChargerCmd 14328;
BA_ "SigType" SG_ 2352152318 CellBalancingCmd 5;
BA_ "SPN" SG_ 2352152318 CellBalancingCmd 14327;
BA_ "SigType" SG_ 2352152318 HVBusPassiveIsolTestCmd 5;
BA_ "SPN" SG_ 2352152318 HVBusPassiveIsolTestCmd 14326;
BA_ "SigType" SG_ 2352152318 HVBusActiveIsolTestCmd 5;
BA_ "SPN" SG_ 2352152318 HVBusActiveIsolTestCmd 14325;
BA_ "SigType" SG_ 2352152318 PwrDownCmd 5;
BA_ "SPN" SG_ 2352152318 PwrDownCmd 14324;
BA_ "SigType" SG_ 2352152318 HVBusConnectCmd 5;
BA_ "SPN" SG_ 2352152318 HVBusConnectCmd 14323;
BA_ "SigType" SG_ 2352086782 ThermalMnmgtMaintenanceReq 5;
BA_ "SPN" SG_ 2352086782 ThermalMnmgtMaintenanceReq 20886;
BA_ "SigType" SG_ 2352086782 Ctrl1CRC 12;
BA_ "SPN" SG_ 2352086782 Ctrl1CRC 14190;
BA_ "SigType" SG_ 2352086782 Ctrl1Counter 11;
BA_ "SPN" SG_ 2352086782 Ctrl1Counter 14189;
BA_ "SigType" SG_ 2352086782 HVBusLowSideResistorConnectReq 5;
BA_ "SPN" SG_ 2352086782 HVBusLowSideResistorConnectReq 14188;
BA_ "SigType" SG_ 2352086782 HVBusHiSideResistorConnectReq 5;
BA_ "SPN" SG_ 2352086782 HVBusHiSideResistorConnectReq 14187;
BA_ "SigType" SG_ 2352086782 OpConsent 4;
BA_ "SPN" SG_ 2352086782 OpConsent 14186;
BA_ "SigType" SG_ 2352086782 EnableInternalChargerCmd 5;
BA_ "SPN" SG_ 2352086782 EnableInternalChargerCmd 14185;
BA_ "SigType" SG_ 2352086782 CellBalancingCmd 5;
BA_ "SPN" SG_ 2352086782 CellBalancingCmd 14184;
BA_ "SigType" SG_ 2352086782 HVBusPassiveIsolTestCmd 5;
BA_ "SPN" SG_ 2352086782 HVBusPassiveIsolTestCmd 14183;
BA_ "SigType" SG_ 2352086782 HVBusActiveIsolTestCmd 5;
BA_ "SPN" SG_ 2352086782 HVBusActiveIsolTestCmd 14182;
BA_ "SigType" SG_ 2352086782 PwrDownCmd 5;
BA_ "SPN" SG_ 2352086782 PwrDownCmd 14181;
BA_ "SigType" SG_ 2352086782 HVBusConnectCmd 5;
BA_ "SPN" SG_ 2352086782 HVBusConnectCmd 14180;
BA_ "SigType" SG_ 2352021246 ThermalMnmgtMaintenanceReq 5;
BA_ "SPN" SG_ 2352021246 ThermalMnmgtMaintenanceReq 20885;
BA_ "SigType" SG_ 2352021246 Ctrl1CRC 12;
BA_ "SPN" SG_ 2352021246 Ctrl1CRC 14047;
BA_ "SigType" SG_ 2352021246 Ctrl1Counter 11;
BA_ "SPN" SG_ 2352021246 Ctrl1Counter 14046;
BA_ "SigType" SG_ 2352021246 HVBusLowSideResistorConnectReq 5;
BA_ "SPN" SG_ 2352021246 HVBusLowSideResistorConnectReq 14045;
BA_ "SigType" SG_ 2352021246 HVBusHiSideResistorConnectReq 5;
BA_ "SPN" SG_ 2352021246 HVBusHiSideResistorConnectReq 14044;
BA_ "SigType" SG_ 2352021246 OpConsent 4;
BA_ "SPN" SG_ 2352021246 OpConsent 14043;
BA_ "SigType" SG_ 2352021246 EnableInternalChargerCmd 5;
BA_ "SPN" SG_ 2352021246 EnableInternalChargerCmd 14042;
BA_ "SigType" SG_ 2352021246 CellBalancingCmd 5;
BA_ "SPN" SG_ 2352021246 CellBalancingCmd 14041;
BA_ "SigType" SG_ 2352021246 HVBusPassiveIsolTestCmd 5;
BA_ "SPN" SG_ 2352021246 HVBusPassiveIsolTestCmd 14040;
BA_ "SigType" SG_ 2352021246 HVBusActiveIsolTestCmd 5;
BA_ "SPN" SG_ 2352021246 HVBusActiveIsolTestCmd 14039;
BA_ "SigType" SG_ 2352021246 PwrDownCmd 5;
BA_ "SPN" SG_ 2352021246 PwrDownCmd 14038;
BA_ "SigType" SG_ 2352021246 HVBusConnectCmd 5;
BA_ "SPN" SG_ 2352021246 HVBusConnectCmd 14037;
BA_ "SigType" SG_ 2566619646 InitiateInh 5;
BA_ "SPN" SG_ 2566619646 InitiateInh 9761;
BA_ "SigType" SG_ 2566619646 InitiateReq 5;
BA_ "SPN" SG_ 2566619646 InitiateReq 9777;
BA_ "SPN" SG_ 2566619646 InitiateECUAddress 9776;
BA_ "SigType" SG_ 2566619390 AccelOvrdMaxSpd 1;
BA_ "SPN" SG_ 2566619390 AccelOvrdMaxSpd 9788;
BA_ "SigType" SG_ 2566619390 MaxPTOGovSetSpd 1;
BA_ "SPN" SG_ 2566619390 MaxPTOGovSetSpd 9787;
BA_ "SigType" SG_ 2566619390 MinPTOGovSetSpd 1;
BA_ "SPN" SG_ 2566619390 MinPTOGovSetSpd 9786;
BA_ "SigType" SG_ 2566619390 PreprogrammedPTOGovSetSpd8 1;
BA_ "SPN" SG_ 2566619390 PreprogrammedPTOGovSetSpd8 9785;
BA_ "SigType" SG_ 2566619390 PreprogrammedPTOGovSetSpd7 1;
BA_ "SPN" SG_ 2566619390 PreprogrammedPTOGovSetSpd7 9784;
BA_ "SigType" SG_ 2566619390 PreprogrammedPTOGovSetSpd6 1;
BA_ "SPN" SG_ 2566619390 PreprogrammedPTOGovSetSpd6 9783;
BA_ "SigType" SG_ 2566619390 PreprogrammedPTOGovSetSpd5 1;
BA_ "SPN" SG_ 2566619390 PreprogrammedPTOGovSetSpd5 9782;
BA_ "SigType" SG_ 2566619390 PreprogrammedPTOGovSetSpd4 1;
BA_ "SPN" SG_ 2566619390 PreprogrammedPTOGovSetSpd4 9781;
BA_ "SigType" SG_ 2566619390 PreprogrammedPTOGovSetSpd3 1;
BA_ "SPN" SG_ 2566619390 PreprogrammedPTOGovSetSpd3 9780;
BA_ "SigType" SG_ 2566619390 PreprogrammedPTOGovSetSpd2 1;
BA_ "SPN" SG_ 2566619390 PreprogrammedPTOGovSetSpd2 9779;
BA_ "SigType" SG_ 2566619390 PreprogrammedPTOGovSetSpd1 1;
BA_ "SPN" SG_ 2566619390 PreprogrammedPTOGovSetSpd1 9778;
BA_ "SigType" SG_ 2566619134 OilFilterBypassSwStatus 5;
BA_ "SPN" SG_ 2566619134 OilFilterBypassSwStatus 9815;
BA_ "SigType" SG_ 2566619134 GearBoxOutOilPress 1;
BA_ "SPN" SG_ 2566619134 GearBoxOutOilPress 9814;
BA_ "SigType" SG_ 2566619134 OilFilterDiffPress 1;
BA_ "SPN" SG_ 2566619134 OilFilterDiffPress 9813;
BA_ "SigType" SG_ 2566618878 OperatingStatus 5;
BA_ "SPN" SG_ 2566618878 OperatingStatus 9827;
BA_ "SigType" SG_ 2566618878 ServiceInd 5;
BA_ "SPN" SG_ 2566618878 ServiceInd 9826;
BA_ "SigType" SG_ 2566618878 Pwr 1;
BA_ "SPN" SG_ 2566618878 Pwr 9825;
BA_ "SigType" SG_ 2566618878 CtrlTemp 1;
BA_ "SPN" SG_ 2566618878 CtrlTemp 9824;
BA_ "SigType" SG_ 2566618878 MotorSpd 1;
BA_ "SPN" SG_ 2566618878 MotorSpd 9823;
BA_ "SigType" SG_ 2566618878 CtrlCmdStatus 5;
BA_ "SPN" SG_ 2566618878 CtrlCmdStatus 9822;
BA_ "SPN" SG_ 2566618878 CtrlStatusReasonCode 9821;
BA_ "SigType" SG_ 2566618878 EnableStatus 5;
BA_ "SPN" SG_ 2566618878 EnableStatus 9820;
BA_ "SigType" SG_ 2566618622 OperatingStatus 5;
BA_ "SPN" SG_ 2566618622 OperatingStatus 9840;
BA_ "SigType" SG_ 2566618622 ServiceInd 5;
BA_ "SPN" SG_ 2566618622 ServiceInd 9839;
BA_ "SigType" SG_ 2566618622 Pwr 1;
BA_ "SPN" SG_ 2566618622 Pwr 9838;
BA_ "SigType" SG_ 2566618622 CtrlTemp 1;
BA_ "SPN" SG_ 2566618622 CtrlTemp 9837;
BA_ "SigType" SG_ 2566618622 MotorSpd 1;
BA_ "SPN" SG_ 2566618622 MotorSpd 9836;
BA_ "SigType" SG_ 2566618622 CtrlCmdStatus 5;
BA_ "SPN" SG_ 2566618622 CtrlCmdStatus 9835;
BA_ "SPN" SG_ 2566618622 CtrlStatusReasonCode 9834;
BA_ "SigType" SG_ 2566618622 EnableStatus 5;
BA_ "SPN" SG_ 2566618622 EnableStatus 9833;
BA_ "SigType" SG_ 2566618110 Two0ExpansionGammaRatio 1;
BA_ "SPN" SG_ 2566618110 Two0ExpansionGammaRatio 10116;
BA_ "SigType" SG_ 2566618110 Two0CompressionGammaRatio 1;
BA_ "SPN" SG_ 2566618110 Two0CompressionGammaRatio 10115;
BA_ "SigType" SG_ 2566618110 One9ExpansionGammaRatio 1;
BA_ "SPN" SG_ 2566618110 One9ExpansionGammaRatio 10114;
BA_ "SigType" SG_ 2566618110 One9CompressionGammaRatio 1;
BA_ "SPN" SG_ 2566618110 One9CompressionGammaRatio 10113;
BA_ "SigType" SG_ 2566618110 One8ExpansionGammaRatio 1;
BA_ "SPN" SG_ 2566618110 One8ExpansionGammaRatio 10112;
BA_ "SigType" SG_ 2566618110 One8CompressionGammaRatio 1;
BA_ "SPN" SG_ 2566618110 One8CompressionGammaRatio 10111;
BA_ "SigType" SG_ 2566618110 One7ExpansionGammaRatio 1;
BA_ "SPN" SG_ 2566618110 One7ExpansionGammaRatio 10110;
BA_ "SigType" SG_ 2566618110 One7CompressionGammaRatio 1;
BA_ "SPN" SG_ 2566618110 One7CompressionGammaRatio 10109;
BA_ "SigType" SG_ 2566617854 One6ExpansionGammaRatio 1;
BA_ "SPN" SG_ 2566617854 One6ExpansionGammaRatio 10108;
BA_ "SigType" SG_ 2566617854 One6CompressionGammaRatio 1;
BA_ "SPN" SG_ 2566617854 One6CompressionGammaRatio 10107;
BA_ "SigType" SG_ 2566617854 One5ExpansionGammaRatio 1;
BA_ "SPN" SG_ 2566617854 One5ExpansionGammaRatio 10106;
BA_ "SigType" SG_ 2566617854 One5CompressionGammaRatio 1;
BA_ "SPN" SG_ 2566617854 One5CompressionGammaRatio 10105;
BA_ "SigType" SG_ 2566617854 One4ExpansionGammaRatio 1;
BA_ "SPN" SG_ 2566617854 One4ExpansionGammaRatio 10104;
BA_ "SigType" SG_ 2566617854 One4CompressionGammaRatio 1;
BA_ "SPN" SG_ 2566617854 One4CompressionGammaRatio 10103;
BA_ "SigType" SG_ 2566617854 One3ExpansionGammaRatio 1;
BA_ "SPN" SG_ 2566617854 One3ExpansionGammaRatio 10102;
BA_ "SigType" SG_ 2566617854 One3CompressionGammaRatio 1;
BA_ "SPN" SG_ 2566617854 One3CompressionGammaRatio 10101;
BA_ "SigType" SG_ 2566617598 One2ExpansionGammaRatio 1;
BA_ "SPN" SG_ 2566617598 One2ExpansionGammaRatio 10100;
BA_ "SigType" SG_ 2566617598 One2CompressionGammaRatio 1;
BA_ "SPN" SG_ 2566617598 One2CompressionGammaRatio 10099;
BA_ "SigType" SG_ 2566617598 One1ExpansionGammaRatio 1;
BA_ "SPN" SG_ 2566617598 One1ExpansionGammaRatio 10098;
BA_ "SigType" SG_ 2566617598 One1CompressionGammaRatio 1;
BA_ "SPN" SG_ 2566617598 One1CompressionGammaRatio 10097;
BA_ "SigType" SG_ 2566617598 One0ExpansionGammaRatio 1;
BA_ "SPN" SG_ 2566617598 One0ExpansionGammaRatio 10096;
BA_ "SigType" SG_ 2566617598 One0CompressionGammaRatio 1;
BA_ "SPN" SG_ 2566617598 One0CompressionGammaRatio 10095;
BA_ "SigType" SG_ 2566617598 NineExpansionGammaRatio 1;
BA_ "SPN" SG_ 2566617598 NineExpansionGammaRatio 10094;
BA_ "SigType" SG_ 2566617598 NineCompressionGammaRatio 1;
BA_ "SPN" SG_ 2566617598 NineCompressionGammaRatio 10093;
BA_ "SigType" SG_ 2566617342 EightExpansionGammaRatio 1;
BA_ "SPN" SG_ 2566617342 EightExpansionGammaRatio 10092;
BA_ "SigType" SG_ 2566617342 EightCompressionGammaRatio 1;
BA_ "SPN" SG_ 2566617342 EightCompressionGammaRatio 10091;
BA_ "SigType" SG_ 2566617342 SevenExpansionGammaRatio 1;
BA_ "SPN" SG_ 2566617342 SevenExpansionGammaRatio 10090;
BA_ "SigType" SG_ 2566617342 SevenCompressionGammaRatio 1;
BA_ "SPN" SG_ 2566617342 SevenCompressionGammaRatio 10089;
BA_ "SigType" SG_ 2566617342 SixExpansionGammaRatio 1;
BA_ "SPN" SG_ 2566617342 SixExpansionGammaRatio 10088;
BA_ "SigType" SG_ 2566617342 SixCompressionGammaRatio 1;
BA_ "SPN" SG_ 2566617342 SixCompressionGammaRatio 10087;
BA_ "SigType" SG_ 2566617342 FiveExpansionGammaRatio 1;
BA_ "SPN" SG_ 2566617342 FiveExpansionGammaRatio 10086;
BA_ "SigType" SG_ 2566617342 FiveCompressionGammaRatio 1;
BA_ "SPN" SG_ 2566617342 FiveCompressionGammaRatio 10085;
BA_ "SigType" SG_ 2566617086 FourExpansionGammaRatio 1;
BA_ "SPN" SG_ 2566617086 FourExpansionGammaRatio 10084;
BA_ "SigType" SG_ 2566617086 FourCompressionGammaRatio 1;
BA_ "SPN" SG_ 2566617086 FourCompressionGammaRatio 10083;
BA_ "SigType" SG_ 2566617086 ThreeExpansionGammaRatio 1;
BA_ "SPN" SG_ 2566617086 ThreeExpansionGammaRatio 10082;
BA_ "SigType" SG_ 2566617086 ThreeCompressionGammaRatio 1;
BA_ "SPN" SG_ 2566617086 ThreeCompressionGammaRatio 10081;
BA_ "SigType" SG_ 2566617086 TwoExpansionGammaRatio 1;
BA_ "SPN" SG_ 2566617086 TwoExpansionGammaRatio 10080;
BA_ "SigType" SG_ 2566617086 TwoCompressionGammaRatio 1;
BA_ "SPN" SG_ 2566617086 TwoCompressionGammaRatio 10079;
BA_ "SigType" SG_ 2566617086 OneExpansionGammaRatio 1;
BA_ "SPN" SG_ 2566617086 OneExpansionGammaRatio 10078;
BA_ "SigType" SG_ 2566617086 OneCompressionGammaRatio 1;
BA_ "SPN" SG_ 2566617086 OneCompressionGammaRatio 10077;
BA_ "SPN" SG_ 2566616830 SequenceCounter 10141;
BA_ "SPN" SG_ 2566616830 ZoneAlarmStatus3 10140;
BA_ "SPN" SG_ 2566616830 DetectionZone3 10138;
BA_ "SPN" SG_ 2566616830 DetectionLocation3 10139;
BA_ "SPN" SG_ 2566616830 ZoneAlarmStatus2 10137;
BA_ "SPN" SG_ 2566616830 DetectionZone2 10135;
BA_ "SPN" SG_ 2566616830 DetectionLocation2 10136;
BA_ "SPN" SG_ 2566616830 ZoneAlarmStatus1 10134;
BA_ "SPN" SG_ 2566616830 DetectionZone1 10132;
BA_ "SPN" SG_ 2566616830 DetectionLocation1 10133;
BA_ "SigType" SG_ 2365289982 Pwr 1;
BA_ "SPN" SG_ 2365289982 Pwr 10172;
BA_ "SigType" SG_ 2365289982 Spd 1;
BA_ "SPN" SG_ 2365289982 Spd 10171;
BA_ "SigType" SG_ 2365289982 Trq 1;
BA_ "SPN" SG_ 2365289982 Trq 10170;
BA_ "SigType" SG_ 2365289982 Counter 11;
BA_ "SPN" SG_ 2365289982 Counter 10169;
BA_ "SigType" SG_ 2365289982 CRC 12;
BA_ "SPN" SG_ 2365289982 CRC 10168;
BA_ "SPN" SG_ 2365289726 DCSideV 9101;
BA_ "SPN" SG_ 2365289726 DCSideCur 10175;
BA_ "SigType" SG_ 2365289726 Spd 1;
BA_ "SPN" SG_ 2365289726 Spd 9057;
BA_ "SPN" SG_ 2365289726 Trq 9061;
BA_ "SigType" SG_ 2365289726 Counter 11;
BA_ "SPN" SG_ 2365289726 Counter 10174;
BA_ "SigType" SG_ 2365289726 CRC 12;
BA_ "SPN" SG_ 2365289726 CRC 10173;
BA_ "SigType" SG_ 2365289470 V 1;
BA_ "SPN" SG_ 2365289470 V 10203;
BA_ "SigType" SG_ 2365289470 Cur 1;
BA_ "SPN" SG_ 2365289470 Cur 10202;
BA_ "SigType" SG_ 2365289470 Counter 11;
BA_ "SPN" SG_ 2365289470 Counter 10201;
BA_ "SigType" SG_ 2365289470 CRC 12;
BA_ "SPN" SG_ 2365289470 CRC 10200;
BA_ "SigType" SG_ 2566615806 Five 1;
BA_ "SPN" SG_ 2566615806 Five 20914;
BA_ "SigType" SG_ 2566615806 Four 1;
BA_ "SPN" SG_ 2566615806 Four 10219;
BA_ "SigType" SG_ 2566615806 Three 1;
BA_ "SPN" SG_ 2566615806 Three 10218;
BA_ "SigType" SG_ 2566615806 Two 1;
BA_ "SPN" SG_ 2566615806 Two 10217;
BA_ "SigType" SG_ 2566615806 One 1;
BA_ "SPN" SG_ 2566615806 One 10216;
BA_ "SigType" SG_ 2566615550 Temp4 1;
BA_ "SPN" SG_ 2566615550 Temp4 10222;
BA_ "SigType" SG_ 2566615550 Temp3 1;
BA_ "SPN" SG_ 2566615550 Temp3 10221;
BA_ "SigType" SG_ 2566615550 Temp2 1;
BA_ "SPN" SG_ 2566615550 Temp2 10220;
BA_ "SigType" SG_ 2566615550 Temp1 1;
BA_ "SPN" SG_ 2566615550 Temp1 9059;
BA_ "SigType" SG_ 2566615294 Temp4 1;
BA_ "SPN" SG_ 2566615294 Temp4 10288;
BA_ "SigType" SG_ 2566615294 Temp3 1;
BA_ "SPN" SG_ 2566615294 Temp3 10287;
BA_ "SigType" SG_ 2566615294 Temp2 1;
BA_ "SPN" SG_ 2566615294 Temp2 10286;
BA_ "SigType" SG_ 2566615294 Temp1 1;
BA_ "SPN" SG_ 2566615294 Temp1 9060;
BA_ "SigType" SG_ 2566615038 Five 1;
BA_ "SPN" SG_ 2566615038 Five 20915;
BA_ "SigType" SG_ 2566615038 Four 1;
BA_ "SPN" SG_ 2566615038 Four 10285;
BA_ "SigType" SG_ 2566615038 Three 1;
BA_ "SPN" SG_ 2566615038 Three 10284;
BA_ "SigType" SG_ 2566615038 Two 1;
BA_ "SPN" SG_ 2566615038 Two 10283;
BA_ "SigType" SG_ 2566615038 One 1;
BA_ "SPN" SG_ 2566615038 One 10282;
BA_ "SigType" SG_ 2365288190 V 1;
BA_ "SPN" SG_ 2365288190 V 10269;
BA_ "SigType" SG_ 2365288190 Cur 1;
BA_ "SPN" SG_ 2365288190 Cur 10268;
BA_ "SigType" SG_ 2365288190 Counter 11;
BA_ "SPN" SG_ 2365288190 Counter 10267;
BA_ "SigType" SG_ 2365288190 CRC 12;
BA_ "SPN" SG_ 2365288190 CRC 10266;
BA_ "SPN" SG_ 2365287934 DCSideV 9102;
BA_ "SPN" SG_ 2365287934 DCSideCur 10241;
BA_ "SigType" SG_ 2365287934 Spd 1;
BA_ "SPN" SG_ 2365287934 Spd 9058;
BA_ "SPN" SG_ 2365287934 Trq 9062;
BA_ "SigType" SG_ 2365287934 Counter 11;
BA_ "SPN" SG_ 2365287934 Counter 10240;
BA_ "SigType" SG_ 2365287934 CRC 12;
BA_ "SPN" SG_ 2365287934 CRC 10239;
BA_ "SigType" SG_ 2365287678 Pwr 1;
BA_ "SPN" SG_ 2365287678 Pwr 10238;
BA_ "SigType" SG_ 2365287678 Spd 1;
BA_ "SPN" SG_ 2365287678 Spd 10237;
BA_ "SigType" SG_ 2365287678 Trq 1;
BA_ "SPN" SG_ 2365287678 Trq 10236;
BA_ "SigType" SG_ 2365287678 Counter 11;
BA_ "SPN" SG_ 2365287678 Counter 10235;
BA_ "SigType" SG_ 2365287678 CRC 12;
BA_ "SPN" SG_ 2365287678 CRC 10234;
BA_ "SPN" SG_ 2566614014 OffBoardChargerAvailablility 20806;
BA_ "SPN" SG_ 2566614014 OnBoardChargerAvailablility 20805;
BA_ "SPN" SG_ 2566614014 EPTOAvailability 20804;
BA_ "SPN" SG_ 2566614014 AuxiliariesAvailability 20803;
BA_ "SPN" SG_ 2566614014 DrivelineAvailability 20802;
BA_ "SPN" SG_ 2566614014 DCBusAvailability 10298;
BA_ "SigType" SG_ 2566613758 HVBusPassiveIsolTestResults 1;
BA_ "SPN" SG_ 2566613758 HVBusPassiveIsolTestResults 10778;
BA_ "SigType" SG_ 2566613758 HVBusActiveIsolTestResults 1;
BA_ "SPN" SG_ 2566613758 HVBusActiveIsolTestResults 10777;
BA_ "SPN" SG_ 2566613758 HVBusPassiveIsolTestStatus 10776;
BA_ "SPN" SG_ 2566613758 HVBusActiveIsolTestStatus 10775;
BA_ "SPN" SG_ 2566613758 DCSideNegToChassisGroundV 10774;
BA_ "SigType" SG_ 2566613758 Counter 11;
BA_ "SPN" SG_ 2566613758 Counter 10773;
BA_ "SigType" SG_ 2566613758 CRC 12;
BA_ "SPN" SG_ 2566613758 CRC 10772;
BA_ "SigType" SG_ 2566613502 TrqLimDueToMachineCharacteristic 4;
BA_ "SPN" SG_ 2566613502 TrqLimDueToMachineCharacteristic 13044;
BA_ "SystemSignalLongSymbol" SG_ 2566613502 TrqLimDueToMachineCharacteristic "TrqLimDueToMachineCharacteristics";
BA_ "SigType" SG_ 2566613502 PLedDueToActiveSpdRateLmt 4;
BA_ "SPN" SG_ 2566613502 PLedDueToActiveSpdRateLmt 13043;
BA_ "SigType" SG_ 2566613502 PLedDueToActiveTrqRateLmt 4;
BA_ "SPN" SG_ 2566613502 PLedDueToActiveTrqRateLmt 13042;
BA_ "SigType" SG_ 2566613502 PLedDueToFaultCondition 4;
BA_ "SPN" SG_ 2566613502 PLedDueToFaultCondition 13041;
BA_ "SigType" SG_ 2566613502 PLedDueToMotorTemp 4;
BA_ "SPN" SG_ 2566613502 PLedDueToMotorTemp 10793;
BA_ "SigType" SG_ 2566613502 PLedDueToInvTemp 4;
BA_ "SPN" SG_ 2566613502 PLedDueToInvTemp 10792;
BA_ "SigType" SG_ 2566613502 PLedDueToSpdMin 4;
BA_ "SPN" SG_ 2566613502 PLedDueToSpdMin 10791;
BA_ "SigType" SG_ 2566613502 PLedDueToSpdMax 4;
BA_ "SPN" SG_ 2566613502 PLedDueToSpdMax 10790;
BA_ "SigType" SG_ 2566613502 PLedDueToTrqMin 4;
BA_ "SPN" SG_ 2566613502 PLedDueToTrqMin 10789;
BA_ "SigType" SG_ 2566613502 PLedDueToTrqMax 4;
BA_ "SPN" SG_ 2566613502 PLedDueToTrqMax 10788;
BA_ "SigType" SG_ 2566613502 PLedDueToDCSidePwrMin 4;
BA_ "SPN" SG_ 2566613502 PLedDueToDCSidePwrMin 10787;
BA_ "SigType" SG_ 2566613502 PLedDueToDCSidePwrMax 4;
BA_ "SPN" SG_ 2566613502 PLedDueToDCSidePwrMax 10786;
BA_ "SigType" SG_ 2566613502 PLedDueToMechPwrMin 4;
BA_ "SPN" SG_ 2566613502 PLedDueToMechPwrMin 10785;
BA_ "SigType" SG_ 2566613502 PLedDueToMechPwrMax 4;
BA_ "SPN" SG_ 2566613502 PLedDueToMechPwrMax 10784;
BA_ "SigType" SG_ 2566613502 PLedDueToDCSideVMin 4;
BA_ "SPN" SG_ 2566613502 PLedDueToDCSideVMin 10783;
BA_ "SigType" SG_ 2566613502 PLedDueToDCSideVMax 4;
BA_ "SPN" SG_ 2566613502 PLedDueToDCSideVMax 10782;
BA_ "SigType" SG_ 2566613502 PLedDueToDCSideCurMin 4;
BA_ "SPN" SG_ 2566613502 PLedDueToDCSideCurMin 10781;
BA_ "SigType" SG_ 2566613502 PLedDueToDCSideCurMax 4;
BA_ "SPN" SG_ 2566613502 PLedDueToDCSideCurMax 10780;
BA_ "SigType" SG_ 2566613502 PLedDueToUndefinedReason 4;
BA_ "SPN" SG_ 2566613502 PLedDueToUndefinedReason 10779;
BA_ "SigType" SG_ 2566613246 HVBusPassiveIsolTestResults 1;
BA_ "SPN" SG_ 2566613246 HVBusPassiveIsolTestResults 10816;
BA_ "SigType" SG_ 2566613246 HVBusActiveIsolTestResults 1;
BA_ "SPN" SG_ 2566613246 HVBusActiveIsolTestResults 10815;
BA_ "SPN" SG_ 2566613246 HVBusPassiveIsolTestStatus 10814;
BA_ "SPN" SG_ 2566613246 HVBusActiveIsolTestStatus 10813;
BA_ "SPN" SG_ 2566613246 DCSideNegToChassisGroundV 10812;
BA_ "SigType" SG_ 2566613246 Counter 11;
BA_ "SPN" SG_ 2566613246 Counter 10811;
BA_ "SigType" SG_ 2566613246 CRC 12;
BA_ "SPN" SG_ 2566613246 CRC 10810;
VAL_ 2364677630 Module32OperationalStatus 3 "Not Available" 2 "Error" 1 "Operational" 0 "Not Operational" ;
VAL_ 2364677630 Module31OperationalStatus 3 "Not Available" 2 "Error" 1 "Operational" 0 "Not Operational" ;
VAL_ 2364677630 Module30OperationalStatus 3 "Not Available" 2 "Error" 1 "Operational" 0 "Not Operational" ;
VAL_ 2364677630 Module29OperationalStatus 3 "Not Available" 2 "Error" 1 "Operational" 0 "Not Operational" ;
VAL_ 2364677630 Module28OperationalStatus 3 "Not Available" 2 "Error" 1 "Operational" 0 "Not Operational" ;
VAL_ 2364677630 Module27OperationalStatus 3 "Not Available" 2 "Error" 1 "Operational" 0 "Not Operational" ;
VAL_ 2364677630 Module26OperationalStatus 3 "Not Available" 2 "Error" 1 "Operational" 0 "Not Operational" ;
VAL_ 2364677630 Module25OperationalStatus 3 "Not Available" 2 "Error" 1 "Operational" 0 "Not Operational" ;
VAL_ 2364677630 Module24OperationalStatus 3 "Not Available" 2 "Error" 1 "Operational" 0 "Not Operational" ;
VAL_ 2364677630 Module23OperationalStatus 3 "Not Available" 2 "Error" 1 "Operational" 0 "Not Operational" ;
VAL_ 2364677630 Module22OperationalStatus 3 "Not Available" 2 "Error" 1 "Operational" 0 "Not Operational" ;
VAL_ 2364677630 Module21OperationalStatus 3 "Not Available" 2 "Error" 1 "Operational" 0 "Not Operational" ;
VAL_ 2364677630 Module20OperationalStatus 3 "Not Available" 2 "Error" 1 "Operational" 0 "Not Operational" ;
VAL_ 2364677630 Module19OperationalStatus 3 "Not Available" 2 "Error" 1 "Operational" 0 "Not Operational" ;
VAL_ 2364677630 Module18OperationalStatus 3 "Not Available" 2 "Error" 1 "Operational" 0 "Not Operational" ;
VAL_ 2364677630 Module17OperationalStatus 3 "Not Available" 2 "Error" 1 "Operational" 0 "Not Operational" ;
VAL_ 2364677630 Module16OperationalStatus 3 "Not Available" 2 "Error" 1 "Operational" 0 "Not Operational" ;
VAL_ 2364677630 Module15OperationalStatus 3 "Not Available" 2 "Error" 1 "Operational" 0 "Not Operational" ;
VAL_ 2364677630 Module14OperationalStatus 3 "Not Available" 2 "Error" 1 "Operational" 0 "Not Operational" ;
VAL_ 2364677630 Module13OperationalStatus 3 "Not Available" 2 "Error" 1 "Operational" 0 "Not Operational" ;
VAL_ 2364677630 Module12OperationalStatus 3 "Not Available" 2 "Error" 1 "Operational" 0 "Not Operational" ;
VAL_ 2364677630 Module11OperationalStatus 3 "Not Available" 2 "Error" 1 "Operational" 0 "Not Operational" ;
VAL_ 2364677630 Module10OperationalStatus 3 "Not Available" 2 "Error" 1 "Operational" 0 "Not Operational" ;
VAL_ 2364677630 Module9OperationalStatus 3 "Not Available" 2 "Error" 1 "Operational" 0 "Not Operational" ;
VAL_ 2364677630 Module8OperationalStatus 3 "Not Available" 2 "Error" 1 "Operational" 0 "Not Operational" ;
VAL_ 2364677630 Module7OperationalStatus 3 "Not Available" 2 "Error" 1 "Operational" 0 "Not Operational" ;
VAL_ 2364677630 Module6OperationalStatus 3 "Not Available" 2 "Error" 1 "Operational" 0 "Not Operational" ;
VAL_ 2364677630 Module5OperationalStatus 3 "Not Available" 2 "Error" 1 "Operational" 0 "Not Operational" ;
VAL_ 2364677630 Module4OperationalStatus 3 "Not Available" 2 "Error" 1 "Operational" 0 "Not Operational" ;
VAL_ 2364677630 Module3OperationalStatus 3 "Not Available" 2 "Error" 1 "Operational" 0 "Not Operational" ;
VAL_ 2364677630 Module2OperationalStatus 3 "Not Available" 2 "Error" 1 "Operational" 0 "Not Operational" ;
VAL_ 2364677630 Module1OperationalStatus 3 "Not Available" 2 "Error" 1 "Operational" 0 "Not Operational" ;
VAL_ 2364677118 OperationalStatus 15 "Not Available" 14 "Error" 13 "Reserved" 12 "Reserved" 11 "Reserved" 10 "Reserved" 9 "Reserved" 8 "Reserved" 7 "Reserved" 6 "Disabled by internal decision of HVES controller" 5 "Disabled by external command" 4 "Emergency Power-Down In Process" 3 "Normal Power-Down in Process" 2 "Operational." 1 "Initialization Complete" 0 "Initialization in process" ;
VAL_ 2364677118 HVBusConnectionStatus 15 "Not Available" 14 "Error" 13 "Reserved" 12 "Reserved" 11 "Reserved" 10 "Reserved" 9 "Reserved" 8 "Reserved" 7 "Reserved" 6 "Reserved" 5 "Reserved" 4 "Disconnected,  Precharge Failed" 3 "Disconnection in Process" 2 "Connection in Process" 1 "Connected" 0 "Disconnected, One or more contactors are open" ;
VAL_ 2364677118 InternalChargerStatus 3 "Not Available" 2 "Error" 1 "Charging on" 0 "Charging off" ;
VAL_ 2364677118 CellBalancingActive 3 "Not Available" 2 "Error" 1 "Cell balancing is active" 0 "Cell balancing is not active" ;
VAL_ 2364677118 CellBalanceStatus 3 "Not Available" 2 "Error" 1 "Cells are unbalanced" 0 "Cells are balanced" ;
VAL_ 2364677118 StOfChargeStatus 15 "Not  Available" 14 "Error" 13 "Reserved" 12 "Reserved" 11 "Reserved" 10 "Reserved" 9 "Reserved" 8 "Reserved" 7 "Reserved" 6 "SOC is above its recommended upper limit" 5 "SOC is at its recommended upper limit" 4 "SOC is approaching its recommended upper limit" 3 "SOC is below its recommended lower limit" 2 "SOC is at its recommended lower limit" 1 "SOC is approaching its recommended lower limit" 0 "SOC level is acceptable" ;
VAL_ 2364677118 InertiaSwStatus 3 "Not Available" 2 "Error" 1 "Impact sensed" 0 "No impact sensed" ;
VAL_ 2364677118 HVILStatus 3 "Not Available" 2 "Error" 1 "HVIL Open" 0 "HVIL Closed" ;
VAL_ 2364677118 HVBusPassiveIsolTestStatus 15 "Not available" 14 "Error" 13 "Reserved" 12 "Reserved" 11 "Reserved" 10 "Reserved" 9 "Reserved" 8 "Reserved" 7 "Reserved" 6 "Reserved" 5 "Test complete,  isolation fault" 4 "Test complete,  isolation marginal" 3 "Test complete,  isolation acceptable" 2 "Test in process" 1 "Test requested but not yet in process" 0 "No test requested / No test in process" ;
VAL_ 2364677118 HVBusActiveIsolTestStatus 15 "Not available" 14 "Error" 13 "Reserved" 12 "Reserved" 11 "Reserved" 10 "Reserved" 9 "Reserved" 8 "Reserved" 7 "Reserved" 6 "Reserved" 5 "Test complete,  isolation fault" 4 "Test complete,  isolation marginal" 3 "Test complete,  isolation acceptable" 2 "Test in process" 1 "Test requested but not yet in process" 0 "No test requested / No test in process" ;
VAL_ 2364677118 CenterOfPackContactorSt 3 "Not Available" 2 "Error" 1 "Contactor Closed" 0 "Contactor Open" ;
VAL_ 2364677118 HVBusPreChargeRelaySt 3 "Not Available" 2 "Error" 1 "Relay Closed" 0 "Relay Open" ;
VAL_ 2364677118 HVBusDisconnectForewarning 15 "Not Available" 14 "Error" 13 "Disconnect imminent" 12 "Reserved" 11 "Reserved" 10 "Reserved" 9 "Reserved" 8 "Reserved" 7 "Disconnect imminent due to battery pack current approaching maximum acceptable level" 6 "Disconnect imminent due to cell voltage approaching maximum acceptable level" 5 "Disconnect imminent due to cell voltage approaching minimum acceptable level" 4 "Disconnect imminent due to module voltage approaching maximum acceptable level" 3 "Disconnect imminent due to module voltage approaching minimum acceptable level" 2 "Disconnect imminent due to battery pack voltage approaching maximum acceptable level" 1 "Disconnect imminent due to battery pack voltage approaching minimum acceptable level" 0 "Disconnect not pending" ;
VAL_ 2364677118 HVBusContactorSt14086 3 "Not Available" 2 "Error" 1 "Contactor Closed" 0 "Contactor Open" ;
VAL_ 2364677118 HVBusContactorSt 3 "Not Available" 2 "Error" 1 "Contactor Closed" 0 "Contactor Open" ;
VAL_ 2364676094 CellTempDiffStatus 3 "Not Available" 2 "Error" 1 "Cell-to-cell temperature differential exceeds acceptable limits" 0 "Cell-to-cell temperature differential is within acceptable limits" ;
VAL_ 2364675838 CellVDiffStatus 15 "Not Available" 14 "Error" 13 "Reserved" 12 "Reserved" 11 "Reserved" 10 "Reserved" 9 "Reserved" 8 "Reserved" 7 "Reserved" 6 "Reserved" 5 "Reserved" 4 "Exceeds limits and it is not known whether balancing can restore performance" 3 "Exceeds limits and external maintenance balancing cannot restore performance" 2 "Exceeds limits and external maintenance balancing is required" 1 "Exceeds limits and can be corrected via auto-balancing" 0 "Is within acceptable limits" ;
VAL_ 2364675326 ChargePLDueToAnUndefinedCause 3 "Not Available" 2 "Error" 1 "Power limited for this reason" 0 "No power limit for this reason" ;
VAL_ 2364675326 ChargePLDueToBatCur 3 "Not Available" 2 "Error" 1 "Power limited for this reason" 0 "No power limit for this reason" ;
VAL_ 2364675326 ChargePLDueToBatOrCellV 3 "Not Available" 2 "Error" 1 "Power limited for this reason" 0 "No power limit for this reason" ;
VAL_ 2364675326 ChargePLDueToBatDiagCondition 3 "Not Available" 2 "Error" 1 "Power limited for this reason" 0 "No power limit for this reason" ;
VAL_ 2364675326 ChargePLDueToBatTemp 3 "Not Available" 2 "Error" 1 "Power limited for this reason" 0 "No power limit for this reason" ;
VAL_ 2364675326 ChargePLDueToStOfCharge 3 "Not Available" 2 "Error" 1 "Power limited for this reason" 0 "No power limit for this reason" ;
VAL_ 2364675326 DisPLDueToAnUndefinedCause 3 "Not Available" 2 "Error" 1 "Power limited for this reason" 0 "No power limit for this reason" ;
VAL_ 2364675326 DisPLDueToBatCur 3 "Not Available" 2 "Error" 1 "Power limited for this reason" 0 "No power limit for this reason" ;
VAL_ 2364675326 DisPLDueToBatOrCellV 3 "Not Available" 2 "Error" 1 "Power limited for this reason" 0 "No power limit for this reason" ;
VAL_ 2364675326 DisPLDueToBatDiagCondition 3 "Not Available" 2 "Error" 1 "Power limited for this reason" 0 "No power limit for this reason" ;
VAL_ 2364675326 DisPLDueToBatTemp 3 "Not Available" 2 "Error" 1 "Power limited for this reason" 0 "No power limit for this reason" ;
VAL_ 2364675326 DisPLDueToStOfCharge 3 "Not Available" 2 "Error" 1 "Power limited for this reason" 0 "No power limit for this reason" ;
VAL_ 2555641598 ContactorCmd 3 "Don't Care / Take no action" 2 "Reserved" 1 "Close Contactor" 0 "Open Contactor" ;
VAL_ 2555641598 EVReady 3 "Not available" 2 "Reserved" 1 "Ready" 0 "Not Ready" ;
VAL_ 2555641598 DCStageReq 15 "Don't care" 14 "Reserved" 13 "Reserved" 12 "Reserved" 11 "Reserved" 10 "Reserved" 9 "Reserved" 8 "Termination Request" 7 "Welding Detection Request" 6 "Power Delivery Request, Ready To Charge State = FALSE)" 5 "Current Demand Request" 4 "Power Delivery Request, Ready To Charge State = TRUE)" 3 "Pre-Charge Request" 2 "Cable Check Request" 1 "Parameter Discovery Request" 0 "Idle" ;
VAL_ 2555641598 ConnectorLockCmd 15 "Don't care / Take no action" 14 "Reserved" 13 "Reserved" 12 "Reserved" 11 "Reserved" 10 "Reserved" 9 "Reserved" 8 "Reserved" 7 "Reserved" 6 "Reserved" 5 "Reserved" 4 "Reserved" 3 "Reserved" 2 "Reserved" 1 "Lock Request" 0 "Unlock Request" ;
VAL_ 2352217854 ThermalMnmgtMaintenanceReq 3 "Don't care/take no action" 2 "Reserved" 1 "HVESS Thermal Management Maintenance Mode is requested" 0 "HVESS Thermal Management Maintenance Mode is not requested" ;
VAL_ 2352217854 HVBusLowSideResistorConnectReq 3 "Don't care/take no action" 2 "Reserved" 1 "Connection Requested" 0 "Connection not Requested" ;
VAL_ 2352217854 HVBusHiSideResistorConnectReq 3 "Don't care/take no action" 2 "Reserved" 1 "Connection Requested" 0 "Connection not Requested" ;
VAL_ 2352217854 OpConsent 3 "Don't care/Take no action" 2 "Error" 1 "Consent given" 0 "Consent revoked" ;
VAL_ 2352217854 EnableInternalChargerCmd 3 "Don't care/Take no action" 2 "Reserved" 1 "Enable charging" 0 "Disable charging" ;
VAL_ 2352217854 CellBalancingCmd 3 "Don't care/Take no action" 2 "Reserved" 1 "Cell Balancing requested" 0 "Cell Balancing not requested" ;
VAL_ 2352217854 HVBusPassiveIsolTestCmd 3 "Don't care/Take no action" 2 "Reserved" 1 "Passive Isolation Test request" 0 "Passive Isolation Test not requested" ;
VAL_ 2352217854 HVBusActiveIsolTestCmd 3 "Don't care/Take no action" 2 "Reserved" 1 "Active Isolation Test request" 0 "Active Isolation Test not requested" ;
VAL_ 2352217854 PwrDownCmd 3 "Don't care/Take no action" 2 "Execute emergency power-down" 1 "Execute normal power-down" 0 "Power-down not requested" ;
VAL_ 2352217854 HVBusConnectCmd 3 "Don't care/Take no action" 2 "Emergency contactor closure request" 1 "Close Contactor" 0 "Open Contactor" ;
VAL_ 2352152318 ThermalMnmgtMaintenanceReq 3 "Don't care/take no action" 2 "Reserved" 1 "HVESS Thermal Management Maintenance Mode is requested" 0 "HVESS Thermal Management Maintenance Mode is not requested" ;
VAL_ 2352152318 HVBusLowSideResistorConnectReq 3 "Don't care/take no action" 2 "Reserved" 1 "Connection Requested" 0 "Connection not Requested" ;
VAL_ 2352152318 HVBusHiSideResistorConnectReq 3 "Don't care/take no action" 2 "Reserved" 1 "Connection Requested" 0 "Connection not Requested" ;
VAL_ 2352152318 OpConsent 3 "Don't care/Take no action" 2 "Error" 1 "Consent given" 0 "Consent revoked" ;
VAL_ 2352152318 EnableInternalChargerCmd 3 "Don't care/Take no action" 2 "Reserved" 1 "Enable charging" 0 "Disable charging" ;
VAL_ 2352152318 CellBalancingCmd 3 "Don't care/Take no action" 2 "Reserved" 1 "Cell Balancing requested" 0 "Cell Balancing not requested" ;
VAL_ 2352152318 HVBusPassiveIsolTestCmd 3 "Don't care/Take no action" 2 "Reserved" 1 "Passive Isolation Test request" 0 "Passive Isolation Test not requested" ;
VAL_ 2352152318 HVBusActiveIsolTestCmd 3 "Don't care/Take no action" 2 "Reserved" 1 "Active Isolation Test request" 0 "Active Isolation Test not requested" ;
VAL_ 2352152318 PwrDownCmd 3 "Don't care/Take no action" 2 "Execute emergency power-down" 1 "Execute normal power-down" 0 "Power-down not requested" ;
VAL_ 2352152318 HVBusConnectCmd 3 "Don't care/Take no action" 2 "Emergency contactor closure request" 1 "Close Contactor" 0 "Open Contactor" ;
VAL_ 2352086782 ThermalMnmgtMaintenanceReq 3 "Don't care/take no action" 2 "Reserved" 1 "HVESS Thermal Management Maintenance Mode is requested" 0 "HVESS Thermal Management Maintenance Mode is not requested" ;
VAL_ 2352086782 HVBusLowSideResistorConnectReq 3 "Don't care/take no action" 2 "Reserved" 1 "Connection Requested" 0 "Connection not Requested" ;
VAL_ 2352086782 HVBusHiSideResistorConnectReq 3 "Don't care/take no action" 2 "Reserved" 1 "Connection Requested" 0 "Connection not Requested" ;
VAL_ 2352086782 OpConsent 3 "Don't care/Take no action" 2 "Error" 1 "Consent given" 0 "Consent revoked" ;
VAL_ 2352086782 EnableInternalChargerCmd 3 "Don't care/Take no action" 2 "Reserved" 1 "Enable charging" 0 "Disable charging" ;
VAL_ 2352086782 CellBalancingCmd 3 "Don't care/Take no action" 2 "Reserved" 1 "Cell Balancing requested" 0 "Cell Balancing not requested" ;
VAL_ 2352086782 HVBusPassiveIsolTestCmd 3 "Don't care/Take no action" 2 "Reserved" 1 "Passive Isolation Test request" 0 "Passive Isolation Test not requested" ;
VAL_ 2352086782 HVBusActiveIsolTestCmd 3 "Don't care/Take no action" 2 "Reserved" 1 "Active Isolation Test request" 0 "Active Isolation Test not requested" ;
VAL_ 2352086782 PwrDownCmd 3 "Don't care/Take no action" 2 "Execute emergency power-down" 1 "Execute normal power-down" 0 "Power-down not requested" ;
VAL_ 2352086782 HVBusConnectCmd 3 "Don't care/Take no action" 2 "Emergency contactor closure request" 1 "Close Contactor" 0 "Open Contactor" ;
VAL_ 2352021246 ThermalMnmgtMaintenanceReq 3 "Don't care/take no action" 2 "Reserved" 1 "HVESS Thermal Management Maintenance Mode is requested" 0 "HVESS Thermal Management Maintenance Mode is not requested" ;
VAL_ 2352021246 HVBusLowSideResistorConnectReq 3 "Don't care/take no action" 2 "Reserved" 1 "Connection Requested" 0 "Connection not Requested" ;
VAL_ 2352021246 HVBusHiSideResistorConnectReq 3 "Don't care/take no action" 2 "Reserved" 1 "Connection Requested" 0 "Connection not Requested" ;
VAL_ 2352021246 OpConsent 3 "Don't care/Take no action" 2 "Error" 1 "Consent given" 0 "Consent revoked" ;
VAL_ 2352021246 EnableInternalChargerCmd 3 "Don't care/Take no action" 2 "Reserved" 1 "Enable charging" 0 "Disable charging" ;
VAL_ 2352021246 CellBalancingCmd 3 "Don't care/Take no action" 2 "Reserved" 1 "Cell Balancing requested" 0 "Cell Balancing not requested" ;
VAL_ 2352021246 HVBusPassiveIsolTestCmd 3 "Don't care/Take no action" 2 "Reserved" 1 "Passive Isolation Test request" 0 "Passive Isolation Test not requested" ;
VAL_ 2352021246 HVBusActiveIsolTestCmd 3 "Don't care/Take no action" 2 "Reserved" 1 "Active Isolation Test request" 0 "Active Isolation Test not requested" ;
VAL_ 2352021246 PwrDownCmd 3 "Don't care/Take no action" 2 "Execute emergency power-down" 1 "Execute normal power-down" 0 "Power-down not requested" ;
VAL_ 2352021246 HVBusConnectCmd 3 "Don't care/Take no action" 2 "Emergency contactor closure request" 1 "Close Contactor" 0 "Open Contactor" ;
VAL_ 2566619646 InitiateInh 3 "Don't care/take no action" 2 "Reserved" 1 "Programming is inhibited" 0 "Programming is not inhibited" ;
VAL_ 2566619646 InitiateReq 3 "Don't care/take no action" 2 "Reserved" 1 "Initiation of on board programming is requested" 0 "On board programming not requested" ;
VAL_ 2566619134 OilFilterBypassSwStatus 3 "Not available" 2 "Error" 1 "Bypassing" 0 "Not bypassing" ;
VAL_ 2566618878 OperatingStatus 3 "Not Available" 2 "Not Operable" 1 "Derated Operation" 0 "Normal Operation" ;
VAL_ 2566618878 ServiceInd 3 "Not Available" 2 "Reserved" 1 "Service Required" 0 "Service Not Required" ;
VAL_ 2566618878 CtrlCmdStatus 3 "Not Available" 2 "Default Command" 1 "External Command" 0 "Internal Command" ;
VAL_ 2566618878 CtrlStatusReasonCode 15 "Not Available" 14 "Reserved" 13 "Reserved" 12 "Reserved" 11 "Speed limited due to over-voltage protection" 10 "Low Flow Detected" 9 "Exceeding commanded speed due to external force" 8 "Speed limited due to over-temperature protection" 7 "Speed limited due to torque limit" 6 "Speed limited due to maximum system design capability" 5 "Speed Limited due to current" 4 "Over-Temperature Protection Shutdown" 3 "Under-Voltage Protection Shutdown" 2 "Over-Voltage Protection Shutdown" 1 "Unable to Start" 0 "Normal Operation" ;
VAL_ 2566618878 EnableStatus 3 "Not available" 2 "Accessory Motor On, Reverse Direction" 1 "Accessory Motor On, Normal" 0 "Accessory Motor Off" ;
VAL_ 2566618622 OperatingStatus 3 "Not Available" 2 "Not Operable" 1 "Derated Operation" 0 "Normal Operation" ;
VAL_ 2566618622 ServiceInd 3 "Not Available" 2 "Reserved" 1 "Service Required" 0 "Service Not Required" ;
VAL_ 2566618622 CtrlCmdStatus 3 "Not Available" 2 "Default Command" 1 "External Command" 0 "Internal Command" ;
VAL_ 2566618622 CtrlStatusReasonCode 13 "Reserved" 12 "Reserved" 11 "Speed limited due to over-voltage protection" 10 "Low Flow Detected" 9 "Exceeding commanded speed due to external force" 8 "Speed limited due to over-temperature protection" 7 "Speed limited due to torque limit" 6 "Speed limited due to maximum system design capability" 5 "Speed Limited due to current" 4 "Over-Temperature Protection Shutdown" 3 "Under-Voltage Protection Shutdown" 2 "Over-Voltage Protection Shutdown" 1 "Unable to Start" 0 "Normal Operation" 15 "Not Available" 14 "Reserved" ;
VAL_ 2566618622 EnableStatus 3 "Not available" 2 "Accessory Motor On, Reverse Direction" 1 "Accessory Motor On, Normal" 0 "Accessory Motor Off" ;
VAL_ 2566616830 ZoneAlarmStatus3 15 "Not Available or Not Installed" 14 "Error Indicator" 13 "Reserved for SAE assignment" 12 "Reserved for SAE assignment" 11 "Reserved for SAE assignment" 10 "Reserved for SAE assignment" 9 "Reserved for SAE assignment" 8 "Reserved for SAE assignment" 7 "Reserved for SAE assignment" 6 "Reserved for SAE assignment" 5 "Reserved for SAE assignment" 4 "Reserved for SAE assignment" 3 "Reserved for SAE assignment" 2 "Reserved for SAE assignment" 1 "Alarm Active" 0 "No Alarm Active" ;
VAL_ 2566616830 ZoneAlarmStatus2 15 "Not Available or Not Installed" 14 "Error Indicator" 13 "Reserved for SAE assignment" 12 "Reserved for SAE assignment" 11 "Reserved for SAE assignment" 10 "Reserved for SAE assignment" 9 "Reserved for SAE assignment" 8 "Reserved for SAE assignment" 7 "Reserved for SAE assignment" 6 "Reserved for SAE assignment" 5 "Reserved for SAE assignment" 4 "Reserved for SAE assignment" 3 "Reserved for SAE assignment" 2 "Reserved for SAE assignment" 1 "Alarm Active" 0 "No Alarm Active" ;
VAL_ 2566616830 ZoneAlarmStatus1 15 "Not Available or Not Installed" 14 "Error Indicator" 13 "Reserved for SAE assignment" 12 "Reserved for SAE assignment" 11 "Reserved for SAE assignment" 10 "Reserved for SAE assignment" 9 "Reserved for SAE assignment" 8 "Reserved for SAE assignment" 7 "Reserved for SAE assignment" 6 "Reserved for SAE assignment" 5 "Reserved for SAE assignment" 4 "Reserved for SAE assignment" 3 "Reserved for SAE assignment" 2 "Reserved for SAE assignment" 1 "Alarm Active" 0 "No Alarm Active" ;
VAL_ 2566614014 OffBoardChargerAvailablility 15 "Not Available" 14 "Error" 13 "SAE Reserved" 12 "SAE Reserved" 11 "SAE Reserved" 10 "SAE Reserved" 9 "SAE Reserved" 8 "SAE Reserved" 7 "SAE Reserved" 6 "SAE Reserved" 5 "High voltage DC bus disconnect forewarning" 4 "SAE Reserved" 3 "High voltage DC bus disconnection is in process" 2 "High voltage DC bus connection is in process of being connected." 1 "High voltage DC bus is connected." 0 "High voltage DC bus is not connected." ;
VAL_ 2566614014 OnBoardChargerAvailablility 15 "Not Available" 14 "Error" 13 "SAE Reserved" 12 "SAE Reserved" 11 "SAE Reserved" 10 "SAE Reserved" 9 "SAE Reserved" 8 "SAE Reserved" 7 "SAE Reserved" 6 "SAE Reserved" 5 "High voltage DC bus disconnect forewarning" 4 "SAE Reserved" 3 "High voltage DC bus disconnection is in process" 2 "High voltage DC bus connection is in process of being connected." 1 "High voltage DC bus is connected." 0 "High voltage DC bus is not connected." ;
VAL_ 2566614014 EPTOAvailability 15 "Not Available" 14 "Error" 13 "SAE Reserved" 12 "SAE Reserved" 11 "SAE Reserved" 10 "SAE Reserved" 9 "SAE Reserved" 8 "SAE Reserved" 7 "SAE Reserved" 6 "SAE Reserved" 5 "High voltage DC bus disconnect forewarning" 4 "SAE Reserved" 3 "High voltage DC bus disconnection is in process" 2 "High voltage DC bus connection is in process of being connected." 1 "High voltage DC bus is connected." 0 "High voltage DC bus is not connected." ;
VAL_ 2566614014 AuxiliariesAvailability 15 "Not Available" 14 "Error" 13 "SAE Reserved" 12 "SAE Reserved" 11 "SAE Reserved" 10 "SAE Reserved" 9 "SAE Reserved" 8 "SAE Reserved" 7 "SAE Reserved" 6 "SAE Reserved" 5 "High voltage DC bus disconnect forewarning" 4 "SAE Reserved" 3 "High voltage DC bus disconnection is in process" 2 "High voltage DC bus connection is in process of being connected." 1 "High voltage DC bus is connected." 0 "High voltage DC bus is not connected." ;
VAL_ 2566614014 DrivelineAvailability 15 "Not Available" 14 "Error" 13 "SAE Reserved" 12 "SAE Reserved" 11 "SAE Reserved" 10 "SAE Reserved" 9 "SAE Reserved" 8 "SAE Reserved" 7 "SAE Reserved" 6 "SAE Reserved" 5 "High voltage DC bus disconnect forewarning" 4 "SAE Reserved" 3 "High voltage DC bus disconnection is in process" 2 "High voltage DC bus connection is in process of being connected." 1 "High voltage DC bus is connected." 0 "High voltage DC bus is not connected." ;
VAL_ 2566614014 DCBusAvailability 15 "Not Available" 14 "Error" 13 "SAE Reserved" 12 "SAE Reserved" 11 "SAE Reserved" 10 "SAE Reserved" 9 "SAE Reserved" 8 "SAE Reserved" 7 "SAE Reserved" 6 "SAE Reserved" 5 "High voltage DC bus disconnect forewarning" 4 "SAE Reserved" 3 "High voltage DC bus disconnection is in process" 2 "High voltage DC bus connection is in process of being connected to at least one power source." 1 "High voltage DC bus is connected to at least one power source." 0 "High voltage DC bus is not connected to any power source." ;
VAL_ 2566613758 HVBusPassiveIsolTestStatus 15 "Not available" 14 "Error" 13 "Reserved" 12 "Reserved" 11 "Reserved" 10 "Reserved" 9 "Reserved" 8 "Reserved" 7 "Reserved" 6 "Passive Isolation Test Inhibited" 5 "Test complete,  isolation fault" 4 "Test complete,  isolation marginal" 3 "Test complete,  isolation acceptable" 2 "Test in process" 1 "Test requested but not yet in process" 0 "No test requested / No test in process" ;
VAL_ 2566613758 HVBusActiveIsolTestStatus 15 "Not available" 14 "Error" 13 "Reserved" 12 "Reserved" 11 "Reserved" 10 "Reserved" 9 "Reserved" 8 "Reserved" 7 "Reserved" 6 "Active Isolation Test Inhibited" 5 "Test complete,  isolation fault" 4 "Test complete,  isolation marginal" 3 "Test complete,  isolation acceptable" 2 "Test in process" 1 "Test requested but not yet in process" 0 "No test requested / No test in process" ;
VAL_ 2566613502 TrqLimDueToMachineCharacteristic 3 "Not Available" 2 "Error" 1 "Torque limited for this reason" 0 "No torque limit for this reason" ;
VAL_ 2566613502 PLedDueToActiveSpdRateLmt 3 "Not Available" 2 "Error" 1 "Power limited for this reason" 0 "No power limit for this reason" ;
VAL_ 2566613502 PLedDueToActiveTrqRateLmt 3 "Not Available" 2 "Error" 1 "Power limited for this reason" 0 "No power limit for this reason" ;
VAL_ 2566613502 PLedDueToFaultCondition 3 "Not Available" 2 "Error" 1 "Power limited for this reason" 0 "No power limit for this reason" ;
VAL_ 2566613502 PLedDueToMotorTemp 3 "Not Available" 2 "Error" 1 "Power limited for this reason" 0 "No power limit for this reason" ;
VAL_ 2566613502 PLedDueToInvTemp 3 "Not Available" 2 "Error" 1 "Power limited for this reason" 0 "No power limit for this reason" ;
VAL_ 2566613502 PLedDueToSpdMin 3 "Not Available" 2 "Error" 1 "Power limited for this reason" 0 "No power limit for this reason" ;
VAL_ 2566613502 PLedDueToSpdMax 3 "Not Available" 2 "Error" 1 "Power limited for this reason" 0 "No power limit for this reason" ;
VAL_ 2566613502 PLedDueToTrqMin 3 "Not Available" 2 "Error" 1 "Power limited for this reason" 0 "No power limit for this reason" ;
VAL_ 2566613502 PLedDueToTrqMax 3 "Not Available" 2 "Error" 1 "Power limited for this reason" 0 "No power limit for this reason" ;
VAL_ 2566613502 PLedDueToDCSidePwrMin 3 "Not Available" 2 "Error" 1 "Power limited for this reason" 0 "No power limit for this reason" ;
VAL_ 2566613502 PLedDueToDCSidePwrMax 3 "Not Available" 2 "Error" 1 "Power limited for this reason" 0 "No power limit for this reason" ;
VAL_ 2566613502 PLedDueToMechPwrMin 3 "Not Available" 2 "Error" 1 "Power limited for this reason" 0 "No power limit for this reason" ;
VAL_ 2566613502 PLedDueToMechPwrMax 3 "Not Available" 2 "Error" 1 "Power limited for this reason" 0 "No power limit for this reason" ;
VAL_ 2566613502 PLedDueToDCSideVMin 3 "Not Available" 2 "Error" 1 "Power limited for this reason" 0 "No power limit for this reason" ;
VAL_ 2566613502 PLedDueToDCSideVMax 3 "Not Available" 2 "Error" 1 "Power limited for this reason" 0 "No power limit for this reason" ;
VAL_ 2566613502 PLedDueToDCSideCurMin 3 "Not Available" 2 "Error" 1 "Power limited for this reason" 0 "No power limit for this reason" ;
VAL_ 2566613502 PLedDueToDCSideCurMax 3 "Not Available" 2 "Error" 1 "Power limited for this reason" 0 "No power limit for this reason" ;
VAL_ 2566613502 PLedDueToUndefinedReason 3 "Not Available" 2 "Error" 1 "Power limited for this reason" 0 "No power limit for this reason" ;
VAL_ 2566613246 HVBusPassiveIsolTestStatus 15 "Not available" 14 "Error" 13 "Reserved" 12 "Reserved" 11 "Reserved" 10 "Reserved" 9 "Reserved" 8 "Reserved" 7 "Reserved" 6 "Passive Isolation Test Inhibited" 5 "Test complete,  isolation fault" 4 "Test complete,  isolation marginal" 3 "Test complete,  isolation acceptable" 2 "Test in process" 1 "Test requested but not yet in process" 0 "No test requested / No test in process" ;
VAL_ 2566613246 HVBusActiveIsolTestStatus 15 "Not available" 14 "Error" 13 "Reserved" 12 "Reserved" 11 "Reserved" 10 "Reserved" 9 "Reserved" 8 "Reserved" 7 "Reserved" 6 "Active Isolation Test Inhibited" 5 "Test complete,  isolation fault" 4 "Test complete,  isolation marginal" 3 "Test complete,  isolation acceptable" 2 "Test in process" 1 "Test requested but not yet in process" 0 "No test requested / No test in process" ;
